VERSION "HNNBNNNYNNNNNNNNNNNNNNNNNNNNNNNNNNNNNNNNNN/4/%%%/4/'%**4NNN///"

NS_ :

BS_:

BU_: BAP_Tester conBox Gateway Gateway_PAG OTA_FC

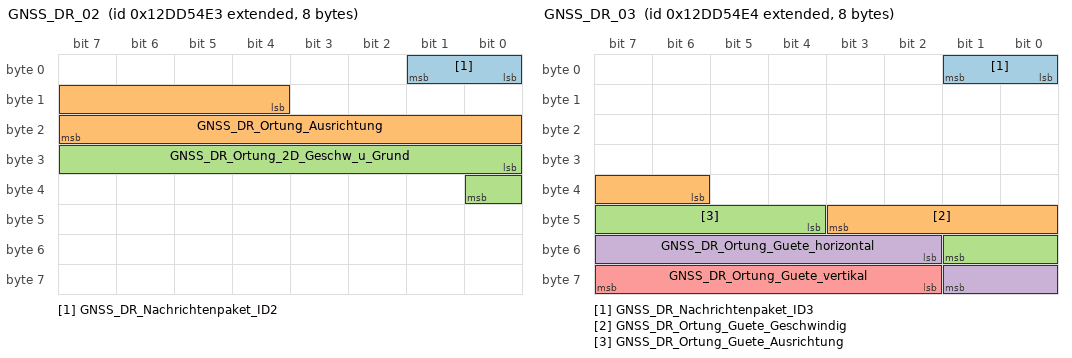
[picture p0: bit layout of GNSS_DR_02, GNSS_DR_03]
BO_ 2463978723 GNSS_DR_02: 8 conBox
 SG_ GNSS_DR_Nachrichtenpaket_ID2 : 0|2@1+ (1,0) [0|3] "Unit_Bit"  Gateway,Gateway_PAG
 SG_ GNSS_DR_Ortung_Ausrichtung : 12|12@1+ (0.1,0) [0.0|359.9] "Unit_DegreOfArc"  Gateway,Gateway_PAG
 SG_ GNSS_DR_Ortung_2D_Geschw_u_Grund : 24|9@1+ (0.25,0) [0.00|125.00] "Unit_MeterPerSecon"  Gateway,Gateway_PAG

BO_ 2463978724 GNSS_DR_03: 8 conBox
 SG_ GNSS_DR_Nachrichtenpaket_ID3 : 0|2@1+ (1,0) [0|3] "Unit_Bit"  Gateway,Gateway_PAG
 SG_ GNSS_DR_Ortung_Guete_Geschwindig : 38|6@1+ (0.05,0) [0.00|3.05] "Unit_MeterPerSecon"  Gateway,Gateway_PAG
 SG_ GNSS_DR_Ortung_Guete_Ausrichtung : 44|6@1+ (0.15,0) [0.00|9.15] "Unit_DegreOfArc"  Gateway,Gateway_PAG
 SG_ GNSS_DR_Ortung_Guete_horizontal : 50|8@1+ (1,0) [0|250] "Unit_Meter"  Gateway,Gateway_PAG
 SG_ GNSS_DR_Ortung_Guete_vertikal : 58|6@1+ (2,0) [0|122] "Unit_Meter"  Gateway,Gateway_PAG

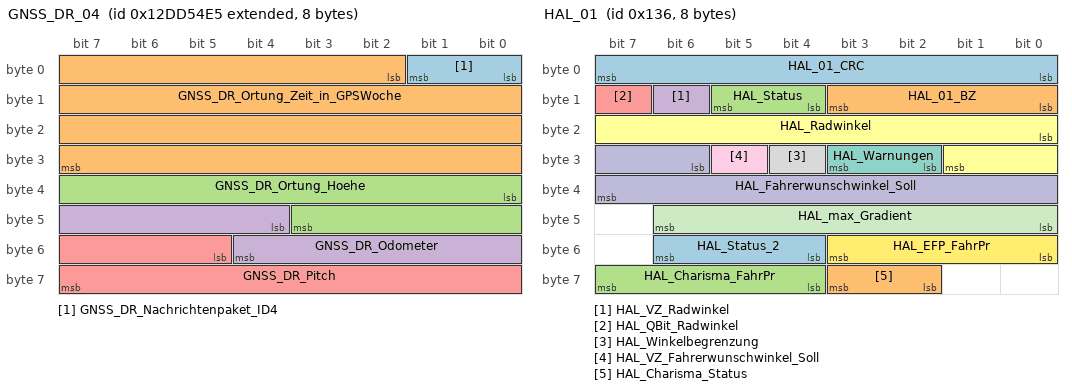
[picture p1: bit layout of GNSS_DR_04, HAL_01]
BO_ 2463978725 GNSS_DR_04: 8 conBox
 SG_ GNSS_DR_Nachrichtenpaket_ID4 : 0|2@1+ (1,0) [0|3] "Unit_Bit"  Gateway,Gateway_PAG
 SG_ GNSS_DR_Ortung_Zeit_in_GPSWoche : 2|30@1+ (1,0) [0|604800001] "Unit_MilliSecon"  Gateway,Gateway_PAG
 SG_ GNSS_DR_Ortung_Hoehe : 32|12@1+ (2,-500) [-500|7686] "Unit_Meter"  Gateway,Gateway_PAG
 SG_ GNSS_DR_Odometer : 44|9@1+ (2,0) [0|1018] "Unit_MilliMeter"  Gateway,Gateway_PAG
 SG_ GNSS_DR_Pitch : 53|11@1+ (0.05,-51.2) [-51.20|51.05] "Unit_DegreOfArc"  Gateway,Gateway_PAG

BO_ 2463978726 GNSS_DR_05: 8 conBox
 SG_ GNSS_DR_UTC_Zeit : 0|32@1+ (1,0) [1|4294967295] "Unit_Secon"  Gateway,Gateway_PAG
 SG_ GNSS_DR_Nachrichtenpaket_ID5 : 32|2@1+ (1,0) [0|3] "Unit_Bit"  Gateway,Gateway_PAG

BO_ 310 HAL_01: 8 Gateway
 SG_ HAL_01_CRC : 0|8@1+ (1,0) [0|255] ""  Vector__XXX
 SG_ HAL_01_BZ : 8|4@1+ (1,0) [0|15] ""  Vector__XXX
 SG_ HAL_Status : 12|2@1+ (1.0,0.0) [0.0|3] ""  Vector__XXX
 SG_ HAL_VZ_Radwinkel : 14|1@1+ (1.0,0.0) [0.0|1] ""  conBox
 SG_ HAL_QBit_Radwinkel : 15|1@1+ (1.0,0.0) [0.0|1] ""  Vector__XXX
 SG_ HAL_Radwinkel : 16|10@1+ (0.01,0) [0.00|10.19] "Unit_DegreOfArc"  conBox
 SG_ HAL_Warnungen : 26|2@1+ (1.0,0.0) [0.0|3] ""  Vector__XXX
 SG_ HAL_Winkelbegrenzung : 28|1@1+ (1.0,0.0) [0.0|1] ""  Vector__XXX
 SG_ HAL_VZ_Fahrerwunschwinkel_Soll : 29|1@1+ (1.0,0.0) [0.0|1] ""  Vector__XXX
 SG_ HAL_Fahrerwunschwinkel_Soll : 30|10@1+ (0.01,0) [0.00|10.21] "Unit_DegreOfArc"  Vector__XXX
 SG_ HAL_max_Gradient : 40|7@1+ (0.1,0) [0.0|12.5] "Unit_DegreOfArcPerSecon"  Vector__XXX
 SG_ HAL_EFP_FahrPr : 48|4@1+ (1.0,0.0) [0.0|15] ""  Vector__XXX
 SG_ HAL_Status_2 : 52|3@1+ (1.0,0.0) [0.0|7] ""  Vector__XXX
 SG_ HAL_Charisma_Status : 58|2@1+ (1.0,0.0) [0.0|3] ""  Vector__XXX
 SG_ HAL_Charisma_FahrPr : 60|4@1+ (1.0,0.0) [0.0|15] ""  Vector__XXX

BO_ 29 IMMO_Auth_Master_Slave07: 8 Gateway
 SG_ IMMO_Auth_Master_Slave07_Sig1 : 0|64@1+ (1.0,0.0) [0.0|18446744073709551615] ""  conBox

BO_ 28 IMMO_Auth_Slave07_Master: 8 conBox
 SG_ IMMO_Auth_Slave07_Master_Sig1 : 0|64@1+ (1.0,0.0) [0.0|18446744073709551615] ""  Gateway,Gateway_PAG

BO_ 960 Klemmen_Status_01: 4 Gateway
 SG_ Klemmen_Status_01_CRC : 0|8@1+ (1,0) [0|255] ""  Vector__XXX
 SG_ Klemmen_Status_01_BZ : 8|4@1+ (1,0) [0|15] ""  Vector__XXX
 SG_ RSt_Fahrerhinweise : 12|4@1+ (1.0,0.0) [0.0|15] ""  Vector__XXX
 SG_ ZAS_Kl_S : 16|1@1+ (1.0,0.0) [0.0|1] ""  conBox
 SG_ ZAS_Kl_15 : 17|1@1+ (1.0,0.0) [0.0|1] ""  conBox
 SG_ ZAS_Kl_X : 18|1@1+ (1.0,0.0) [0.0|1] ""  Vector__XXX
 SG_ ZAS_Kl_50_Startanforderung : 19|1@1+ (1.0,0.0) [0.0|1] ""  Vector__XXX
 SG_ BCM_Remotestart_Betrieb : 20|1@1+ (1.0,0.0) [0.0|1] ""  Vector__XXX
 SG_ ZAS_Kl_Infotainment : 21|1@1+ (1.0,0.0) [0.0|1] ""  Vector__XXX
 SG_ BCM_Remotestart_KL15_Anf : 22|1@1+ (1.0,0.0) [0.0|1] ""  Vector__XXX
 SG_ BCM_Remotestart_MO_Start : 23|1@1+ (1.0,0.0) [0.0|1] ""  Vector__XXX
 SG_ KST_Warn_P1_ZST_def : 24|1@1+ (1.0,0.0) [0.0|1] ""  Vector__XXX
 SG_ KST_Warn_P2_ZST_def : 25|1@1+ (1.0,0.0) [0.0|1] ""  Vector__XXX
 SG_ KST_Fahrerhinweis_1 : 26|1@1+ (1.0,0.0) [0.0|1] ""  Vector__XXX
 SG_ KST_Fahrerhinweis_2 : 27|1@1+ (1.0,0.0) [0.0|1] ""  Vector__XXX
 SG_ BCM_Ausparken_Betrieb : 28|1@1+ (1.0,0.0) [0.0|1] ""  Vector__XXX
 SG_ KST_Fahrerhinweis_4 : 29|1@1+ (1.0,0.0) [0.0|1] ""  Vector__XXX
 SG_ KST_Fahrerhinweis_5 : 30|1@1+ (1.0,0.0) [0.0|1] ""  Vector__XXX
 SG_ KST_Fahrerhinweis_6 : 31|1@1+ (1.0,0.0) [0.0|1] ""  Vector__XXX

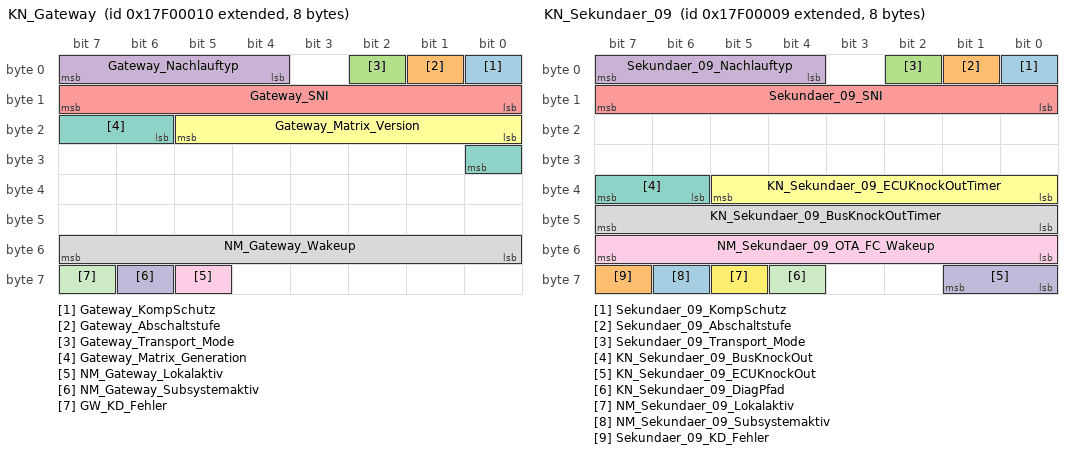
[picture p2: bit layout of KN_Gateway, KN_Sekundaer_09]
BO_ 2549088272 KN_Gateway: 8 Gateway
 SG_ Gateway_KompSchutz : 0|1@1+ (1.0,0.0) [0.0|1] ""  Vector__XXX
 SG_ Gateway_Abschaltstufe : 1|1@1+ (1.0,0.0) [0.0|1] ""  Vector__XXX
 SG_ Gateway_Transport_Mode : 2|1@1+ (1.0,0.0) [0.0|1] ""  Vector__XXX
 SG_ Gateway_Nachlauftyp : 4|4@1+ (1.0,0.0) [0.0|15] ""  Vector__XXX
 SG_ Gateway_SNI : 8|8@1+ (1.0,0.0) [0.0|255] ""  Vector__XXX
 SG_ Gateway_Matrix_Version : 16|6@1+ (1,0) [0|63] "Unit_None"  Vector__XXX
 SG_ Gateway_Matrix_Generation : 22|3@1+ (1,0) [0|7] "Unit_None"  Vector__XXX
 SG_ NM_Gateway_Wakeup : 48|8@1+ (1.0,0.0) [0.0|255] ""  Vector__XXX
 SG_ NM_Gateway_Lokalaktiv : 61|1@1+ (1.0,0.0) [0.0|1] ""  Vector__XXX
 SG_ NM_Gateway_Subsystemaktiv : 62|1@1+ (1.0,0.0) [0.0|1] ""  Vector__XXX
 SG_ GW_KD_Fehler : 63|1@1+ (1.0,0.0) [0.0|1] ""  Vector__XXX

BO_ 2549088265 KN_Sekundaer_09: 8 OTA_FC
 SG_ Sekundaer_09_KompSchutz : 0|1@1+ (1.0,0.0) [0.0|1] ""  Vector__XXX
 SG_ Sekundaer_09_Abschaltstufe : 1|1@1+ (1.0,0.0) [0.0|1] ""  Vector__XXX
 SG_ Sekundaer_09_Transport_Mode : 2|1@1+ (1.0,0.0) [0.0|1] ""  Vector__XXX
 SG_ Sekundaer_09_Nachlauftyp : 4|4@1+ (1.0,0.0) [0.0|15] ""  Gateway_PAG
 SG_ Sekundaer_09_SNI : 8|8@1+ (1.0,0.0) [0.0|255] ""  Gateway_PAG
 SG_ KN_Sekundaer_09_ECUKnockOutTimer : 32|6@1+ (1,0) [0|62] "Unit_Minut"  Gateway_PAG
 SG_ KN_Sekundaer_09_BusKnockOut : 38|2@1+ (1.0,0.0) [0.0|3] ""  Gateway_PAG
 SG_ KN_Sekundaer_09_BusKnockOutTimer : 40|8@1+ (1,0) [0|254] ""  Gateway_PAG
 SG_ NM_Sekundaer_09_OTA_FC_Wakeup : 48|8@1+ (1.0,0.0) [0.0|255] ""  Vector__XXX
 SG_ KN_Sekundaer_09_ECUKnockOut : 56|2@1+ (1.0,0.0) [0.0|3] ""  Gateway_PAG
 SG_ KN_Sekundaer_09_DiagPfad : 60|1@1+ (1.0,0.0) [0.0|1] ""  Vector__XXX
 SG_ NM_Sekundaer_09_Lokalaktiv : 61|1@1+ (1.0,0.0) [0.0|1] ""  Gateway_PAG
 SG_ NM_Sekundaer_09_Subsystemaktiv : 62|1@1+ (1.0,0.0) [0.0|1] ""  Gateway_PAG
 SG_ Sekundaer_09_KD_Fehler : 63|1@1+ (1.0,0.0) [0.0|1] ""  Gateway_PAG

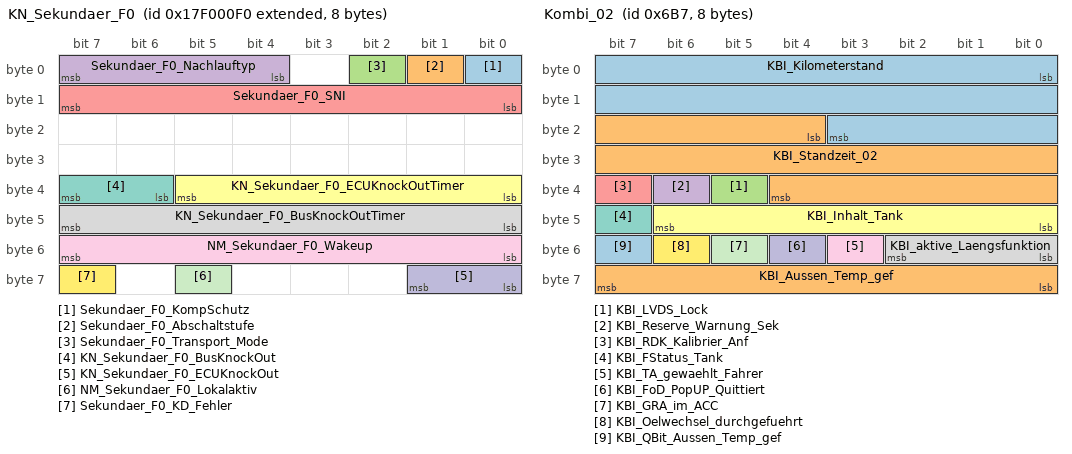
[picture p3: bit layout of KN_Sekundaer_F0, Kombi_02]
BO_ 2549088496 KN_Sekundaer_F0: 8 conBox
 SG_ Sekundaer_F0_KompSchutz : 0|1@1+ (1.0,0.0) [0.0|1] ""  Vector__XXX
 SG_ Sekundaer_F0_Abschaltstufe : 1|1@1+ (1.0,0.0) [0.0|1] ""  Vector__XXX
 SG_ Sekundaer_F0_Transport_Mode : 2|1@1+ (1.0,0.0) [0.0|1] ""  Vector__XXX
 SG_ Sekundaer_F0_Nachlauftyp : 4|4@1+ (1.0,0.0) [0.0|15] ""  Gateway,Gateway_PAG
 SG_ Sekundaer_F0_SNI : 8|8@1+ (1.0,0.0) [0.0|255] ""  Gateway,Gateway_PAG
 SG_ KN_Sekundaer_F0_ECUKnockOutTimer : 32|6@1+ (1,0) [0|62] "Unit_Minut"  Gateway,Gateway_PAG
 SG_ KN_Sekundaer_F0_BusKnockOut : 38|2@1+ (1.0,0.0) [0.0|3] ""  Gateway,Gateway_PAG
 SG_ KN_Sekundaer_F0_BusKnockOutTimer : 40|8@1+ (1,0) [0|254] ""  Gateway,Gateway_PAG
 SG_ NM_Sekundaer_F0_Wakeup : 48|8@1+ (1.0,0.0) [0.0|255] ""  Gateway
 SG_ KN_Sekundaer_F0_ECUKnockOut : 56|2@1+ (1.0,0.0) [0.0|3] ""  Gateway,Gateway_PAG
 SG_ NM_Sekundaer_F0_Lokalaktiv : 61|1@1+ (1.0,0.0) [0.0|1] ""  Gateway,Gateway_PAG
 SG_ Sekundaer_F0_KD_Fehler : 63|1@1+ (1.0,0.0) [0.0|1] ""  Gateway,Gateway_PAG

BO_ 779 Kombi_01: 8 Gateway
 SG_ KBI_ABS_Lampe : 0|1@1+ (1.0,0.0) [0.0|1] ""  Vector__XXX
 SG_ KBI_ESP_Lampe : 1|1@1+ (1.0,0.0) [0.0|1] ""  Vector__XXX
 SG_ KBI_BKL_Lampe : 2|1@1+ (1.0,0.0) [0.0|1] ""  Vector__XXX
 SG_ KBI_Airbag_Lampe : 3|1@1+ (1.0,0.0) [0.0|1] ""  Vector__XXX
 SG_ KBI_SILA_gueltig : 4|1@1+ (1.0,0.0) [0.0|1] ""  Vector__XXX
 SG_ KBI_Lenkung_Lampe : 5|1@1+ (1,0) [0|1] ""  Vector__XXX
 SG_ KBI_Vorglueh_System_Lampe : 6|1@1+ (1.0,0.0) [0.0|1] ""  Vector__XXX
 SG_ KBI_NV_in_Anzeige : 7|1@1+ (1.0,0.0) [0.0|1] ""  Vector__XXX
 SG_ Kombi_01_BZ : 8|4@1+ (1,0) [0|15] ""  Vector__XXX
 SG_ KBI_Anzeigestatus_ACC : 12|1@1+ (1.0,0.0) [0.0|1] ""  Vector__XXX
 SG_ KBI_Anzeigestatus_GRA : 13|2@1+ (1.0,0.0) [0.0|3] ""  Vector__XXX
 SG_ KBI_Tankwarnung : 16|1@1+ (1.0,0.0) [0.0|1] ""  Vector__XXX
 SG_ KBI_MFA_v_Einheit_01 : 17|1@1+ (1.0,0.0) [0.0|1] ""  Vector__XXX
 SG_ KBI_im_Stellgliedtest : 18|1@1+ (1.0,0.0) [0.0|1] ""  Vector__XXX
 SG_ KBI_Anzeigefehler_LDW : 19|2@1+ (1.0,0.0) [0.0|3] ""  Vector__XXX
 SG_ KBI_Tankwarnung_ungueltig : 21|1@1+ (1.0,0.0) [0.0|1] ""  Vector__XXX
 SG_ KBI_Handbremse : 23|1@1+ (1.0,0.0) [0.0|1] ""  Vector__XXX
 SG_ KBI_V_Digital : 24|9@1+ (1,0) [0|511] ""  Vector__XXX
 SG_ KBI_PLA_in_Anzeige : 33|1@1+ (1.0,0.0) [0.0|1] ""  Vector__XXX
 SG_ KBI_Anzeigefehler_NV : 34|1@1+ (1.0,0.0) [0.0|1] ""  Vector__XXX
 SG_ KBI_Anzeigestatus_LIM : 35|2@1+ (1.0,0.0) [0.0|3] ""  Vector__XXX
 SG_ KBI_ARA_in_Anzeige : 37|1@1+ (1.0,0.0) [0.0|1] ""  Vector__XXX
 SG_ KBI_Taster_Lift : 38|1@1+ (1.0,0.0) [0.0|1] ""  Vector__XXX
 SG_ KBI_Taster_Fahrwerk : 39|1@1+ (1.0,0.0) [0.0|1] ""  Vector__XXX
 SG_ KBI_GRA_Hauptschalter : 40|2@1+ (1.0,0.0) [0.0|3] ""  Vector__XXX
 SG_ KBI_Bestaetigung_ESP_Off : 42|2@1+ (1.0,0.0) [0.0|3] ""  Vector__XXX
 SG_ KBI_angez_Geschw : 48|10@1+ (0.32,0) [0.00|325.12] "Unit_KiloMeterPerHour"  conBox
 SG_ KBI_Einheit_Tacho : 58|1@1+ (1.0,0.0) [0.0|1] ""  conBox
 SG_ KBI_Konsistenz_ACC : 59|1@1+ (1.0,0.0) [0.0|1] ""  Vector__XXX
 SG_ KBI_Fehler_Anzeige_ACC : 60|1@1+ (1.0,0.0) [0.0|1] ""  Vector__XXX
 SG_ KBI_Anzeigefehler_SWA : 61|2@1+ (1.0,0.0) [0.0|3] ""  Vector__XXX
 SG_ KBI_Systemstatus : 63|1@1+ (1.0,0.0) [0.0|1] ""  Vector__XXX

BO_ 1719 Kombi_02: 8 Gateway
 SG_ KBI_Kilometerstand : 0|20@1+ (1,0) [0|1048573] "Unit_KiloMeter"  Vector__XXX
 SG_ KBI_Standzeit_02 : 20|17@1+ (1,0) [0|131068] "Unit_Secon"  Vector__XXX
 SG_ KBI_LVDS_Lock : 37|1@1+ (1.0,0.0) [0.0|1] ""  Vector__XXX
 SG_ KBI_Reserve_Warnung_Sek : 38|1@1+ (1.0,0.0) [0.0|1] ""  Vector__XXX
 SG_ KBI_RDK_Kalibrier_Anf : 39|1@1+ (1.0,0.0) [0.0|1] ""  Vector__XXX
 SG_ KBI_Inhalt_Tank : 40|7@1+ (1,0) [0|125] "Unit_Liter"  conBox
 SG_ KBI_FStatus_Tank : 47|1@1+ (1.0,0.0) [0.0|1] ""  conBox
 SG_ KBI_aktive_Laengsfunktion : 48|3@1+ (1.0,0.0) [0.0|7] ""  Vector__XXX
 SG_ KBI_TA_gewaehlt_Fahrer : 51|1@1+ (1.0,0.0) [0.0|1] ""  Vector__XXX
 SG_ KBI_FoD_PopUP_Quittiert : 52|1@1+ (1.0,0.0) [0.0|1] ""  Vector__XXX
 SG_ KBI_GRA_im_ACC : 53|1@1+ (1.0,0.0) [0.0|1] ""  Vector__XXX
 SG_ KBI_Oelwechsel_durchgefuehrt : 54|1@1+ (1.0,0.0) [0.0|1] ""  Vector__XXX
 SG_ KBI_QBit_Aussen_Temp_gef : 55|1@1+ (1.0,0.0) [0.0|1] ""  Vector__XXX
 SG_ KBI_Aussen_Temp_gef : 56|8@1+ (0.5,-50) [-50.0|75.0] "Unit_DegreCelsi"  Vector__XXX

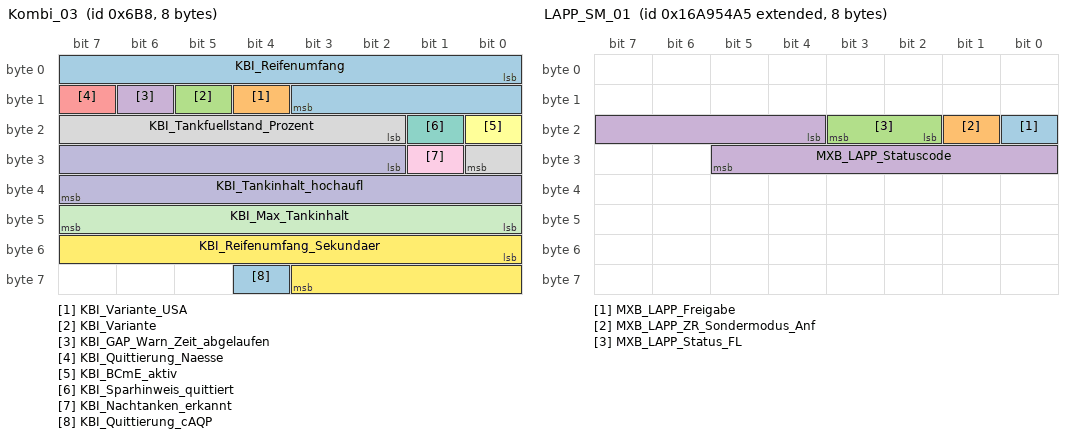
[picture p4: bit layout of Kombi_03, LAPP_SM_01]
BO_ 1720 Kombi_03: 8 Gateway
 SG_ KBI_Reifenumfang : 0|12@1+ (1,0) [0|4095] "Unit_MilliMeter"  Vector__XXX
 SG_ KBI_Variante_USA : 12|1@1+ (1.0,0.0) [0.0|1] ""  Vector__XXX
 SG_ KBI_Variante : 13|1@1+ (1.0,0.0) [0.0|1] ""  Vector__XXX
 SG_ KBI_GAP_Warn_Zeit_abgelaufen : 14|1@1+ (1.0,0.0) [0.0|1] ""  Vector__XXX
 SG_ KBI_Quittierung_Naesse : 15|1@1+ (1.0,0.0) [0.0|1] ""  Vector__XXX
 SG_ KBI_BCmE_aktiv : 16|1@1+ (1.0,0.0) [0.0|1] ""  Vector__XXX
 SG_ KBI_Sparhinweis_quittiert : 17|1@1+ (1.0,0.0) [0.0|1] ""  Vector__XXX
 SG_ KBI_Tankfuellstand_Prozent : 18|7@1+ (1,0) [0|100] "Unit_PerCent"  conBox
 SG_ KBI_Nachtanken_erkannt : 25|1@1+ (1.0,0.0) [0.0|1] ""  Vector__XXX
 SG_ KBI_Tankinhalt_hochaufl : 26|14@1+ (0.01,0) [0.00|163.81] "Unit_Liter"  Vector__XXX
 SG_ KBI_Max_Tankinhalt : 40|8@1+ (0.5,0) [0.0|126.5] ""  Vector__XXX
 SG_ KBI_Reifenumfang_Sekundaer : 48|12@1+ (1,0) [0|4095] "Unit_MilliMeter"  Vector__XXX
 SG_ KBI_Quittierung_cAQP : 60|1@1+ (1.0,0.0) [0.0|1] ""  Vector__XXX

BO_ 2549875047 KS_eCall_Req: 8 Gateway
 SG_ KS_eCall_Req_Data : 0|64@1+ (1.0,0.0) [0.0|18446744073709551615] ""  conBox

BO_ 2550006119 KS_eCall_Resp: 8 conBox
 SG_ KS_eCall_Resp_Data : 0|64@1+ (1.0,0.0) [0.0|18446744073709551615] ""  Gateway,Gateway_PAG

BO_ 2549875078 KS_OTA_FC_Req: 8 Gateway_PAG
 SG_ KS_OTA_FC_Req_Data : 0|64@1+ (1.0,0.0) [0.0|18446744073709551615] ""  OTA_FC

BO_ 2550006150 KS_OTA_FC_Resp: 8 OTA_FC
 SG_ KS_OTA_FC_Resp_Data : 0|64@1+ (1.0,0.0) [0.0|18446744073709551615] ""  Gateway_PAG

BO_ 2527679653 LAPP_SM_01: 8 Gateway
 SG_ MXB_LAPP_Freigabe : 16|1@1+ (1.0,0.0) [0.0|1] ""  conBox
 SG_ MXB_LAPP_ZR_Sondermodus_Anf : 17|1@1+ (1.0,0.0) [0.0|1] ""  Vector__XXX
 SG_ MXB_LAPP_Status_FL : 18|2@1+ (1.0,0.0) [0.0|3] ""  conBox
 SG_ MXB_LAPP_Statuscode : 20|10@1+ (1,0) [0|1023] "Unit_None"  conBox

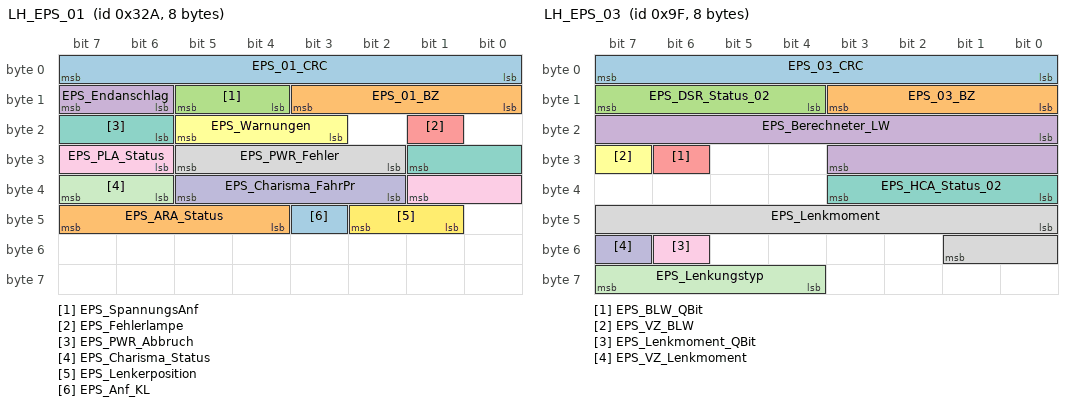
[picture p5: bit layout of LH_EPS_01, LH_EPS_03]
BO_ 810 LH_EPS_01: 8 Gateway
 SG_ EPS_01_CRC : 0|8@1+ (1,0) [0|255] ""  Vector__XXX
 SG_ EPS_01_BZ : 8|4@1+ (1,0) [0|15] ""  Vector__XXX
 SG_ EPS_SpannungsAnf : 12|2@1+ (1.0,0.0) [0.0|3] ""  Vector__XXX
 SG_ EPS_Endanschlag : 14|2@1+ (1.0,0.0) [0.0|3] ""  Vector__XXX
 SG_ EPS_Fehlerlampe : 17|1@1+ (1.0,0.0) [0.0|1] ""  Vector__XXX
 SG_ EPS_Warnungen : 19|3@1+ (1.0,0.0) [0.0|7] ""  Vector__XXX
 SG_ EPS_PWR_Abbruch : 22|4@1+ (1.0,0.0) [0.0|15] ""  Vector__XXX
 SG_ EPS_PWR_Fehler : 26|4@1+ (1.0,0.0) [0.0|15] ""  Vector__XXX
 SG_ EPS_PLA_Status : 30|4@1+ (1.0,0.0) [0.0|15] ""  Vector__XXX
 SG_ EPS_Charisma_FahrPr : 34|4@1+ (1.0,0.0) [0.0|15] ""  Vector__XXX
 SG_ EPS_Charisma_Status : 38|2@1+ (1.0,0.0) [0.0|3] ""  Vector__XXX
 SG_ EPS_Lenkerposition : 41|2@1+ (1.0,0.0) [0.0|3] ""  conBox
 SG_ EPS_Anf_KL : 43|1@1+ (1.0,0.0) [0.0|1] ""  Vector__XXX
 SG_ EPS_ARA_Status : 44|4@1+ (1.0,0.0) [0.0|15] ""  Vector__XXX

BO_ 159 LH_EPS_03: 8 Gateway
 SG_ EPS_03_CRC : 0|8@1+ (1,0) [0|255] ""  Vector__XXX
 SG_ EPS_03_BZ : 8|4@1+ (1,0) [0|15] ""  Vector__XXX
 SG_ EPS_DSR_Status_02 : 12|4@1+ (1.0,0.0) [0.0|15] ""  Vector__XXX
 SG_ EPS_Berechneter_LW : 16|12@1+ (0.15,0) [0.00|613.95] "Unit_DegreOfArc"  conBox
 SG_ EPS_BLW_QBit : 30|1@1+ (1.0,0.0) [0.0|1] ""  Vector__XXX
 SG_ EPS_VZ_BLW : 31|1@1+ (1.0,0.0) [0.0|1] ""  conBox
 SG_ EPS_HCA_Status_02 : 32|4@1+ (1.0,0.0) [0.0|15] ""  Vector__XXX
 SG_ EPS_Lenkmoment : 40|10@1+ (0.01,0) [0.00|8.00] "Unit_NewtoMeter"  Vector__XXX
 SG_ EPS_Lenkmoment_QBit : 54|1@1+ (1.0,0.0) [0.0|1] ""  Vector__XXX
 SG_ EPS_VZ_Lenkmoment : 55|1@1+ (1.0,0.0) [0.0|1] ""  Vector__XXX
 SG_ EPS_Lenkungstyp : 60|4@1+ (1.0,0.0) [0.0|15] ""  Vector__XXX

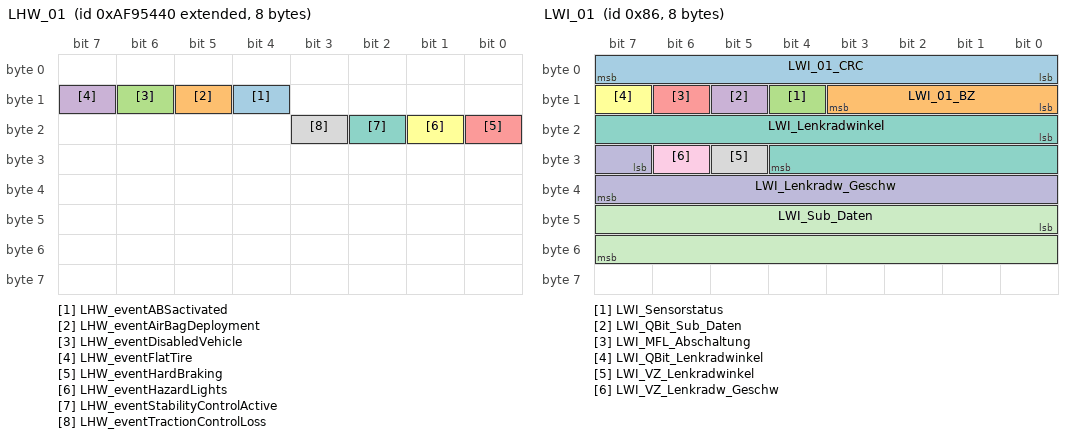
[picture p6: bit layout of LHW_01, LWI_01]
BO_ 2331595840 LHW_01: 8 Gateway
 SG_ LHW_eventABSactivated : 12|1@1+ (1.0,0.0) [0.0|1] ""  conBox
 SG_ LHW_eventAirBagDeployment : 13|1@1+ (1.0,0.0) [0.0|1] ""  conBox
 SG_ LHW_eventDisabledVehicle : 14|1@1+ (1.0,0.0) [0.0|1] ""  conBox
 SG_ LHW_eventFlatTire : 15|1@1+ (1.0,0.0) [0.0|1] ""  conBox
 SG_ LHW_eventHardBraking : 16|1@1+ (1.0,0.0) [0.0|1] ""  conBox
 SG_ LHW_eventHazardLights : 17|1@1+ (1.0,0.0) [0.0|1] ""  conBox
 SG_ LHW_eventStabilityControlActive : 18|1@1+ (1.0,0.0) [0.0|1] ""  conBox
 SG_ LHW_eventTractionControlLoss : 19|1@1+ (1.0,0.0) [0.0|1] ""  conBox

BO_ 981 Licht_Anf_01: 8 Gateway
 SG_ Licht_Anf_01_CRC : 0|8@1+ (1,0) [0|255] ""  Vector__XXX
 SG_ Licht_Anf_01_BZ : 8|4@1+ (1,0) [0|15] ""  Vector__XXX
 SG_ BCM1_Kurvenlicht_links_Anf : 12|1@1+ (1.0,0.0) [0.0|1] ""  Vector__XXX
 SG_ BCM1_Kurvenlicht_rechts_Anf : 13|1@1+ (1.0,0.0) [0.0|1] ""  Vector__XXX
 SG_ BCM1_Standlicht_Anf : 14|1@1+ (1.0,0.0) [0.0|1] ""  conBox
 SG_ BCM1_Abblendlicht_Anf : 15|1@1+ (1.0,0.0) [0.0|1] ""  conBox
 SG_ BCM1_Fernlicht_Anf : 16|1@1+ (1.0,0.0) [0.0|1] ""  Vector__XXX
 SG_ BCM1_Nebellicht_Anf : 17|1@1+ (1.0,0.0) [0.0|1] ""  conBox
 SG_ BCM1_Parklicht_li_Anf : 18|1@1+ (1.0,0.0) [0.0|1] ""  conBox
 SG_ BCM1_Parklicht_re_Anf : 19|1@1+ (1.0,0.0) [0.0|1] ""  conBox
 SG_ BCM1_Nebelschluss_Ahg_Anf : 20|1@1+ (1.0,0.0) [0.0|1] ""  conBox
 SG_ BCM1_Nebelschluss_Fzg_Anf : 21|1@1+ (1.0,0.0) [0.0|1] ""  Vector__XXX
 SG_ BCM1_Schlusslicht_Anf : 22|1@1+ (1.0,0.0) [0.0|1] ""  Vector__XXX
 SG_ BCM_Rueckfahrlicht_Anf : 23|1@1+ (1.0,0.0) [0.0|1] ""  conBox
 SG_ BCM1_Signaturlicht_Anf : 24|1@1+ (1.0,0.0) [0.0|1] ""  Vector__XXX
 SG_ BCM1_Umfeldleuchten_Anf : 25|1@1+ (1.0,0.0) [0.0|1] ""  Vector__XXX
 SG_ BCM1_Tagfahrlicht_Anf : 26|1@1+ (1.0,0.0) [0.0|1] ""  conBox
 SG_ BCM1_Regenlicht_Anf : 27|1@1+ (1.0,0.0) [0.0|1] ""  Vector__XXX
 SG_ BCM1_Autobahnlicht_Anf : 28|1@1+ (1.0,0.0) [0.0|1] ""  Vector__XXX
 SG_ BCM1_Touristen_Licht_Anf : 29|1@1+ (1.0,0.0) [0.0|1] ""  Vector__XXX
 SG_ BCM1_CH_aktiv : 30|1@1+ (1.0,0.0) [0.0|1] ""  Vector__XXX
 SG_ BCM1_LH_aktiv : 31|1@1+ (1.0,0.0) [0.0|1] ""  Vector__XXX
 SG_ BCM1_Gleitende_Leuchtw_Anf : 32|1@1+ (1.0,0.0) [0.0|1] ""  Vector__XXX
 SG_ BCM1_GLW_Fernlicht_Anf : 33|1@1+ (1.0,0.0) [0.0|1] ""  Vector__XXX
 SG_ BCM1_Adaptive_Lichtvert_Anf : 34|1@1+ (1.0,0.0) [0.0|1] ""  Vector__XXX
 SG_ BCM1_FoD_Sperrung_WiBli : 35|2@1+ (1.0,0.0) [0.0|3] ""  Vector__XXX
 SG_ BCM1_FOD_Sperrung_Animationen_HL : 37|2@1+ (1.0,0.0) [0.0|3] ""  Vector__XXX
 SG_ BCM1_Animationssperrung : 39|1@1+ (1.0,0.0) [0.0|1] ""  Vector__XXX
 SG_ BCM1_CH_LH_aktiv : 40|1@1+ (1.0,0.0) [0.0|1] ""  Vector__XXX
 SG_ BCM1_Allwetterlicht_Anf : 41|1@1+ (1.0,0.0) [0.0|1] ""  Vector__XXX
 SG_ BCM1_Schlusslicht_Signatur : 60|4@1+ (1.0,0.0) [0.0|15] ""  Vector__XXX

BO_ 1624 Licht_vorne_01: 8 Gateway
 SG_ Licht_Vorne_01_CRC : 0|8@1+ (1,0) [0|255] ""  Vector__XXX
 SG_ Licht_Vorne_01_BZ : 8|4@1+ (1,0) [0|15] ""  Vector__XXX
 SG_ LV_Standlicht_Anzeige : 12|1@1+ (1.0,0.0) [0.0|1] ""  Vector__XXX
 SG_ LV_Abblendlicht_Anzeige : 13|1@1+ (1.0,0.0) [0.0|1] ""  Vector__XXX
 SG_ LV_Fernlicht_Anzeige : 14|1@1+ (1.0,0.0) [0.0|1] ""  conBox
 SG_ LV_Nebellicht_Anzeige : 15|1@1+ (1.0,0.0) [0.0|1] ""  Vector__XXX
 SG_ LV_Nebelschlusslicht_Anzeige : 16|1@1+ (1.0,0.0) [0.0|1] ""  Vector__XXX
 SG_ LV_Tagfahrlicht_Anzeige : 17|1@1+ (1.0,0.0) [0.0|1] ""  Vector__XXX
 SG_ LV_AFL_aktiv_Anzeige : 18|1@1+ (1.0,0.0) [0.0|1] ""  conBox
 SG_ LV_AFL_defekt : 19|1@1+ (1.0,0.0) [0.0|1] ""  Vector__XXX
 SG_ LV_Blinker_li_def : 20|1@1+ (1.0,0.0) [0.0|1] ""  Vector__XXX
 SG_ LV_Standlicht_li_def : 21|1@1+ (1.0,0.0) [0.0|1] ""  Vector__XXX
 SG_ LV_Abblendlicht_li_def : 22|1@1+ (1.0,0.0) [0.0|1] ""  Vector__XXX
 SG_ LV_Fernlicht_li_def : 23|1@1+ (1.0,0.0) [0.0|1] ""  Vector__XXX
 SG_ LV_Nebellicht_li_def : 24|1@1+ (1.0,0.0) [0.0|1] ""  Vector__XXX
 SG_ LV_Blk_li_Seite_def : 25|1@1+ (1.0,0.0) [0.0|1] ""  Vector__XXX
 SG_ LV_Tagfahrlicht_li_def : 26|1@1+ (1.0,0.0) [0.0|1] ""  Vector__XXX
 SG_ LV_FLA_aktiv_Anzeige : 27|1@1+ (1.0,0.0) [0.0|1] ""  Vector__XXX
 SG_ LV_FLA_defekt : 28|1@1+ (1.0,0.0) [0.0|1] ""  Vector__XXX
 SG_ LV_FLA_Sensor_blockiert : 29|1@1+ (1.0,0.0) [0.0|1] ""  Vector__XXX
 SG_ LV_Blinker_re_def : 30|1@1+ (1.0,0.0) [0.0|1] ""  Vector__XXX
 SG_ LV_Standlicht_re_def : 31|1@1+ (1.0,0.0) [0.0|1] ""  Vector__XXX
 SG_ LV_Abblendlicht_re_def : 32|1@1+ (1.0,0.0) [0.0|1] ""  Vector__XXX
 SG_ LV_Fernlicht_re_def : 33|1@1+ (1.0,0.0) [0.0|1] ""  Vector__XXX
 SG_ LV_Nebellicht_re_def : 34|1@1+ (1.0,0.0) [0.0|1] ""  Vector__XXX
 SG_ LV_Blk_re_Seite_def : 35|1@1+ (1.0,0.0) [0.0|1] ""  Vector__XXX
 SG_ LV_Tagfahrlicht_re_def : 36|1@1+ (1.0,0.0) [0.0|1] ""  Vector__XXX
 SG_ LV_Aussenlicht_def : 37|1@1+ (1.0,0.0) [0.0|1] ""  Vector__XXX
 SG_ LV_Abblendlicht_TFL_li_def : 38|1@1+ (1.0,0.0) [0.0|1] ""  Vector__XXX
 SG_ LV_Nebellicht_TFL_li_def : 39|1@1+ (1.0,0.0) [0.0|1] ""  Vector__XXX
 SG_ LV_Standlicht_TFL_li_def : 40|1@1+ (1.0,0.0) [0.0|1] ""  Vector__XXX
 SG_ LV_Abblend_Fernlicht_li_def : 41|1@1+ (1.0,0.0) [0.0|1] ""  Vector__XXX
 SG_ LV_Abblendlicht_TFL_re_def : 42|1@1+ (1.0,0.0) [0.0|1] ""  Vector__XXX
 SG_ LV_Nebellicht_TFL_re_def : 43|1@1+ (1.0,0.0) [0.0|1] ""  Vector__XXX
 SG_ LV_Standlicht_TFL_re_def : 44|1@1+ (1.0,0.0) [0.0|1] ""  Vector__XXX
 SG_ LV_Abblend_Fernlicht_re_def : 45|1@1+ (1.0,0.0) [0.0|1] ""  Vector__XXX
 SG_ LV_Abbiegelicht_li_def : 46|1@1+ (1.0,0.0) [0.0|1] ""  Vector__XXX
 SG_ LV_Abbiegelicht_re_def : 47|1@1+ (1.0,0.0) [0.0|1] ""  Vector__XXX
 SG_ BCM1_Linksverkehr : 48|1@1+ (1.0,0.0) [0.0|1] ""  Vector__XXX
 SG_ BCM1_Licht_Dunkelheit_aktiv : 49|1@1+ (1.0,0.0) [0.0|1] ""  Vector__XXX
 SG_ LV_LED_Scheinwerfer_li_def : 50|1@1+ (1.0,0.0) [0.0|1] ""  Vector__XXX
 SG_ LV_LED_Scheinwerfer_re_def : 51|1@1+ (1.0,0.0) [0.0|1] ""  Vector__XXX
 SG_ LV_Blinker_VL_aktiv : 52|1@1+ (1.0,0.0) [0.0|1] ""  Vector__XXX
 SG_ LV_Blinker_VR_aktiv : 53|1@1+ (1.0,0.0) [0.0|1] ""  Vector__XXX
 SG_ LV_MXB_Status_Anzeige : 54|2@1+ (1.0,0.0) [0.0|3] ""  Vector__XXX

BO_ 134 LWI_01: 8 Gateway
 SG_ LWI_01_CRC : 0|8@1+ (1,0) [0|255] ""  Vector__XXX
 SG_ LWI_01_BZ : 8|4@1+ (1,0) [0|15] ""  Vector__XXX
 SG_ LWI_Sensorstatus : 12|1@1+ (1.0,0.0) [0.0|1] ""  Vector__XXX
 SG_ LWI_QBit_Sub_Daten : 13|1@1+ (1.0,0.0) [0.0|1] ""  Vector__XXX
 SG_ LWI_MFL_Abschaltung : 14|1@1+ (1.0,0.0) [0.0|1] ""  Vector__XXX
 SG_ LWI_QBit_Lenkradwinkel : 15|1@1+ (1.0,0.0) [0.0|1] ""  Vector__XXX
 SG_ LWI_Lenkradwinkel : 16|13@1+ (0.1,0) [0.0|800.0] "Unit_DegreOfArc"  conBox
 SG_ LWI_VZ_Lenkradwinkel : 29|1@1+ (1.0,0.0) [0.0|1] ""  conBox
 SG_ LWI_VZ_Lenkradw_Geschw : 30|1@1+ (1.0,0.0) [0.0|1] ""  Vector__XXX
 SG_ LWI_Lenkradw_Geschw : 31|9@1+ (5,0) [0|2500] "Unit_DegreOfArcPerSecon"  Vector__XXX
 SG_ LWI_Sub_Daten : 40|16@1+ (1,0) [0|65535] ""  Vector__XXX

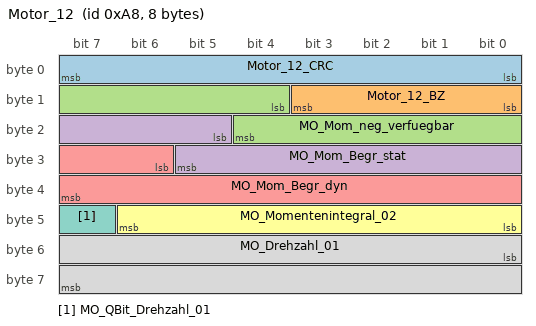
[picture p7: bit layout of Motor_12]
BO_ 168 Motor_12: 8 Gateway
 SG_ Motor_12_CRC : 0|8@1+ (1,0) [0|255] ""  Vector__XXX
 SG_ Motor_12_BZ : 8|4@1+ (1,0) [0|15] ""  Vector__XXX
 SG_ MO_Mom_neg_verfuegbar : 12|9@1+ (1,-509) [-509|0] ""  Vector__XXX
 SG_ MO_Mom_Begr_stat : 21|9@1+ (1,0) [0|509] ""  Vector__XXX
 SG_ MO_Mom_Begr_dyn : 30|10@1+ (1,-509) [-509|509] ""  Vector__XXX
 SG_ MO_Momentenintegral_02 : 40|7@1+ (1,0) [0|100] "Unit_PerCent"  Vector__XXX
 SG_ MO_QBit_Drehzahl_01 : 47|1@1+ (1.0,0.0) [0.0|1] ""  Vector__XXX
 SG_ MO_Drehzahl_01 : 48|16@1+ (0.25,0) [0.00|16383.00] "Unit_MinutInver"  conBox

BO_ 958 Motor_14: 8 Gateway
 SG_ Motor_14_CRC : 0|8@1+ (1,0) [0|255] ""  Vector__XXX
 SG_ Motor_14_BZ : 8|4@1+ (1,0) [0|15] ""  Vector__XXX
 SG_ MO_StartStopp_Status : 12|2@1+ (1.0,0.0) [0.0|3] ""  Vector__XXX
 SG_ MO_StartStopp_Wiederstart : 14|1@1+ (1.0,0.0) [0.0|1] ""  Vector__XXX
 SG_ MO_StartStopp_Motorstopp : 15|1@1+ (1.0,0.0) [0.0|1] ""  Vector__XXX
 SG_ MO_Freig_Reku : 16|2@1+ (1.0,0.0) [0.0|3] ""  Vector__XXX
 SG_ MO_Kl_75 : 18|1@1+ (1.0,0.0) [0.0|1] ""  conBox
 SG_ MO_Kl_50 : 19|1@1+ (1.0,0.0) [0.0|1] ""  conBox
 SG_ MO_Gangposition : 20|4@1+ (1.0,0.0) [0.0|15] ""  conBox
 SG_ MO_StartStopp_Fahrerwunsch : 24|2@1+ (1.0,0.0) [0.0|3] ""  Vector__XXX
 SG_ MO_HYB_Fahrbereitschaft : 26|1@1+ (1.0,0.0) [0.0|1] ""  Vector__XXX
 SG_ MO_Ext_E_Fahrt_aktiv : 27|1@1+ (1.0,0.0) [0.0|1] ""  Vector__XXX
 SG_ MO_Fahrer_bremst : 28|1@1+ (1.0,0.0) [0.0|1] ""  Vector__XXX
 SG_ MO_QBit_Fahrer_bremst : 29|1@1+ (1.0,0.0) [0.0|1] ""  Vector__XXX
 SG_ MO_BLS : 30|1@1+ (1.0,0.0) [0.0|1] ""  Vector__XXX
 SG_ MO_Konsistenz_Bremsped : 31|1@1+ (1.0,0.0) [0.0|1] ""  Vector__XXX
 SG_ MO_KomFehler_ESP : 32|1@1+ (1.0,0.0) [0.0|1] ""  Vector__XXX
 SG_ MO_Klima_Eingr : 33|2@1+ (1.0,0.0) [0.0|3] ""  Vector__XXX
 SG_ MO_Aussp_Anlass : 35|1@1+ (1.0,0.0) [0.0|1] ""  Vector__XXX
 SG_ MO_Freig_Anlass : 36|1@1+ (1.0,0.0) [0.0|1] ""  Vector__XXX
 SG_ MO_Kuppl_schalter : 37|1@1+ (1.0,0.0) [0.0|1] ""  Vector__XXX
 SG_ MO_Interlock : 38|1@1+ (1.0,0.0) [0.0|1] ""  Vector__XXX
 SG_ MO_Motor_laeuft : 39|1@1+ (1.0,0.0) [0.0|1] ""  conBox
 SG_ MO_Kickdown : 40|1@1+ (1.0,0.0) [0.0|1] ""  Vector__XXX
 SG_ MO_QBit_KL_75 : 41|1@1+ (1.0,0.0) [0.0|1] ""  Vector__XXX
 SG_ MO_EKlKomLeiRed : 42|2@1+ (1.0,0.0) [0.0|3] ""  Vector__XXX
 SG_ MO_Handshake_STH : 44|1@1+ (1.0,0.0) [0.0|1] ""  Vector__XXX
 SG_ MO_BKV_Unterdruckwarnung : 45|1@1+ (1.0,0.0) [0.0|1] ""  Vector__XXX
 SG_ MO_Freigabe_Segeln : 46|1@1+ (1.0,0.0) [0.0|1] ""  Vector__XXX
 SG_ MO_PTC_Status : 47|3@1+ (1.0,0.0) [0.0|7] ""  Vector__XXX
 SG_ MO_QBit_Gangposition : 50|1@1+ (1.0,0.0) [0.0|1] ""  Vector__XXX
 SG_ MO_Signalquelle_Gangposition : 51|1@1+ (1.0,0.0) [0.0|1] ""  Vector__XXX
 SG_ MO_Remotestart_Betrieb : 52|1@1+ (1.0,0.0) [0.0|1] ""  Vector__XXX
 SG_ MO_Remotestart_moeglich : 53|1@1+ (1.0,0.0) [0.0|1] ""  Vector__XXX
 SG_ MO_Text_Geschw_red : 54|1@1+ (1.0,0.0) [0.0|1] ""  Vector__XXX
 SG_ MO_FMAus_aktiv : 55|1@1+ (1.0,0.0) [0.0|1] ""  Vector__XXX
 SG_ MO_FMAus_Startvariante : 56|2@1+ (1.0,0.0) [0.0|3] ""  Vector__XXX
 SG_ MO_BMS_NV_Anf_stuetzen : 58|1@1+ (1.0,0.0) [0.0|1] ""  Vector__XXX
 SG_ MO_Zylinderabschaltung : 59|2@1+ (1.0,0.0) [0.0|3] ""  Vector__XXX
 SG_ MO_HYB_VM_aktiv : 61|1@1+ (1.0,0.0) [0.0|1] ""  Vector__XXX
 SG_ MO_StartVorauss_erfuellt : 62|2@1+ (1.0,0.0) [0.0|3] ""  Vector__XXX

BO_ 1648 Motor_18: 8 Gateway
 SG_ MO_max_Ladedruck : 0|6@1+ (0.1,0) [0.0|6.3] "Unit_Bar"  Vector__XXX
 SG_ MO_ANC_Kennfeld_Anf : 6|2@1+ (1.0,0.0) [0.0|3] ""  Vector__XXX
 SG_ MO_Bremslicht_Reku : 8|1@1+ (1.0,0.0) [0.0|1] ""  Vector__XXX
 SG_ MO_StartStopp_PopUp : 9|2@1+ (1.0,0.0) [0.0|3] ""  Vector__XXX
 SG_ MO1_Sperr_Info_WFS : 11|1@1+ (1.0,0.0) [0.0|1] ""  Vector__XXX
 SG_ MO1_Freigabe_Info_WFS : 12|1@1+ (1.0,0.0) [0.0|1] ""  Vector__XXX
 SG_ MO_EPCL : 13|3@1+ (1.0,0.0) [0.0|7] ""  Vector__XXX
 SG_ MO_Zylabsch_Texte_02 : 16|4@1+ (1.0,0.0) [0.0|15] ""  Vector__XXX
 SG_ MO_Fahrzeugtyp : 20|3@1+ (1.0,0.0) [0.0|7] ""  conBox
 SG_ MO_NMAX_Schaltanzeige : 23|9@1+ (25,0) [0|12775] "Unit_MinutInver"  Vector__XXX
 SG_ MO_Abstellzeit : 32|8@1+ (8,0) [0|2024] "Unit_Minut"  Vector__XXX
 SG_ MO_Abstellzeit_Status : 40|2@1+ (1.0,0.0) [0.0|3] ""  Vector__XXX
 SG_ MO1_Freigabe_Verfallsinfo_WFS : 42|1@1+ (1.0,0.0) [0.0|1] ""  Vector__XXX
 SG_ MO_Hybrid_StartStopp_LED : 43|2@1+ (1.0,0.0) [0.0|3] ""  Vector__XXX
 SG_ MO_Fehler_Zylabsch : 45|2@1+ (1.0,0.0) [0.0|3] ""  Vector__XXX
 SG_ MO_Anzahl_Abgesch_Zyl : 47|3@1+ (1.0,0.0) [0.0|7] ""  Vector__XXX
 SG_ MO_Zylabsch_Texte : 50|2@1+ (1.0,0.0) [0.0|3] ""  Vector__XXX
 SG_ MO_Ethanol_BS_Texte : 52|3@1+ (1.0,0.0) [0.0|7] ""  Vector__XXX
 SG_ MO_Drehzahl_Warnung : 55|1@1+ (1.0,0.0) [0.0|1] ""  Vector__XXX
 SG_ MO_obere_Drehzahlgrenze : 56|8@1+ (50,0) [50|12750] "Unit_MinutInver"  Vector__XXX

BO_TX_BU_ 310 :Gateway,Gateway_PAG;
BO_TX_BU_ 29 :Gateway,Gateway_PAG;
BO_TX_BU_ 960 :Gateway,Gateway_PAG;
BO_TX_BU_ 2549088272 :Gateway,Gateway_PAG;
BO_TX_BU_ 779 :Gateway,Gateway_PAG;
BO_TX_BU_ 1719 :Gateway,Gateway_PAG;
BO_TX_BU_ 1720 :Gateway,Gateway_PAG;
BO_TX_BU_ 2549875047 :Gateway,Gateway_PAG;
BO_TX_BU_ 2527679653 :Gateway,Gateway_PAG;
BO_TX_BU_ 810 :Gateway,Gateway_PAG;
BO_TX_BU_ 159 :Gateway,Gateway_PAG;
BO_TX_BU_ 2331595840 :Gateway,Gateway_PAG;
BO_TX_BU_ 981 :Gateway,Gateway_PAG;
BO_TX_BU_ 1624 :Gateway,Gateway_PAG;
BO_TX_BU_ 134 :Gateway,Gateway_PAG;
BO_TX_BU_ 168 :Gateway,Gateway_PAG;
BO_TX_BU_ 958 :Gateway,Gateway_PAG;
BO_TX_BU_ 1648 :Gateway,Gateway_PAG;
CM_ BO_ 960 "MQB";
CM_ BO_ 779 "MQB";
CM_ BO_ 810 "MQB: 50ms (für CAN-SG), geändertes Charisma, Entfall KD-Fehler";
CM_ BO_ 159 "C7 und B8

Zykluszeit 10ms zyklisch";
CM_ BO_ 134 "ab MQB mit CRC in Byte 1";
CM_ BO_ 168 "Teil 2 neue Momentenschnittstelle MLB";
CM_ BO_ 1648 "Kombischnittstelle";

CM_ SG_ 2463978723 GNSS_DR_Nachrichtenpaket_ID2 "+1 für jedes neue Paket. Zyklische ID-Vergabe (Zähler). Zur Identifizierung zusammenhängender Nachrichten, die die Daten derselben GNSS-Ortung enthalten und somit zum selben Zyklus gehören. D.h. Daten in den Nachrichten wurden zur selben Zeit erzeugt. Der";
CM_ SG_ 2463978723 GNSS_DR_Ortung_2D_Geschw_u_Grund "Dead Reckoning Geschwindigkeit in m pro Sekunde";
CM_ SG_ 2463978723 GNSS_DR_Ortung_Ausrichtung "Dead Reckoning Ausrichtung (Kurswinkel) der GNSS-Messung";

CM_ SG_ 2463978724 GNSS_DR_Nachrichtenpaket_ID3 "+1 für jedes neue Paket. Zyklische ID-Vergabe (Zähler). Zur Identifizierung zusammenhängender Nachrichten, die die Daten derselben GNSS-Ortung enthalten und somit zum selben Zyklus gehören. D.h. Daten in den Nachrichten wurden zur selben Zeit erzeugt. Der";
CM_ SG_ 2463978724 GNSS_DR_Ortung_Guete_Ausrichtung "Dead Reckoning Gesamtgenauigkeit bezüglich der Ausrichtung (Kurswinkel)";
CM_ SG_ 2463978724 GNSS_DR_Ortung_Guete_Geschwindig "Dead Reckoning Gesamtgenauigkeit bezüglich Geschwindigkeit am Erdboden";
CM_ SG_ 2463978724 GNSS_DR_Ortung_Guete_horizontal "Dead Reckoning Gesamtgenauigkeit bezüglich der 2D-Position (horzontal)";
CM_ SG_ 2463978724 GNSS_DR_Ortung_Guete_vertikal "Dead Reckoning Gesamtgenauigkeit bezüglich der 1D-Position (vertikal)";

CM_ SG_ 2463978725 GNSS_DR_Nachrichtenpaket_ID4 "+1 für jedes neue Paket. Zyklische ID-Vergabe (Zähler). Zur Identifizierung zusammenhängender Nachrichten, die die Daten derselben GNSS-Ortung enthalten und somit zum selben Zyklus gehören. D.h. Daten in den Nachrichten wurden zur selben Zeit erzeugt. Der";
CM_ SG_ 2463978725 GNSS_DR_Odometer "Odometer (aus DR, mit kalibriertem Radumfang berechnet) wird  für den Datensammler benötigt. Wird im Datensammler in Millimeter eingesammelt.
Odometer mit Überlauf bei 1000m";
CM_ SG_ 2463978725 GNSS_DR_Ortung_Hoehe "Dead Reckoning Höhe über dem Meeresspiegel";
CM_ SG_ 2463978725 GNSS_DR_Ortung_Zeit_in_GPSWoche "Zeitstempel für die Dead Reckoning Jitter-Prüfung.";
CM_ SG_ 2463978725 GNSS_DR_Pitch "Pitch (Nickwickel des Fahrzeugs)
Pitch (aus DR, berechnet aus Beschleunigung und Odometer) wird für den Datensammler benötigt. Wird im Datensammler in Centi-Grad eingesammelt. (aktuelle Nutzung +-45Grad)";

CM_ SG_ 2463978726 GNSS_DR_Nachrichtenpaket_ID5 "+1 für jedes neue Paket. Zyklische ID-Vergabe (Zähler). Zur Identifizierung zusammenhängender Nachrichten, die die Daten derselben GNSS-Ortung enthalten und somit zum selben Zyklus gehören. D.h. Daten in den Nachrichten wurden zur selben Zeit erzeugt. Der";
CM_ SG_ 2463978726 GNSS_DR_UTC_Zeit "Dead Reckoning UTC-Zeit, Sekunden seit dem 01.01.1970 00:00";

CM_ SG_ 310 HAL_01_BZ "Botschaft asynchron geroutet. Zählerwert kann springen.";
CM_ SG_ 310 HAL_01_CRC "Für MLB:
'Berechnung siehe Lastenheft 'Kommunikationsabsicherung für FlexRay und CAN''

Ab MQB und MLBevo:
'Berechnung siehe Lastenheft 'End-to-End Kommunikationsabsicherung''

Endwerte siehe Begleitdokument 'S-PDU Kennungsfolgen'
";
CM_ SG_ 310 HAL_Charisma_FahrPr "MLBevo: Aktuelles Fahrprogramm des Charisma-Teilnehmers (siehe Systemlastenheft Drive Select)
MQB: Istwert der Kennlinie (siehe Systemlastenheft MQB FPA)";
CM_ SG_ 310 HAL_Charisma_Status "Rückmeldung an den Charisma-Master";
CM_ SG_ 310 HAL_EFP_FahrPr "Aktueller Ist-Zustand der HAL";
CM_ SG_ 310 HAL_Fahrerwunschwinkel_Soll "Zielwinkel (=Fahrerwunschwinkel) am Rad Hinterachslenkung in Grad";
CM_ SG_ 310 HAL_max_Gradient "maximaler Zustellgradient für die Stabilisierungsfunktion mit HAL durch ESP";
CM_ SG_ 310 HAL_QBit_Radwinkel "Wenn Bit gesetzt, dann entspreicht das Signal nicht mehr ASIL-D. (z.B. Ausfall der redundanten Sensorik)";
CM_ SG_ 310 HAL_Radwinkel "Zusätzlich durch die HAL gestellter Radwinkeloffset an der Hinterachse in Grad";
CM_ SG_ 310 HAL_Status "Status der Hinterachslenkung
0: normaler Betrieb 
1: HAL verriegelt (z.B. harter Fehler, nicht kalibriert)
2: Rücknahme der Leistung, Funktion eingeschränkt/Derating aktiv 
3: HAL deaktiviert";
CM_ SG_ 310 HAL_Status_2 "Zustand der Hinterachlenkung in der Smart application";
CM_ SG_ 310 HAL_VZ_Fahrerwunschwinkel_Soll "Soll-Lenkrichtung der HAL";
CM_ SG_ 310 HAL_VZ_Radwinkel "Lenkrichtung der HAL";
CM_ SG_ 310 HAL_Warnungen "Warnmeldungsanforderung von der Hinterachslenkung an das Kombiinstrumnent";
CM_ SG_ 310 HAL_Winkelbegrenzung "Signal liefert die Info über eine aktive Winkelbegrenzung in der HAL aufgrund Bauteilschutz";

CM_ SG_ 29 IMMO_Auth_Master_Slave07_Sig1 "Signal zur WFS Auth. vom Master ans cGW/OCU";

CM_ SG_ 28 IMMO_Auth_Slave07_Master_Sig1 "Authentifikationssignal  Slave 6 - Master, WFS5";

CM_ SG_ 960 BCM_Ausparken_Betrieb "Anforderung zur erneuten Lampenaufprüfung und Anzeige von Warnhinweisen nach einem pilotierten Ausparkvorgang (Trigger: fallende Flanke)";
CM_ SG_ 960 BCM_Remotestart_Betrieb "Zeigt den Status des RemoteStarts an, d.h. KL15_RSt ist aktiviert und der Motorlauf ist im RSt-Betrieb aktiv.";
CM_ SG_ 960 BCM_Remotestart_KL15_Anf "Zeigt den Status der Aktivierung der KL15_RST durch das BCM an.";
CM_ SG_ 960 BCM_Remotestart_MO_Start "Nachdem das BCM die Remotestart MSG Freigabe sicher erkannt hat, fordert das BCM wiederum über dieses Signal vom MSG einen Motorstart durchzuführen.";
CM_ SG_ 960 Klemmen_Status_01_BZ "4bit Botschaftszaehler; wird in jeder Sendebotschaft inkrementiert";
CM_ SG_ 960 Klemmen_Status_01_CRC "Für MLB:
'Berechnung siehe Lastenheft 'Kommunikationsabsicherung für FlexRay und CAN''

Ab MQB und MLBevo:
'Berechnung siehe Lastenheft 'End-to-End Kommunikationsabsicherung''

Endwerte siehe Begleitdokument 'S-PDU Kennungsfolgen'";
CM_ SG_ 960 KST_Fahrerhinweis_1 "Signalisierung Fahrerhinweis 1 der Klemmensteuerung an das Kombi";
CM_ SG_ 960 KST_Fahrerhinweis_2 "Signalisierung Fahrerhinweis 2 der Klemmensteuerung an das Kombi";
CM_ SG_ 960 KST_Fahrerhinweis_4 "Signalisierung Fahrerhinweis 4 der Klemmensteuerung an das Kombi";
CM_ SG_ 960 KST_Fahrerhinweis_5 "Anzeigesignal für RemoteStart";
CM_ SG_ 960 KST_Fahrerhinweis_6 "Signal aktiviert die Kombi-Anzeigeinstrumente (Drehzahl, Tankinhalt, Kühlmitteltemperatur) während aktiviertem RemoteStart-Betrieb";
CM_ SG_ 960 KST_Warn_P1_ZST_def "Kombi Prio Warnung Klemmensteuerung 
Zündschloß defekt, Service aufsuchen!";
CM_ SG_ 960 KST_Warn_P2_ZST_def "Kombi Prio Warnung Klemmensteuerung
Zündschloß defekt!
";
CM_ SG_ 960 RSt_Fahrerhinweise "Über das Signal fordert das BCM Fahrerhinweise im Kombi für die Funktion RemoteStart an.";
CM_ SG_ 960 ZAS_Kl_15 "Klemme 15: Zuendung (SW-Kl.15)
";
CM_ SG_ 960 ZAS_Kl_50_Startanforderung "Klemme 50: Startwunsch Fahrer
";
CM_ SG_ 960 ZAS_Kl_Infotainment "Separate Klemmeninformation für das Infotainment. Signal entspricht im wesentlichen einer Klemme S Information, kann aber über einen Vor - bzw. Nachlauf zu Klemme S verfügen. 
Ein konkreter Anwendungsfall für einen Nachlauf ist die Abschaltung der Klemme";
CM_ SG_ 960 ZAS_Kl_S "Klemme S: S-Kontakt (Schluessel steckt)
";
CM_ SG_ 960 ZAS_Kl_X "Klemme 75
";

CM_ SG_ 2549088272 Gateway_Abschaltstufe "Funktionseinschränkung aufgrund aktiver Abschaltstufe";
CM_ SG_ 2549088272 Gateway_KompSchutz "Funktionseinschränkung aufgrund Komponentenschutz aktiv";
CM_ SG_ 2549088272 Gateway_Matrix_Generation "Signal gibt an welche Matrix-Generation umgesetzt ist";
CM_ SG_ 2549088272 Gateway_Matrix_Version "Signal gibt an welche Matrix-Version des Baukasten umgesetzt ist.
z.B. V.08.xx, das Signal gibt den Wert für xx an";
CM_ SG_ 2549088272 Gateway_Nachlauftyp "Abgebildet wird die von der Hardware vorgegebene Möglichkeit, die Kommunikation nach Klemme 15 = AUS aufrecht zu erhalten. Es wird ein Init-Wert gesendet.";
CM_ SG_ 2549088272 Gateway_SNI "Das Signal beinhaltet den Source Node Identifier (Knotenadresse, die auch in der Abbildungsvorschrift zur CAN-ID für die NM-High Botschaft verwendet wird).";
CM_ SG_ 2549088272 Gateway_Transport_Mode "Funktionseinschränkung aufgrund aktivem Transport Mode und/oder Transport Schutz";
CM_ SG_ 2549088272 GW_KD_Fehler "Kundendienstfehlerbit Gateway zur Anzeige eines im Gateway abgelegten Fehlerspeichereintrages.";
CM_ SG_ 2549088272 NM_Gateway_Lokalaktiv "Zeigt an ob das SG nach Klemme15 AUS und nach entsprechender MAX Aktivzeit noch aktiv war.";
CM_ SG_ 2549088272 NM_Gateway_Subsystemaktiv "Zeigt an ob ein Subsystem des SGs nach Klemme15 AUS und nach entsprechender MAX Aktivzeit noch aktiv war";
CM_ SG_ 2549088272 NM_Gateway_Wakeup "enthält die Weckursache; stehen mehrere Weckursachen parallel an, dann muss der kleinste Wert übertragen werden";

CM_ SG_ 2549088265 KN_Sekundaer_09_BusKnockOut "Ausgabe des BusKnockout-Status in der Knotenbotschaft";
CM_ SG_ 2549088265 KN_Sekundaer_09_BusKnockOutTimer "Ausgabe des BusKnockOut-Timer in der Knotenbotschaft";
CM_ SG_ 2549088265 KN_Sekundaer_09_DiagPfad "Kennzeichnung der Diagnosefähigkeit des BusInterfaces eines Steuergerätes (Knoten)
Umfang LAH 80127

Bei Nutzung des Signal explizit pro angebundenem BusInterface zu setzen:

immer = 1 (nicht aktiv)";
CM_ SG_ 2549088265 KN_Sekundaer_09_ECUKnockOut "Ausgabe des ECUKnockout-Status in der Knotenbotschaft";
CM_ SG_ 2549088265 KN_Sekundaer_09_ECUKnockOutTimer "Ausgabe des ECUKnockOut-Timer in der Knotenbotschaft";
CM_ SG_ 2549088265 NM_Sekundaer_09_Lokalaktiv "Zeigt an ob das SG nach Klemme15 AUS und nach entsprechender MAX Aktivzeit noch aktiv war";
CM_ SG_ 2549088265 NM_Sekundaer_09_OTA_FC_Wakeup "enthält die Weckursache; stehen mehrere Weckursachen parallel an, dann muss der kleinste Wert übertragen werden";
CM_ SG_ 2549088265 NM_Sekundaer_09_Subsystemaktiv "Zeigt an ob ein Subsystem des SGs nach Klemme15 AUS und nach entsprechender MAX Aktivzeit noch aktiv war";
CM_ SG_ 2549088265 Sekundaer_09_Abschaltstufe "Funktionseinschränkung aufgrund aktiver Abschaltstufe";
CM_ SG_ 2549088265 Sekundaer_09_KD_Fehler "Status Kundendienst-Fehlerspeicher";
CM_ SG_ 2549088265 Sekundaer_09_KompSchutz "Funktionseinschränkung aufgrund Komponentenschutz aktiv";
CM_ SG_ 2549088265 Sekundaer_09_Nachlauftyp "Abgebildet wird die von der Hardware vorgegebene Möglichkeit, die Kommunikation nach Klemme 15 = AUS aufrecht zu erhalten. Es wird ein Init-Wert gesendet.
0 = Kommunikation nur bei KL15=EIN (kein Nachlauf, nicht weckfähig)
1 = Kommunikation nach KL15=AU";
CM_ SG_ 2549088265 Sekundaer_09_SNI "Das Signal beinhaltet den Source Node Identifier (Knotenadresse, die auch in der Abbildungsvorschrift zur CAN-ID für die NM-High Botschaft verwendet wird).";
CM_ SG_ 2549088265 Sekundaer_09_Transport_Mode "Funktionseinschränkung aufgrund aktivem Transport Mode und/oder Transport Schutz";

CM_ SG_ 2549088496 KN_Sekundaer_F0_BusKnockOut "Ausgabe des BusKnockout-Status in der Knotenbotschaft";
CM_ SG_ 2549088496 KN_Sekundaer_F0_BusKnockOutTimer "Ausgabe des BusKnockOut-Timer in der Knotenbotschaft";
CM_ SG_ 2549088496 KN_Sekundaer_F0_ECUKnockOut "Ausgabe des ECUKnockout-Status in der Knotenbotschaft";
CM_ SG_ 2549088496 KN_Sekundaer_F0_ECUKnockOutTimer "Ausgabe des ECUKnockOut-Timer in der Knotenbotschaft";
CM_ SG_ 2549088496 NM_Sekundaer_F0_Lokalaktiv "Zeigt an ob das SG nach Klemme15 AUS und nach entsprechender MAX Aktivzeit noch aktiv war";
CM_ SG_ 2549088496 NM_Sekundaer_F0_Wakeup "enthält die Weckursache; stehen mehrere Weckursachen parallel an, dann muss der kleinste Wert übertragen werden";
CM_ SG_ 2549088496 Sekundaer_F0_Abschaltstufe "Funktionseinschränkung aufgrund aktiver Abschaltstufe";
CM_ SG_ 2549088496 Sekundaer_F0_KD_Fehler "Status Kundendienst-Fehlerspeicher";
CM_ SG_ 2549088496 Sekundaer_F0_KompSchutz "Funktionseinschränkung aufgrund Komponentenschutz aktiv";
CM_ SG_ 2549088496 Sekundaer_F0_Nachlauftyp "Abgebildet wird die von der Hardware vorgegebene Möglichkeit, die Kommunikation nach Klemme 15 = AUS aufrecht zu erhalten. Es wird ein Init-Wert gesendet.
0 = Kommunikation nur bei KL15=EIN (kein Nachlauf, nicht weckfähig)
1 = Kommunikation nach KL15=AU";
CM_ SG_ 2549088496 Sekundaer_F0_SNI "Das Signal beinhaltet den Source Node Identifier (Knotenadresse, die auch in der Abbildungsvorschrift zur CAN-ID für die NM-High Botschaft verwendet wird).";
CM_ SG_ 2549088496 Sekundaer_F0_Transport_Mode "Funktionseinschränkung aufgrund aktivem Transport Mode und/oder Transport Schutz";

CM_ SG_ 779 KBI_ABS_Lampe "ABS-Sicherheits-Lampe wurde eingeschaltet.";
CM_ SG_ 779 KBI_Airbag_Lampe "Airbag Sicherheits-Lampe wurde eingeschaltet ";
CM_ SG_ 779 KBI_angez_Geschw "Im Tacho angezeigte Geschwindigkeit inklusive der Voreilung

";
CM_ SG_ 779 KBI_Anzeigefehler_NV "Über dieses Signal teilt das Kombiinstrument dem Nightvision-Steuergerät mit, dass ein Fehler vom Kombiinstrument diagnostiziert wurde, der zur Abschaltung der Nightvision-Funktion führen muss.";
CM_ SG_ 779 KBI_Anzeigefehler_SWA "Signal bezieht sich nur auf die SWA-Lampe, Vorhalt für Kombis mit SWA-Lampe. ";
CM_ SG_ 779 KBI_Anzeigestatus_ACC "Status der ACC-Anzeige im nicht permanenten Displaybereich";
CM_ SG_ 779 KBI_Anzeigestatus_GRA "Anzeigestatus der GRA High Wunschgeschwindigkeitsanzeige im Kombiinstrument.
Bei VW bedeutet 'nicht vorhanden' GRA-low fähig (LED immer verbaut).
0 = nicht vorhanden
1 = Wunschgeschwindigkeits-Anzeigemöglichkeit vorhanden
2 = reserviert
3 = Fehler (B";
CM_ SG_ 779 KBI_Anzeigestatus_LIM "Anzeigestatus der Speedlimiter Wunschgeschwindigkeitsanzeige im Kombiinstrument (permanenter Anzeigebereich)
0 = nicht vorhanden
1 = Wunschgeschwindigkeits-Anzeigemöglichkeit vorhanden
2 = reserviert
3 = Fehler (Botschaftsüberwachung, Timeout, Akustik";
CM_ SG_ 779 KBI_ARA_in_Anzeige "Anzeige von ARA im Kombi aktiv";
CM_ SG_ 779 KBI_Bestaetigung_ESP_Off "ESP Off Bestätigung vom Kombi ans ESC";
CM_ SG_ 779 KBI_BKL_Lampe "Sicherheits-Lampe Bremskontrolle wurde eingeschaltet;
";
CM_ SG_ 779 KBI_Einheit_Tacho "Information, ob es sich um Meilen- oder Kmh-Kombi handelt, Einheit des Tachos entspricht dem Zifferblatt, Grösse ist nicht veränderlich";
CM_ SG_ 779 KBI_ESP_Lampe "ESP-Sicherheits-Lampe wurde eingeschaltet ";
CM_ SG_ 779 KBI_Fehler_Anzeige_ACC "Rückmeldung an ACC, dass mindestens eine der ACC-relevanten Anzeigen -rote Fahrerübernahme, Mitteldisplay, Gong - fehlerhaft sind.";
CM_ SG_ 779 KBI_GRA_Hauptschalter "Hauptschalter der Fahrerassistenzsysteme basierend auf dem FAS-Menu im Kombi.";
CM_ SG_ 779 KBI_Handbremse "Handbremsen-Information vom Kombi.
Das Signal bezieht sich ausschließlich auf den Zustand der konventionellen Handbremse.";
CM_ SG_ 779 KBI_im_Stellgliedtest "Kombi im Stellgliedtest, Signal muss eingelesen werden, um Fehlfunktion aufgrund der Bewegung der Stellglieder (Drehzahlmesser, Tacho) des Kombis zu verhindern";
CM_ SG_ 779 KBI_Konsistenz_ACC "Rückmeldung an ACC, dass die Botschaften zur Ansteuerung von Anzeigen nicht bzw. nicht konsistent empfangen wurden (Timeout-, BZ-, CHK- und DLC-Fehler)                                                                                                        ";
CM_ SG_ 779 KBI_Lenkung_Lampe "Sicherheits-Lampe der Lenkung (Lenkhilfe EPS, Audi-Dynamic-Steering ...) wurde eingeschaltet.

0x0 = Lenkungs-Lampe aus
0x1 = Lenkungs-Lampe ein";
CM_ SG_ 779 KBI_MFA_v_Einheit_01 "Einheit der Geschwindigkeit, die vom Fahrer im Car-Menü gewählt wurde. Veränderliche Grösse, im Gegensatz zur Einheit des Tachokranzes.";
CM_ SG_ 779 KBI_NV_in_Anzeige "Das Bit gibt dem NV die Information, ob NV-Bild im Kombi in der Anzeige ist. (Information ist notwendig um Kontrasverstellungen nur dann zuzulassen, wenn der Fahrer das Feedback über das  Kombidisplay bekommt.)";
CM_ SG_ 779 KBI_PLA_in_Anzeige "Das Signal wird als aktive Rückmeldung genutzt, ob die Info des PLA im Kombi angezeigt wird. Wenn nach Anforderung des Displays das Signal zweimal auf 0 ist, wird der Parkvorgang abgebrochen.
Ein Kombi, dass PLA Anzeige nicht unterstützt, schickt dauerha";
CM_ SG_ 779 KBI_SILA_gueltig "Rückmeldeinformation (Bit 1-6) ist gültig";
CM_ SG_ 779 KBI_Systemstatus "Signalisiert erkannte FuSi-relevante Fehler im Kombi
(keinen Ausfall der Akustik oder des Displays)";
CM_ SG_ 779 KBI_Tankwarnung "Fahrer wird gewarnt, dass er den Reservebereich erreicht hat. Fzg.spezifische Warnschwelle";
CM_ SG_ 779 KBI_Tankwarnung_ungueltig "Validiert den Inhalt des Signales KBI_Tankwarnung";
CM_ SG_ 779 KBI_Taster_Fahrwerk "Betätigung Taster 'Fahrwerk' im Kombi";
CM_ SG_ 779 KBI_Taster_Lift "Betätigung Taster 'Lift' im Kombi J1 zur Verarbeitung im Porsche EFP Steuergerät";
CM_ SG_ 779 KBI_V_Digital "Ausgabe der im Kombi angezeigten digitalen Geschwindigkeit.

Einheit ist im KBI_MFA_v_Einheit_01 definiert";
CM_ SG_ 779 KBI_Vorglueh_System_Lampe "Rückmeldung der Vorglühlampe bzw. Motor Systemlampe (MO_Systemlampe) an den Motor (bei Diesel und Otto!). Hardwaremässig gleiche LED im Kombi (EPC- oder Glühwendel), Unterscheidung nur über Ziffernblatt.";
CM_ SG_ 779 Kombi_01_BZ "Botschaft asynchron geroutet. Zählerwert kann springen.";

CM_ SG_ 1719 KBI_aktive_Laengsfunktion "Auswahl, der vom Fahrer gewünschten Laengsregelfunktion";
CM_ SG_ 1719 KBI_FoD_PopUP_Quittiert "Angezeigte FoD-Warnung im Kombi wurde vom Fahrer quittiert; 
Signal wird für die Dauer von 2 Sekunden gesendet";
CM_ SG_ 1719 KBI_FStatus_Tank "Signal wird gesetzt:

a) Während der Fehlerentprellzeit (20 s Entprellung)

b) Bei erkanntem Fehler wird der Tankinhalt während der laufenden KL15-Phase über den 
    Verbrauch zurückgerechnet. In dieser Zeit ist das Bit ebenfalls gesetzt. Nach einem";
CM_ SG_ 1719 KBI_GRA_im_ACC "Gibt den vom Fahrer ausgewählten Modus (ACC oder GRA_im_ACC) an.";
CM_ SG_ 1719 KBI_Inhalt_Tank "Restmenge 2 bzw. 2,5l nicht auflösbar

";
CM_ SG_ 1719 KBI_Kilometerstand "Fehler wird ausgegeben, falls Kilometerstand nicht restaurierbar
";
CM_ SG_ 1719 KBI_LVDS_Lock "Dient zur Synchronisation der Anzeige zwischen Kombi und ZR";
CM_ SG_ 1719 KBI_Oelwechsel_durchgefuehrt "Nach einen Ölwechsel (Service) ist die Ethanol Warmfahrwarnung zu unterdrücken.";
CM_ SG_ 1719 KBI_QBit_Aussen_Temp_gef "0x0 = gültiger Wert
0x1 = Ersatz-, Init- oder Fehlerwert";
CM_ SG_ 1719 KBI_RDK_Kalibrier_Anf "Bei gesetztem Bit soll die RDK die aktuellen Istdrücke zu Solldrücken übernehmen (nur bei Nichtverbau einer Headunit erforderlich).";
CM_ SG_ 1719 KBI_Reserve_Warnung_Sek "Signalisiert die Reservewarnung für die Energiespeicher CNG, LPG, HV-Batterie.
Fahrer wird gewarnt, dass er den Reservebereich erreicht hat. Fzg.spezifische Warnschwelle.";
CM_ SG_ 1719 KBI_Standzeit_02 "Zähler welcher die Standzeit des Motors wiedergibt.
Das Signal beschreibt den Anteil der Motor-Standzeit zwischen Zündung aus und nächstem Motorstart.";
CM_ SG_ 1719 KBI_TA_gewaehlt_Fahrer "Rueckmeldung, dass der TA vom Fahrer gewaehlt wurde";

CM_ SG_ 1720 KBI_BCmE_aktiv "Anzeige BCmE aktiv (BCmE-Screen oder Einsparhinweis in der Anzeige)";
CM_ SG_ 1720 KBI_GAP_Warn_Zeit_abgelaufen "Die Zeit, z.B. 1460 Tage, bis zur finalen Warnstufe der Gasanlagenprüfung wurde berechnet. Berechnung erfolgt auf Basis der aktuellen Uhrzeit mit einem Tageszähler. Keine Berechnung des Zählers bei Kl.30 AUS.";
CM_ SG_ 1720 KBI_Max_Tankinhalt "Mitteilung des maximalen Tankinhalts an das Reichweitenmodul";
CM_ SG_ 1720 KBI_Nachtanken_erkannt "Statusinformation Nachtankmodus";
CM_ SG_ 1720 KBI_Quittierung_cAQP "Quittierungsbestätigung vom Fahrer für Funktion cAQP";
CM_ SG_ 1720 KBI_Quittierung_Naesse "Quittierungsbestätigung vom Fahrer";
CM_ SG_ 1720 KBI_Reifenumfang "Mittlerer Radumfang aus der K-Zahl gerechnet in Millimeter.  Byte 2 Bit 5,4 reserviert, Byte 2 Bit 3..0 und Byte 1 Bit 7..0; Wertebereich 0..4096 mm
";
CM_ SG_ 1720 KBI_Reifenumfang_Sekundaer "Fahrzeuge mit unterschiedlichen Reifenumfängen Vorderachse / Hinterachse:

Primärachse: KBI_Reifenumfang
Sekundärachse: KBI_Reifenumfang_Sekundaer
";
CM_ SG_ 1720 KBI_Sparhinweis_quittiert "angezeigter Sparhinweis ist quittiert. Signal wird nach zwei Sendebotschaften wieder auf '0' gesetzt.";
CM_ SG_ 1720 KBI_Tankfuellstand_Prozent "Tankfüllstand in %";
CM_ SG_ 1720 KBI_Tankinhalt_hochaufl "angezeigter Tankinhalt hochauflösend zur Restreichweitenberechnung";
CM_ SG_ 1720 KBI_Variante "Zeigt an ob es sich um ein konventionelles Zeiger-Kombiinstrument handelt oder um eine Volldisplay-Kombiinstrument";
CM_ SG_ 1720 KBI_Variante_USA "In diesem Signal wird die HW-Variante des Kombis ausgegeben, ACC plausibilisiert auf dieses Signal hin seine US-Codierung";

CM_ SG_ 2549875047 KS_eCall_Req_Data "ISO-TP Datenkanal - FID2NA
Request Funktion 0x01 Komponentenschutz an Knoten 0x67";

CM_ SG_ 2550006119 KS_eCall_Resp_Data "ISO-TP Datenkanal - FID2NA
Response Knoten 0x67 an Funktion 0x01 Komponentenschutz";

CM_ SG_ 2549875078 KS_OTA_FC_Req_Data "ISO-TP Datenkanal -
Request Funktion  Komponentenschutz an Knoten 0x86";

CM_ SG_ 2550006150 KS_OTA_FC_Resp_Data "ISO-TP Datenkanal 
Response Knoten 0x86 an Funktion 0x01 Komponentenschutz";

CM_ SG_ 2527679653 MXB_LAPP_Freigabe "Freigabe des Advertising durch die DDA";
CM_ SG_ 2527679653 MXB_LAPP_Status_FL "Gibt den Aktivierungsstatus des Fernlichts (FL) durch die Licht-App an.";
CM_ SG_ 2527679653 MXB_LAPP_Statuscode "Gibt den Bereitschaftsstatus der Licht-App an.

Der Wert des Signals ergibt sich aus den Stati der fahrzeugspezifischen Vorbedingungen und dient der Licht-App als Grundlage für Anweisungen an den Kunden.";
CM_ SG_ 2527679653 MXB_LAPP_ZR_Sondermodus_Anf "Anforderung des ZR Sondermodus (BT-Abschaltung)";

CM_ SG_ 810 EPS_01_BZ "Botschaft asynchron geroutet. Zählerwert kann springen.";
CM_ SG_ 810 EPS_01_CRC "Für MLB:
'Berechnung siehe Lastenheft 'Kommunikationsabsicherung für FlexRay und CAN''

Ab MQB und MLBevo:
'Berechnung siehe Lastenheft 'End-to-End Kommunikationsabsicherung''

Endwerte siehe Begleitdokument 'S-PDU Kennungsfolgen'
";
CM_ SG_ 810 EPS_Anf_KL "Nach Überschreiten einer oberen Grenztemperatur innerhalb des Steuergerätes der Lenkhilfe fordert die EPS die Zuschaltung einer externen Kühlung durch den Kühlerlüfter an.
Es besteht kein technischer Zusammenhang mit einer Batterie_ab - Erkennung in der ";
CM_ SG_ 810 EPS_ARA_Status "Anforderung vom Anhängerrangierassistent. 
16 Statuswerte";
CM_ SG_ 810 EPS_Charisma_FahrPr "MLBevo: Aktuelles Fahrprogramm des Charisma-Teilnehmers (siehe Systemlastenheft Drive Select)
MQB: Istwert der Kennlinie (siehe Systemlastenheft MQB FPA)";
CM_ SG_ 810 EPS_Charisma_Status "Rückmeldung an den Charisma-Master

Wert 0x3 ist nur für Fahrzeuge ab MQB relevant";
CM_ SG_ 810 EPS_Endanschlag "Die EPS muss applikativ ein Lenkhubmapping umsetzen. Das Lenkhubmapping muss für jeden NR-Reglerstatus den Defaultendanschlag oder die Lenkhubaufweitung zuordnen.";
CM_ SG_ 810 EPS_Fehlerlampe "Steuert direkt die Fehlerlampe Lenkhilfe (gelb); kein Aufprüfen bei Neustart, keine Rückleseinformation in Kombi-Botschaft (nur für VW526 Hybrid)";
CM_ SG_ 810 EPS_Lenkerposition "Position des Lenkers im Fahrzeug";
CM_ SG_ 810 EPS_PLA_Status "Zustand der Statusmaschine der EPS für die korrespondierenden Statusmaschine im PLA.";
CM_ SG_ 810 EPS_PWR_Abbruch "Dieses Signal gibt das Abbruchkriterium für PLA und ARA an.";
CM_ SG_ 810 EPS_PWR_Fehler "Gibt den Fehler aus wenn eine Lenkwinkelanforderung nicht ausgeführt werden konnte.";
CM_ SG_ 810 EPS_SpannungsAnf "Forderung des EPS-SG's zur Spannungsanhebung.";
CM_ SG_ 810 EPS_Warnungen "Diese Bits werden verwendet, um im Kombi Texte, Lampen oder Bilder für die Lenkhilfe darzustellen
Audi MLB/RSe:
Text_1: Lenkung defekt (Prio 1)
Text_2: Lenkung Systemstörung (Prio 2)
VW526:
Text_1 (ID_TXT_1026.1): Ausfall Lenkunterstützung
Text_2 (I";

CM_ SG_ 159 EPS_03_BZ "Botschaft asynchron geroutet. Zählerwert kann springen.";
CM_ SG_ 159 EPS_03_CRC "Für MLB:
'Berechnung siehe Lastenheft 'Kommunikationsabsicherung für FlexRay und CAN''

Ab MQB und MLBevo:
'Berechnung siehe Lastenheft 'End-to-End Kommunikationsabsicherung''

Endwerte siehe Begleitdokument 'S-PDU Kennungsfolgen'";
CM_ SG_ 159 EPS_Berechneter_LW "Berechneter Lenkradwinkel (BLW)
MLB: Ausgabe des berechneten Lenkwinkels mit Geradeauslaufkorrektur aus der Position des Lenkmotors (Absolutwert)
MQB: Ausgabe des berechneten Lenkwinkels aus der Position des Lenkmotors (Absolutwert) und ggf. unter Berüc";
CM_ SG_ 159 EPS_BLW_QBit "beschreibt die Qualität/Vertrauenswürdigkeit des berechneten LW";
CM_ SG_ 159 EPS_DSR_Status_02 "0 DSR deaktiviert;
1 DSR Anforderung nicht ausführbar (ESP Fehlerstatus);
2 Kommunikation zum ESP-SG gestört;
3 EPS bzgl. DSR funktionsbereit;
4 DSR Anforderung abgewiesen;
5 externer Momenteneingriff aktiv;
6 externer Lenkwinkeleingriff aktiv;
7 e";
CM_ SG_ 159 EPS_HCA_Status_02 "beschreibt den Status der HCA-Funktion im EPS-Steuergerät.

Bedeutung der Status-Indices:
0: HCA in der EPS deaktiviert;
1: HCA Anforderung nicht ausführbar (HCA Fehlerstatus, Initialisierung, Ausschaltphase);
2: Kommunikation zum HCA-SG gestört;
3:";
CM_ SG_ 159 EPS_Lenkmoment "Gibt das durch den Momentensensor detektiertes Lenkhandmoment (Absolutmoment) aus

Wertebereich von 0x321 - 0x3FD reserviert (z.Zt. nicht bedient)";
CM_ SG_ 159 EPS_Lenkungstyp "Signal beschreibt den eingebauten Lenkungstyp. Enthält z. B. implizit auch die Information, welche Ritzelübersetzung verbaut ist. Wichtig für die Regelsysteme HCA und DSR.
Im MQB gilt das 'EPS LH CAN-Schnittstelle'.";
CM_ SG_ 159 EPS_VZ_BLW "Vorzeichen Berechneter Lenkwinkel

(für EPS_Berechneter_LW)";
CM_ SG_ 159 EPS_VZ_Lenkmoment "Vorzeichen Lenkhandmoment";

CM_ SG_ 2331595840 LHW_eventABSactivated "Vehicle Event Flag ABS activiated";
CM_ SG_ 2331595840 LHW_eventAirBagDeployment "Local Hazard Warning Event Flag AirBagDeployment";
CM_ SG_ 2331595840 LHW_eventDisabledVehicle "Local Hazard Warning Event Flag DisabledVehicle";
CM_ SG_ 2331595840 LHW_eventFlatTire "Local Hazard Warning Event Flag FlatTire";
CM_ SG_ 2331595840 LHW_eventHardBraking "Local Hazard Warning Event Flag Hard Braking";
CM_ SG_ 2331595840 LHW_eventHazardLights "Local Hazard Warning Event Flag Hazard Lights";
CM_ SG_ 2331595840 LHW_eventStabilityControlActive "Local Hazard Warning Event Flag Stability Control activated";
CM_ SG_ 2331595840 LHW_eventTractionControlLoss "Local Hazard Warning Event Flag Traction Control Loss";

CM_ SG_ 981 BCM1_Abblendlicht_Anf "Anforderung Abblendlicht
";
CM_ SG_ 981 BCM1_Adaptive_Lichtvert_Anf "Funktion 'Adaptive Lichtverteilung' im AFS-SG  Ein- und Ausschalten";
CM_ SG_ 981 BCM1_Allwetterlicht_Anf "Anforderung eines Allwetterlichts (über AFS-SG realisiert): Licht für schlechte Sichtverhältnisse";
CM_ SG_ 981 BCM1_Animationssperrung "Sperrung der Scheinwerfer- und Heckleuchten-Animationen. Grund für Sperrung sind allgemeine Rahmenbedingungen, wie beispielseweise eine LDS-Stellung ungleich 'Auto'";
CM_ SG_ 981 BCM1_Autobahnlicht_Anf "Anforderung Autobahnlicht
";
CM_ SG_ 981 BCM1_CH_aktiv "Coming Home (zusätzlich zum Signal 'BCM1_CH_LH_aktiv' in der Botschaft BCM1_01)";
CM_ SG_ 981 BCM1_CH_LH_aktiv "Status Comming / Leaving Home
";
CM_ SG_ 981 BCM1_Fernlicht_Anf "Anforderung Fernlicht
";
CM_ SG_ 981 BCM1_FOD_Sperrung_Animationen_HL "Sperrung Heckleuchten-Animationen durch FoD.";
CM_ SG_ 981 BCM1_FoD_Sperrung_WiBli "Sperrung Wischeffekt des dynamischen Blinkers (Front & Heck) durch FoD";
CM_ SG_ 981 BCM1_Gleitende_Leuchtw_Anf "Funktion 'Gleitende Leuchtweite' im AFS-SG  freischalten";
CM_ SG_ 981 BCM1_GLW_Fernlicht_Anf "Harte Fernlichtanforderung von BCM1 an die Funktion 'gleitende Leuchtweite' im AFS-SG";
CM_ SG_ 981 BCM1_Kurvenlicht_links_Anf "Ansteuerung linkes Kurvenlicht/Abbiegelicht duch BCM1";
CM_ SG_ 981 BCM1_Kurvenlicht_rechts_Anf "Ansteuerung rechtes Kurvenlicht/Abbiegelicht duch BCM1";
CM_ SG_ 981 BCM1_LH_aktiv "Leaving Home (zusätzlich zum Signal 'BCM1_CH_LH_aktiv' in der Botschaft BCM1_01)";
CM_ SG_ 981 BCM1_Nebellicht_Anf "Anforderung Nebellicht
";
CM_ SG_ 981 BCM1_Nebelschluss_Ahg_Anf "Anforderung: Nebelschlusslicht Anhänger (Sollzustand)
";
CM_ SG_ 981 BCM1_Nebelschluss_Fzg_Anf "Anforderung: Nebelschlusslicht Fahrzeug (Sollzustand)";
CM_ SG_ 981 BCM1_Parklicht_li_Anf "Anforderung: Parklicht links (Sollzustand)
";
CM_ SG_ 981 BCM1_Parklicht_re_Anf "Anforderung: Parklicht rechts (Sollzustand)
";
CM_ SG_ 981 BCM1_Regenlicht_Anf "Anforderung: Regenlicht (Sollzustand)
";
CM_ SG_ 981 BCM1_Schlusslicht_Anf "Anforderung: Schlusslicht Fahrzeug (Sollzustand)
";
CM_ SG_ 981 BCM1_Schlusslicht_Signatur "Anforderung der Umschaltung der Schlusslicht-Signatur";
CM_ SG_ 981 BCM1_Signaturlicht_Anf "Signal zur Anforderung des Signaturlichts";
CM_ SG_ 981 BCM1_Standlicht_Anf "Anforderung: Schlusslicht (Sollzustand)";
CM_ SG_ 981 BCM1_Tagfahrlicht_Anf "Anforderung: Tagfahrlicht (Sollzustand)";
CM_ SG_ 981 BCM1_Touristen_Licht_Anf "Anforderung: Touristenlicht (Sollzustand)";
CM_ SG_ 981 BCM1_Umfeldleuchten_Anf "Anforderung für Umfeldleuchten";
CM_ SG_ 981 BCM_Rueckfahrlicht_Anf "Anforderung Rückfahrlicht (Sollzustand). 
Das Signal wird entprellt (typisch 400ms) und bei KL15EIN gesendet. Das Signal ist unabhängig von der Position des Heckdeckels (kein Überhitzungsschutz).";
CM_ SG_ 981 Licht_Anf_01_BZ "4bit Botschaftszaehler, wird mit jeder Sendebotschaft inkrementiert";
CM_ SG_ 981 Licht_Anf_01_CRC "Für MLB:
'Berechnung siehe Lastenheft 'Kommunikationsabsicherung für FlexRay und CAN''

Ab MQB und MLBevo:
'Berechnung siehe Lastenheft 'End-to-End Kommunikationsabsicherung''

Endwerte siehe Begleitdokument 'S-PDU Kennungsfolgen'";

CM_ SG_ 1624 BCM1_Licht_Dunkelheit_aktiv "Licht aktiv aufgrund von Dunkelheit (nicht bei Autobahn-, Tagfahr- oder Regenlicht)";
CM_ SG_ 1624 BCM1_Linksverkehr "Information über Aufbauzustand des Fzg:
0 = Scheinwerfer für Rechtsverkehr
1 = Scheinwerfer für Linksverkehr";
CM_ SG_ 1624 Licht_Vorne_01_CRC "Für MLB:
'Berechnung siehe Lastenheft 'Kommunikationsabsicherung für FlexRay und CAN''

Ab MQB und MLBevo:
'Berechnung siehe Lastenheft 'End-to-End Kommunikationsabsicherung''

Endwerte siehe Begleitdokument 'S-PDU Kennungsfolgen'";
CM_ SG_ 1624 LV_Abbiegelicht_li_def "Fehlerstatus Abbiegelicht vorne links
";
CM_ SG_ 1624 LV_Abbiegelicht_re_def "Fehlerstatus Abbiegelicht vorne rechts
";
CM_ SG_ 1624 LV_Abblend_Fernlicht_li_def "Fehlerstatus Abblendlicht und Fernlicht links ";
CM_ SG_ 1624 LV_Abblend_Fernlicht_re_def "Fehlerstatus Abblendlicht und Fernlicht rechts";
CM_ SG_ 1624 LV_Abblendlicht_Anzeige "Abblendlicht aktiv";
CM_ SG_ 1624 LV_Abblendlicht_li_def "Fehlerstatus Abblendlicht vorne links 
";
CM_ SG_ 1624 LV_Abblendlicht_re_def "Fehlerstatus Abblendlicht vorne rechts
";
CM_ SG_ 1624 LV_Abblendlicht_TFL_li_def "Fehlerstatus Abblendlicht und Tagfahrlicht links
";
CM_ SG_ 1624 LV_Abblendlicht_TFL_re_def "Fehlerstatus Abblendlicht und Tagfahrlicht rechts ";
CM_ SG_ 1624 LV_AFL_aktiv_Anzeige "Anzeige AFL-Funktion";
CM_ SG_ 1624 LV_AFL_defekt "Fehlerstatus AFL
";
CM_ SG_ 1624 LV_Aussenlicht_def "Aussenlicht kann nicht mehr korrekt angesteuert werden (EEPROM Codierung kann nicht mehr ausgelesen werden)
";
CM_ SG_ 1624 LV_Blinker_li_def "Fehlerstatus Blinker vorne links
";
CM_ SG_ 1624 LV_Blinker_re_def "Fehlerstatus Blinker vorne rechts
";
CM_ SG_ 1624 LV_Blinker_VL_aktiv "Blinker vorne links
";
CM_ SG_ 1624 LV_Blinker_VR_aktiv "Blinker vorne links
";
CM_ SG_ 1624 LV_Blk_li_Seite_def "Fehlerstatus Seitenblinker links
";
CM_ SG_ 1624 LV_Blk_re_Seite_def "Fehlerstatus Blinker Seite rechts
";
CM_ SG_ 1624 LV_Fernlicht_Anzeige "Fernlicht_aktiv";
CM_ SG_ 1624 LV_Fernlicht_li_def "Fehlerstatus Fernlicht vorne links
";
CM_ SG_ 1624 LV_Fernlicht_re_def "Fehlerstatus Fernlicht vorne rechts
";
CM_ SG_ 1624 LV_FLA_aktiv_Anzeige "Ansteuerung FLA-Lampe im Kombi (BCM1 Bedienmaster)";
CM_ SG_ 1624 LV_FLA_defekt "Fehlerstatus FLA (Anzeige des entsprechenden Fehlertext im Kombi)";
CM_ SG_ 1624 LV_FLA_Sensor_blockiert "Status FLA-Sensor (Anzeige des entsprechenden Fehlertext im Kombi)";
CM_ SG_ 1624 LV_LED_Scheinwerfer_li_def "Fehlerstatus LED-Scheinwerfer links
";
CM_ SG_ 1624 LV_LED_Scheinwerfer_re_def "Fehlerstatus LED-Scheinwerfer rechts";
CM_ SG_ 1624 LV_MXB_Status_Anzeige "Aktueller Status des Fernlichts / MxB zur Signalisierung im Kombi.";
CM_ SG_ 1624 LV_Nebellicht_Anzeige "Nebellicht_aktiv
";
CM_ SG_ 1624 LV_Nebellicht_li_def "Fehlerstatus Nebelscheinwerfer vorne links
";
CM_ SG_ 1624 LV_Nebellicht_re_def "Fehlerstatus Nebelscheinwerfer vorne rechts
";
CM_ SG_ 1624 LV_Nebellicht_TFL_li_def "Fehlerstatus Nebellicht und Tagfahrlicht links ";
CM_ SG_ 1624 LV_Nebellicht_TFL_re_def "Fehlerstatus Nebellicht und Tagfahrlicht rechts";
CM_ SG_ 1624 LV_Nebelschlusslicht_Anzeige "Nebelschlusslicht_aktiv
";
CM_ SG_ 1624 LV_Standlicht_Anzeige "Anzeige Standlicht
";
CM_ SG_ 1624 LV_Standlicht_li_def "Fehlerstatus Standlicht vorne links
";
CM_ SG_ 1624 LV_Standlicht_re_def "Fehlerstatus Standlicht vorne rechts
";
CM_ SG_ 1624 LV_Standlicht_TFL_li_def "Fehlerstatus Standlicht und Tagfahrlicht links ";
CM_ SG_ 1624 LV_Standlicht_TFL_re_def "Fehlerstatus Standlicht und Tagfahrlicht rechts ";
CM_ SG_ 1624 LV_Tagfahrlicht_Anzeige "Anzeige Tagfahrlicht
";
CM_ SG_ 1624 LV_Tagfahrlicht_li_def "Fehlerstatus Tagfahrlicht links
";
CM_ SG_ 1624 LV_Tagfahrlicht_re_def "Fehlerstatus Tagfahrlicht rechts";

CM_ SG_ 134 LWI_01_CRC "Für MLB:
'Berechnung siehe Lastenheft 'Kommunikationsabsicherung für FlexRay und CAN''

Ab MQB und MLBevo:
'Berechnung siehe Lastenheft 'End-to-End Kommunikationsabsicherung'

Endwerte siehe Begleitdokument 'S-PDU Kennungsfolgen'";
CM_ SG_ 134 LWI_Lenkradw_Geschw "Wertebereich = +/- 2500 Grad/s
Auflösung = 5 Grad/s

Hinweis: Zusätzlich gestellte Winkel bei Dynamiklenkung beachten !";
CM_ SG_ 134 LWI_Lenkradwinkel "Wertebereich = +/- 800 Grad
Auflösung = 0,1 Grad
ACHTUNG: spezifizierte Interne Auflösung des Sensors beträgt aber nur Schrittweite 0,5 Grad!

Hinweis:
MLB: Zusätzlich gestellte Winkel bei Dynamiklenkung beachten !
MQB: Nicht konstante Lenkübersetzu";
CM_ SG_ 134 LWI_MFL_Abschaltung "Signal zur Anforderung der MFL Abschaltung bei Erkennung einer dynamischen Lenkbewegung.";
CM_ SG_ 134 LWI_QBit_Lenkradwinkel "Das QBit wird auch bei nicht abgeglichenem Lenkradwinkelsensor gesetzt";
CM_ SG_ 134 LWI_QBit_Sub_Daten "Es gilt die Signalspezifikation laut LAH";
CM_ SG_ 134 LWI_Sub_Daten "Verschlüsseltes Datenpaket vom Sub-Rechner des LWS, Verwendung nur durch SCU und ESP_ADS
Verwendung gemäß 'Sicherheitsanforderungen an Empfängersteuergeräte'

Im MLB gilt die Signalspezifikation: LAH 8K0953B
Im MLBevo gilt die Signalspezifikation LAH.";
CM_ SG_ 134 LWI_VZ_Lenkradw_Geschw "Vorzeichen Lenkradwinkelgeschwindigkeit gemäss DIN70000; 
Nullstellung = +0";
CM_ SG_ 134 LWI_VZ_Lenkradwinkel "Vorzeichen Lenkradwinkel gemäss DIN70000; 
Nullstellung = +0";

CM_ SG_ 168 MO_Drehzahl_01 "Im Fehlerfall wird die Motordrehzahl über die Nockenwellendrehzahl als Ersatzgrösse ausgegeben

Bei Parallelhybrid: Getriebeeingangsdrehzahl (=E-Maschinen Drehzahl)

Hinweis: 
Ehemaliger Fehlerwert 0xFFFF wird senderseitig nicht unterstützt. 
Diesen";
CM_ SG_ 168 MO_Mom_Begr_dyn "Einheitenloser Wert! Faktor in MO_Faktor_Momente (CAN V6.x) bzw. MO_Faktor_Momente_02 (CAN V7.x/V8.x) in Motor_Code_01 beachten!

Bei aktueller Drehzahl kurzfristig (ca. 100..200 ms) max. mögliches Moment (Summe aus Verbrennungsmotor und E-Motor), wird ";
CM_ SG_ 168 MO_Mom_Begr_stat "Einheitenloser Wert! Faktor in MO_Faktor_Momente (CAN V6.x) bzw. MO_Faktor_Momente_02 (CAN V7.x) in Motor_Code_01 beachten!

Bei aktueller Drehzahl quasistationär (nach ca. 3..5 s) max. mögliches Moment (Summe aus max. Moment des Verbrennungsmotors aus ";
CM_ SG_ 168 MO_Mom_neg_verfuegbar "Einheitenloser Wert! Faktor in MO_Faktor_Momente (CAN V6.x) bzw. MO_Faktor_Momente_02 (CAN V7.x) in Motor_Code_01 beachten!

Bei aktueller Drehzahl im nächsten Task (bei CAN-Übertragung z.B. 10ms) tatsächlich verfügbares negatives Moment (Summe aus Verl";
CM_ SG_ 168 MO_Momentenintegral_02 "100  %  entspricht volle Verfügbarkeit aktuell vorhanden. 0 % entspricht Integral bis Limit gefüllt, erhöhender Eingriff kann aktuell nicht berücksichtigt werden oder aufgrund eines Fehlers nicht verfügbar
";
CM_ SG_ 168 MO_QBit_Drehzahl_01 "AUDI D4: Zykluszeit: 10ms (siehe Zykluszeit schnell/Cycletime Fast)

Achtung:
Reduktion der Zykluszeit Motor_03 auf 10ms geplant.
Projektabhängig soll künftig mit 10ms gesendet werden.
Empfänger die in weiteren Konzern-Projekten eingesetzt werden müs";
CM_ SG_ 168 Motor_12_BZ "Botschaft asynchron geroutet. Zählerwert kann springen.";
CM_ SG_ 168 Motor_12_CRC "Für MLB:
'Berechnung siehe Lastenheft 'Kommunikationsabsicherung für FlexRay und CAN''

Ab MQB und MLBevo:
'Berechnung siehe Lastenheft 'End-to-End Kommunikationsabsicherung'

Endwerte siehe Begleitdokument 'S-PDU Kennungsfolgen'";

CM_ SG_ 958 MO_Aussp_Anlass "Das Signal zeigt an, ob die Wiederholstartsperre aktiv ist. D. h. eine Ansteuerung des Anlassers wird auch bei erfüllten Startvoraussetzungen (HS: Interlock betätigt bzw. AT: P/N eingelegt und Bremse betätigt) nicht erfolgen.";
CM_ SG_ 958 MO_BKV_Unterdruckwarnung "Über die Unterdruckwarnung signalisiert das MSG dem ESP, dass kein ausreichender Unterdruck für den BKV zur Verfügung gestellt werden kann.";
CM_ SG_ 958 MO_BLS "Ungefiltertes Rohsignal des Bremslichtschalters, nur wenn HW-Eingang bestückt und ausgewertet wird. Bei Motoren ohne genutzten HW-Eingang wird kein Ersatzwert (bspw. SW-Signal über CAN) ausgegeben!
Bei AUDI muss das Signal wg. Bremslichtfunktion immer be";
CM_ SG_ 958 MO_BMS_NV_Anf_stuetzen "Garantierte Unterstützung des Zusatzspeichers ist erforderlich. Zusatzspeicher muss an das Versorgungsnezt angebunden werden. ";
CM_ SG_ 958 MO_EKlKomLeiRed "Anforderung an die Klimasteuerung, die Leistungsaufnahme des E-Kompressors bei schlechtem SOC und in bestimmten Fahrsituationen zu begrenzen. (Das bereits bestehende Signal 'Klimakompressor aus' als stets umzusetzende Anforderung bleibt unverändert besteh";
CM_ SG_ 958 MO_Ext_E_Fahrt_aktiv "Funktionsrückmeldung zum erw. E-Fahr-Betrieb über Lampe/LED im E-Mode-Taster";
CM_ SG_ 958 MO_Fahrer_bremst "Redundante Bremsinformation vom Motor.

MLB:
AUDI D4: Zykluszeit: 10ms (siehe Zykluszeit schnell/Cycletime Fast)
Im AUDI B8 wird in diesem Bit der Wert der ESP-CAN-Information 'ESP_Fahrer_bremst' ausgegeben.

Achtung:
Reduktion der Zykluszeit Motor";
CM_ SG_ 958 MO_FMAus_aktiv "Das Signal gibt Rückmeldung ob Freilauf Motor aus aktiv ist. Beleibt auch 0km/h (unterhalb der StartStopp Schwelle) weiterhin aktiv.";
CM_ SG_ 958 MO_FMAus_Startvariante "Startvariante beim Motorstart aus der Freilauf-Motor-AUS Phase";
CM_ SG_ 958 MO_Freig_Anlass "Bit wird gesetzt, wenn der Motor beim Automatikstart gestartet werden darf (Motorstillstand, Emissionsmaßnahmen sind erfüllt).";
CM_ SG_ 958 MO_Freig_Reku "Empfehlung des Motor-SG's zur Spannungsabsenkung/-anhebung für den Rekuperationsbetrieb";
CM_ SG_ 958 MO_Freigabe_Segeln "Freigabebit des Segelbetriebs im Getriebe. Bedingt durch bestimmte Diagnosen und Adaptionen des MSGs, die nur im Schub möglich sind, darf nicht jede Schubphase für einen Segelbetrieb genutzt werden. Eine Freigabe bleibt auch außerhalb einer Schubphase bes";
CM_ SG_ 958 MO_Gangposition "MLB:
Stellung des Wählhebels in der Schaltgasse des Handschaltgetriebes.
MLBevo: 
Ausweitung der Bedienung auch auf Automatikgetriebe;
Routing des Signals GE_Fahrstufe: 
1. Position_R (dez. 6) auf MO_Gangposition: Gang_R (dez. 13) wegen Entfall Signa";
CM_ SG_ 958 MO_Handshake_STH "Es gilt: Signalspec MO_Handshake v1.0

Handshake zwischen MSG und STH. Wenn das MSG die EKP aufgrund einer STH-Anforderung ansteuert und kein Fehlereintrag bzgl. EKP/KPE/NDR vorliegt, wird das Bit gesetzt.";
CM_ SG_ 958 MO_HYB_Fahrbereitschaft "Signal steuert u.a. in der Lenkhilfe zusammen mit weiteren Informationen den Modewechsel in den 'Drivemode'
Grüne Anzeige im Kombiinstrument zur Signalisierung der Bereitschaft des Hybridsystems.";
CM_ SG_ 958 MO_HYB_VM_aktiv "0 = VMotor wird nicht aktiv gehalten (nVM < n_min und keine LL-Regelung aktiv)
1 = VMotor aktiv (ab der ersten Einspritzung; gilt auch für Schubbetrieb, wenn VMotor spätestens durch LLRegelung befeuert würde)
Verwendet zur Bestimmung des Ist-Zustandes";
CM_ SG_ 958 MO_Interlock "Das Motorsteuergerät gibt die Information aus, ab wann der Kupplungsschalter durch das Motorsteuergerät als getreten gesehen wird.
Bei Systemen für Start Stopp muss das Interlocksignal für einen Start durch das MSG generiert werden, sobald der Schalthebe";
CM_ SG_ 958 MO_Kickdown "Es gilt: Signalspec MO_Kickdown v1.0";
CM_ SG_ 958 MO_Kl_50 "Klemme 50: Startausführung durch Ritzelstarter

MLB: nicht von allen Motoren gesendet
MQB/MLBevo: gesendet von allen Motoren";
CM_ SG_ 958 MO_Kl_75 "Klemme X
";
CM_ SG_ 958 MO_Klima_Eingr "Eingriffe des Motor bei der Klima";
CM_ SG_ 958 MO_KomFehler_ESP "Anzeige Kommunikationsfehler bei Empfang vom ESP";
CM_ SG_ 958 MO_Konsistenz_Bremsped "MLB:

AUDI D4: Zykluszeit: 10ms (siehe Zykluszeit schnell/Cycletime Fast)
Siehe 'Funktionsspezifikation Bremslichtinfo B8'

Achtung:
Reduktion der Zykluszeit Motor_03 auf 10ms geplant.
Projektabhängig soll künftig mit 10ms gesendet werden.
Empfäng";
CM_ SG_ 958 MO_Kuppl_schalter "MLB:
Das Motorsteuergerät gibt die Information aus, ab wann der Kupplungsschalter durch das Motorsteuergerät als getreten gesehen wird
0x0: Schalter sagt betätigt (Ausgekuppelt)
0x1: Schalter sagt nicht betätigt (Eingekuppelt)

MQB:
Nur Handschalter";
CM_ SG_ 958 MO_Motor_laeuft "Das Motorsteuergerät gibt die Information aus, ab wann der Motor verbrennungsbedingt autark läuft und durch zuschaltbare Nebenaggregate mechanisch belastbar ist (z.B. durch Generator, Klimakompressor, etc.).

Die 'Motor läuft' Information wird ausgegebe";
CM_ SG_ 958 MO_PTC_Status "Status-Rückmeldung vom MSG zum aktuellen PTC-Status (stufiges PTC, Relais am MSG). Bei Ansteuerung eines stufigen PTC durch ein anderes SG beschreibt das Signal die vom MSG freigegebene PTC-Stufe.";
CM_ SG_ 958 MO_QBit_Fahrer_bremst "MLB:
AUDI D4: Zykluszeit: 10ms (siehe Zykluszeit schnell/Cycletime Fast)

Achtung:
Reduktion der Zykluszeit Motor_03 auf 10ms geplant.
Projektabhängig soll künftig mit 10ms gesendet werden.
Empfänger die in weiteren Konzern-Projekten eingesetzt werd";
CM_ SG_ 958 MO_QBit_Gangposition "Qualitätsbit zum Signal MO_Gangposition";
CM_ SG_ 958 MO_QBit_KL_75 "Q - Bit für das KL 75 Signal zur Vermeidung der fehlerhaften Erkennung von Motorstarts. 
Wird auf 1 gesetzt, solange das Motorsteuergerät KL15 = AUS erkannt hat.";
CM_ SG_ 958 MO_Remotestart_Betrieb "Das MSG ist für den Remotestart-Betrieb bereit. Nach Empfang der Motorstartanforderung für RSt-Betrieb durch BCM wird der Fahrzeugmotor gestartet und solange der Motor läuft, bleibt dieses Bit aktiv. Dieses Signal ist nur zur Verwendung durch das BCM zur ";
CM_ SG_ 958 MO_Remotestart_moeglich "Wenn Bit gesetzt, würde das MSG bei entsprechender Anforderung durch das BCM den Remotestartbetrieb einleiten, d.h. das MSG ist remotestartfähig und es liegen aktuell keine relevanten Fehler oder andere Abbruchgründe vor.";
CM_ SG_ 958 MO_Signalquelle_Gangposition "Signalquelle des Signals MO_Gangposition
0: Signalquelle Gangpositionssensor
1: Signalquelle Modellwert (v/n)";
CM_ SG_ 958 MO_StartStopp_Fahrerwunsch "Fahreraktivität Start/Stop";
CM_ SG_ 958 MO_StartStopp_Motorstopp "Motor-Stopp durch Start/Stopp-Koordinator
HYBRID:
Wenn MO_Hybridfahrzeug = 1 gilt:
Verbrennungsmotor durch Hybrid-Koordinator im MSG ausgeschaltet. 
Die definierten Start/Stopp-Signale beziehen sich nur auf den Verbrennungsmotor!";
CM_ SG_ 958 MO_StartStopp_Status "Aktivitätsstatus Start/Stopp-Koordinator
HYBRID:
Wenn MO_Hybridfahrzeug = 1 gilt:
Signal bezieht sich nur auf den Verbrennungsmotor, nicht auf den Hybridantrieb
";
CM_ SG_ 958 MO_StartStopp_Wiederstart "Motorwiederstart durch Start/Stopp-Koordinator
HYBRID:
Wenn MO_Hybridfahrzeug =1 gilt:
Warnung vor Spannungseinbruch beim Zustart des Verbrennungsmotors. 
-nicht relevant, da derzeit kein Start über 12V-Starter geplant-
Dieses Signal wird nur vom Hyb";
CM_ SG_ 958 MO_StartVorauss_erfuellt "Dient der Fallunterscheidung bei ZAT-Betätigung im Zustand 'KL15 ein' (bei nicht gesetztem Signal folgt KL15 aus, bei gesetztem Signal folgt setzen KL50-Anf.)

0: Signal nicht bedient 
1: Voraussetzungen zur Antriebsstrangaktivierung / Startvoraussetzu";
CM_ SG_ 958 MO_Text_Geschw_red "Anforderung an das Kombi die Textmeldung 'Geschwindigkeitsreduzierung' anzuzeigen";
CM_ SG_ 958 MO_Zylinderabschaltung "Status Zylinderabschaltung Motor";
CM_ SG_ 958 Motor_14_CRC "Ab MQB und MLBevo:
'Berechnung siehe Lastenheft 'End-to-End Kommunikationsabsicherung'

Endwerte siehe Begleitdokument 'S-PDU Kennungsfolgen'";

CM_ SG_ 1648 MO1_Freigabe_Info_WFS "WFS-Freigabeinformation";
CM_ SG_ 1648 MO1_Freigabe_Verfallsinfo_WFS "WFS-Freigabeverfallsinformation";
CM_ SG_ 1648 MO1_Sperr_Info_WFS "WFS-Sperrinformation";
CM_ SG_ 1648 MO_Abstellzeit "Abstelldauer nach letztem KL15 aus

Hinweis: 
Ehemaliger Fehlerwert 0xFF wird senderseitig nicht unterstützt. 
Diesen Wert aus Kompatibilitätsgründen nicht neu belegen!";
CM_ SG_ 1648 MO_Abstellzeit_Status "Statusinformation zur Abstellzeit
0: Die dem Status zugeordnete Variable konnte noch nicht berechnet werden. 
1: Die dem Status zugehörige Variable wurde korrekt berechnet. 
2: Der Wert der zugehörigen Variablen ist nur ein Minimalwert. 
3: Der Wert d";
CM_ SG_ 1648 MO_ANC_Kennfeld_Anf "Anforderung ANC Kennfeldumschaltung";
CM_ SG_ 1648 MO_Anzahl_Abgesch_Zyl "Gibt die Anzahl der abgeschalteten Zylinder an. In Übergangszuständen wird der Zielbetriebszustand angezeigt.";
CM_ SG_ 1648 MO_Bremslicht_Reku "Bremslicht (ggf. bei Rekuperation durch E-Motor) wird angesteuert";
CM_ SG_ 1648 MO_Drehzahl_Warnung "Warnhinweis zum Kombi im Fall einer fehlerbehafteten Drehzahlbegrenzung";
CM_ SG_ 1648 MO_EPCL "Die Anforderung der EPC-Lampe vom MSG ans Kombi soll durch das Bus-Signal MO_EPCL gemäß folgender Logik erfolgen:
MO_EPCL = 0 dez -> EPC Lampe aus, kein Text
MO_EPCL = 1 dez -> gelbe EPC-Symbolik, Text „Antrieb: Störung! Bitte Service aufsuchen“
MO_EPC";
CM_ SG_ 1648 MO_Ethanol_BS_Texte "Ethanol Brennstoff-Texte im Kombi

0 = kein Text
1 = E85 Warm_Up
2 = FlexFuel Warnung 3.Stufe (Too cold for ethanol)
3 = Warmfahrempfehlung MQB / FlexFuel Warnung 1.Stufe (Refuel with gasoline)
4 = FlexFuel Warnung 2. Stufe (Refuel with gasoline)
5";
CM_ SG_ 1648 MO_Fahrzeugtyp "Unterscheidet die Fahrzeugtypen bzgl. der Antriebsart";
CM_ SG_ 1648 MO_Fehler_Zylabsch "Fehlerstatus der Funktion Zylinderabschaltung ";
CM_ SG_ 1648 MO_Hybrid_StartStopp_LED "Ansteuerung der Funktions-LED der Hybrid Taste bzw. Start/Stop Deaktivierungstaste.
Der Start/Stopp-Master (derzeit im MSG) (oder ein künftiger Hybrid-Master) soll die Ansteuerung senden.";
CM_ SG_ 1648 MO_max_Ladedruck "maximal möglicher Ladedruck (zur Anpassung des Anzeigebereichs bei absoluter Ladedruckanzeige)";
CM_ SG_ 1648 MO_NMAX_Schaltanzeige "Maximaldrehzahl für Schaltanzeige";
CM_ SG_ 1648 MO_obere_Drehzahlgrenze "obere Drehzahlgrenze des Motors";
CM_ SG_ 1648 MO_StartStopp_PopUp "Das Signal zeigt an, ob der StSt-Status mittels Deaktivierungstaster geändert wurde. Ein Wechsel auf die Werte 01 oder 10 löst im Kombi ein entsprechendes PopUp aus. Bei einem Statuswechsel durch andere Signalquellen (z.B. Charisma, fehlerbedingte Abschal";
CM_ SG_ 1648 MO_Zylabsch_Texte "Zylinderabschaltung mode in Kombi, fuer Zylinderabschaltung";
CM_ SG_ 1648 MO_Zylabsch_Texte_02 "ZAS-Anzeige für den Fahrer im Kombi
0: kein ZAS (generell keinerlei ZAS-Anzeigen)  (Init für nicht ZAS-Motor)
1: ZAS im Vollmotorbetrieb  (Init für ZAS-Motor)
2: ZAS im Abschaltbetrieb: 1 Zyl aktiv
3: ZAS im Abschaltbetrieb: 2 Zyl aktiv
4: ZAS im Abs";
BA_DEF_REL_ BU_SG_REL_  "GenSigTimeoutTime" INT 0 65535;
BA_DEF_ BO_  "DiagRequest" ENUM "No", "Yes";
BA_DEF_ BO_  "DiagResponse" ENUM "No", "Yes";
BA_DEF_ BO_  "DiagState" ENUM "No", "Yes";
BA_DEF_ BO_  "GenMsgChkConstant" HEX 0 4095;
BA_DEF_ BO_  "GenMsgCycleTime" INT 0 65535;
BA_DEF_ BO_  "GenMsgCycleTimeFast" INT 0 65535;
BA_DEF_ BO_  "GenMsgDelayTime" INT 0 100000;
BA_DEF_ BO_  "GenMsgILSupport" ENUM "No", "Yes";
BA_DEF_ BO_  "GenMsgNrOfRepetition" INT 0 100;
BA_DEF_ BO_  "GenMsgPDUConstants" STRING;
BA_DEF_ BO_  "GenMsgSendType" ENUM "Cyclic", "not_used", "not_used", "not_used", "not_used", "not_used", "not_used", "IfActive", "NoMsgSendType";
BA_DEF_ BO_  "GenMsgStartDelayTime" INT 0 100000;
BA_DEF_ BO_  "NmMessage" ENUM "No", "Yes";
BA_DEF_ BO_  "NmhMessage" ENUM "No", "Yes";
BA_DEF_ BO_  "MsgType" ENUM "Application", "NM ", "NMH", "TP2.0", "ISO-TP ", "BAP", "EID", "KS", "XCP_PRE_CONFIGURED", "XCP_RUNTIME_CONFIGURED";
BA_DEF_ BO_  "VAGTP20_API" HEX 0 255;
BA_DEF_ BO_  "VAGTP20_DynConnection" ENUM "No", "Yes";
BA_DEF_ BO_  "VAGTP20_DynSetup" ENUM "No", "Yes";
BA_DEF_ BO_  "VAGTP20_StatConnection" ENUM "No", "Yes";
BA_DEF_ SG_  "GenSigActiveRepetitions" INT -2147483648 2147483647;
BA_DEF_ SG_  "GenSigSendType" ENUM "Cyclic", "OnWrite", "OnWriteWithRepetition", "OnChange", "OnChangeWithRepetition", "IfActive", "IfActiveWithRepetition", "NoSigSendType", "OnChangeAndIfActive", "OnChangeAndIfActiveWithRepetition";
BA_DEF_ SG_  "GenSigStartValue" INT -2147483648 2147483647;
BA_DEF_ SG_  "NWM-WakeupAllowed" ENUM "No", "Yes";
BA_DEF_ SG_  "GenSigFuncType" ENUM "NoFunction", "MsgCounter", "CRC-8", "XOR", "XOR-2", "DatedBit", "SW-Kl15", "CHK", "Constant", "Protocol", "CRC-8-SAE_J1850", "CRC-32", "DataLength", "DataID", "MsgCounter16", "SOK-Signatur", "Cluster";
BA_DEF_ SG_  "GenSigSwitchedByIgnition" ENUM "No", "Yes";
BA_DEF_ SG_  "Fehlerwert" HEX 0 2147483647;
BA_DEF_ SG_  "GenSigMissingSourceValue" HEX 0 2147483647;
BA_DEF_DEF_REL_  "GenSigTimeoutTime" 0;
BA_DEF_DEF_  "DiagRequest" "No";
BA_DEF_DEF_  "DiagResponse" "No";
BA_DEF_DEF_  "DiagState" "No";
BA_DEF_DEF_  "GenMsgChkConstant" 0;
BA_DEF_DEF_  "GenMsgCycleTime" 0;
BA_DEF_DEF_  "GenMsgCycleTimeFast" 0;
BA_DEF_DEF_  "GenMsgDelayTime" 0;
BA_DEF_DEF_  "GenMsgILSupport" "No";
BA_DEF_DEF_  "GenMsgNrOfRepetition" 0;
BA_DEF_DEF_  "GenMsgPDUConstants" "";
BA_DEF_DEF_  "GenMsgSendType" "NoMsgSendType";
BA_DEF_DEF_  "GenMsgStartDelayTime" 0;
BA_DEF_DEF_  "NmMessage" "No";
BA_DEF_DEF_  "NmhMessage" "No";
BA_DEF_DEF_  "MsgType" "Application";
BA_DEF_DEF_  "VAGTP20_API" 0;
BA_DEF_DEF_  "VAGTP20_DynConnection" "No";
BA_DEF_DEF_  "VAGTP20_DynSetup" "No";
BA_DEF_DEF_  "VAGTP20_StatConnection" "No";
BA_DEF_DEF_  "GenSigActiveRepetitions" 0;
BA_DEF_DEF_  "GenSigSendType" "NoSigSendType";
BA_DEF_DEF_  "GenSigStartValue" 0;
BA_DEF_DEF_  "NWM-WakeupAllowed" "No";
BA_DEF_DEF_  "GenSigFuncType" "NoFunction";
BA_DEF_DEF_  "GenSigSwitchedByIgnition" "Yes";
BA_DEF_DEF_  "Fehlerwert" 0;
BA_DEF_DEF_  "GenSigMissingSourceValue" 0;
BA_ "GenMsgCycleTime" BO_ 2463978723 100;
BA_ "GenMsgILSupport" BO_ 2463978723 1;
BA_ "GenMsgSendType" BO_ 2463978723 0;
BA_ "GenMsgCycleTime" BO_ 2463978724 100;
BA_ "GenMsgILSupport" BO_ 2463978724 1;
BA_ "GenMsgSendType" BO_ 2463978724 0;
BA_ "GenMsgCycleTime" BO_ 2463978725 100;
BA_ "GenMsgILSupport" BO_ 2463978725 1;
BA_ "GenMsgSendType" BO_ 2463978725 0;
BA_ "GenMsgCycleTime" BO_ 2463978726 100;
BA_ "GenMsgILSupport" BO_ 2463978726 1;
BA_ "GenMsgSendType" BO_ 2463978726 0;
BA_ "GenMsgChkConstant" BO_ 310 55;
BA_ "GenMsgCycleTime" BO_ 310 20;
BA_ "GenMsgILSupport" BO_ 310 1;
BA_ "GenMsgPDUConstants" BO_ 310 "0x37,0x37,0x37,0x37,0x37,0x37,0x37,0x37,0x37,0x37,0x37,0x37,0x37,0x37,0x37,0x37";
BA_ "GenMsgSendType" BO_ 310 0;
BA_ "GenMsgChkConstant" BO_ 960 195;
BA_ "GenMsgCycleTime" BO_ 960 100;
BA_ "GenMsgDelayTime" BO_ 960 10;
BA_ "GenMsgILSupport" BO_ 960 1;
BA_ "GenMsgPDUConstants" BO_ 960 "0xc3,0xc3,0xc3,0xc3,0xc3,0xc3,0xc3,0xc3,0xc3,0xc3,0xc3,0xc3,0xc3,0xc3,0xc3,0xc3";
BA_ "GenMsgSendType" BO_ 960 0;
BA_ "GenMsgCycleTime" BO_ 2549088272 500;
BA_ "GenMsgILSupport" BO_ 2549088272 1;
BA_ "GenMsgSendType" BO_ 2549088272 0;
BA_ "GenMsgStartDelayTime" BO_ 2549088272 75;
BA_ "GenMsgCycleTime" BO_ 2549088265 500;
BA_ "GenMsgILSupport" BO_ 2549088265 1;
BA_ "GenMsgSendType" BO_ 2549088265 0;
BA_ "GenMsgCycleTime" BO_ 2549088496 500;
BA_ "GenMsgILSupport" BO_ 2549088496 1;
BA_ "GenMsgSendType" BO_ 2549088496 0;
BA_ "GenMsgCycleTime" BO_ 779 200;
BA_ "GenMsgDelayTime" BO_ 779 50;
BA_ "GenMsgILSupport" BO_ 779 1;
BA_ "GenMsgSendType" BO_ 779 0;
BA_ "GenMsgCycleTime" BO_ 1719 1000;
BA_ "GenMsgDelayTime" BO_ 1719 100;
BA_ "GenMsgILSupport" BO_ 1719 1;
BA_ "GenMsgSendType" BO_ 1719 0;
BA_ "GenMsgCycleTime" BO_ 1720 500;
BA_ "GenMsgILSupport" BO_ 1720 1;
BA_ "GenMsgSendType" BO_ 1720 0;
BA_ "MsgType" BO_ 2549875047 4;
BA_ "MsgType" BO_ 2550006119 4;
BA_ "MsgType" BO_ 2549875078 4;
BA_ "MsgType" BO_ 2550006150 4;
BA_ "GenMsgCycleTime" BO_ 2527679653 960;
BA_ "GenMsgDelayTime" BO_ 2527679653 80;
BA_ "GenMsgILSupport" BO_ 2527679653 1;
BA_ "GenMsgSendType" BO_ 2527679653 0;
BA_ "GenMsgChkConstant" BO_ 810 41;
BA_ "GenMsgCycleTime" BO_ 810 500;
BA_ "GenMsgILSupport" BO_ 810 1;
BA_ "GenMsgPDUConstants" BO_ 810 "0x29,0x29,0x29,0x29,0x29,0x29,0x29,0x29,0x29,0x29,0x29,0x29,0x29,0x29,0x29,0x29";
BA_ "GenMsgSendType" BO_ 810 0;
BA_ "GenMsgChkConstant" BO_ 159 245;
BA_ "GenMsgCycleTime" BO_ 159 20;
BA_ "GenMsgILSupport" BO_ 159 1;
BA_ "GenMsgPDUConstants" BO_ 159 "0xf5,0xf5,0xf5,0xf5,0xf5,0xf5,0xf5,0xf5,0xf5,0xf5,0xf5,0xf5,0xf5,0xf5,0xf5,0xf5";
BA_ "GenMsgSendType" BO_ 159 0;
BA_ "GenMsgCycleTime" BO_ 2331595840 100;
BA_ "GenMsgDelayTime" BO_ 2331595840 10;
BA_ "GenMsgILSupport" BO_ 2331595840 1;
BA_ "GenMsgSendType" BO_ 2331595840 0;
BA_ "GenMsgCycleTime" BO_ 981 100;
BA_ "GenMsgDelayTime" BO_ 981 50;
BA_ "GenMsgILSupport" BO_ 981 1;
BA_ "GenMsgPDUConstants" BO_ 981 "0xc5,0x39,0xc7,0xf9,0x92,0xd8,0x24,0xce,0xf1,0xb5,0x7a,0xc4,0xbc,0x60,0xe3,0xd1";
BA_ "GenMsgSendType" BO_ 981 0;
BA_ "GenMsgCycleTime" BO_ 1624 1000;
BA_ "GenMsgDelayTime" BO_ 1624 50;
BA_ "GenMsgILSupport" BO_ 1624 1;
BA_ "GenMsgPDUConstants" BO_ 1624 "0x46,0x0f,0xe0,0xcc,0xbe,0xb1,0xd7,0xf1,0x1f,0x31,0xc1,0x25,0xb4,0x3e,0xc8,0xa3";
BA_ "GenMsgSendType" BO_ 1624 0;
BA_ "GenMsgChkConstant" BO_ 134 134;
BA_ "GenMsgCycleTime" BO_ 134 10;
BA_ "GenMsgILSupport" BO_ 134 1;
BA_ "GenMsgPDUConstants" BO_ 134 "0x86,0x86,0x86,0x86,0x86,0x86,0x86,0x86,0x86,0x86,0x86,0x86,0x86,0x86,0x86,0x86";
BA_ "GenMsgSendType" BO_ 134 0;
BA_ "GenMsgCycleTime" BO_ 168 20;
BA_ "GenMsgILSupport" BO_ 168 1;
BA_ "GenMsgPDUConstants" BO_ 168 "0x52,0x8c,0x50,0xee,0x4f,0xa6,0xcc,0xcf,0x7d,0x2f,0x98,0x6b,0x27,0x41,0x9f,0x93";
BA_ "GenMsgSendType" BO_ 168 0;
BA_ "GenMsgCycleTime" BO_ 958 100;
BA_ "GenMsgDelayTime" BO_ 958 10;
BA_ "GenMsgILSupport" BO_ 958 1;
BA_ "GenMsgPDUConstants" BO_ 958 "0x1f,0x28,0xc6,0x85,0xe6,0xf8,0xb0,0x19,0x5b,0x64,0x35,0x21,0xe4,0xf7,0x9c,0x24";
BA_ "GenMsgSendType" BO_ 958 0;
BA_ "GenMsgCycleTime" BO_ 1648 500;
BA_ "GenMsgDelayTime" BO_ 1648 20;
BA_ "GenMsgILSupport" BO_ 1648 1;
BA_ "GenMsgSendType" BO_ 1648 0;
BA_ "GenSigSendType" SG_ 2463978723 GNSS_DR_Nachrichtenpaket_ID2 0;
BA_ "GenSigSwitchedByIgnition" SG_ 2463978723 GNSS_DR_Nachrichtenpaket_ID2 0;
BA_ "GenSigSendType" SG_ 2463978723 GNSS_DR_Ortung_2D_Geschw_u_Grund 0;
BA_ "GenSigStartValue" SG_ 2463978723 GNSS_DR_Ortung_2D_Geschw_u_Grund 510;
BA_ "GenSigSwitchedByIgnition" SG_ 2463978723 GNSS_DR_Ortung_2D_Geschw_u_Grund 0;
BA_ "Fehlerwert" SG_ 2463978723 GNSS_DR_Ortung_2D_Geschw_u_Grund 511;
BA_ "GenSigSendType" SG_ 2463978723 GNSS_DR_Ortung_Ausrichtung 0;
BA_ "GenSigStartValue" SG_ 2463978723 GNSS_DR_Ortung_Ausrichtung 4094;
BA_ "GenSigSwitchedByIgnition" SG_ 2463978723 GNSS_DR_Ortung_Ausrichtung 0;
BA_ "Fehlerwert" SG_ 2463978723 GNSS_DR_Ortung_Ausrichtung 4095;
BA_ "GenSigSendType" SG_ 2463978724 GNSS_DR_Nachrichtenpaket_ID3 0;
BA_ "GenSigSwitchedByIgnition" SG_ 2463978724 GNSS_DR_Nachrichtenpaket_ID3 0;
BA_ "GenSigSendType" SG_ 2463978724 GNSS_DR_Ortung_Guete_Ausrichtung 0;
BA_ "GenSigStartValue" SG_ 2463978724 GNSS_DR_Ortung_Guete_Ausrichtung 62;
BA_ "GenSigSwitchedByIgnition" SG_ 2463978724 GNSS_DR_Ortung_Guete_Ausrichtung 0;
BA_ "Fehlerwert" SG_ 2463978724 GNSS_DR_Ortung_Guete_Ausrichtung 63;
BA_ "GenSigSendType" SG_ 2463978724 GNSS_DR_Ortung_Guete_Geschwindig 0;
BA_ "GenSigStartValue" SG_ 2463978724 GNSS_DR_Ortung_Guete_Geschwindig 62;
BA_ "GenSigSwitchedByIgnition" SG_ 2463978724 GNSS_DR_Ortung_Guete_Geschwindig 0;
BA_ "Fehlerwert" SG_ 2463978724 GNSS_DR_Ortung_Guete_Geschwindig 63;
BA_ "GenSigSendType" SG_ 2463978724 GNSS_DR_Ortung_Guete_horizontal 0;
BA_ "GenSigStartValue" SG_ 2463978724 GNSS_DR_Ortung_Guete_horizontal 254;
BA_ "GenSigSwitchedByIgnition" SG_ 2463978724 GNSS_DR_Ortung_Guete_horizontal 0;
BA_ "Fehlerwert" SG_ 2463978724 GNSS_DR_Ortung_Guete_horizontal 255;
BA_ "GenSigSendType" SG_ 2463978724 GNSS_DR_Ortung_Guete_vertikal 0;
BA_ "GenSigStartValue" SG_ 2463978724 GNSS_DR_Ortung_Guete_vertikal 62;
BA_ "GenSigSwitchedByIgnition" SG_ 2463978724 GNSS_DR_Ortung_Guete_vertikal 0;
BA_ "Fehlerwert" SG_ 2463978724 GNSS_DR_Ortung_Guete_vertikal 63;
BA_ "GenSigSendType" SG_ 2463978725 GNSS_DR_Nachrichtenpaket_ID4 0;
BA_ "GenSigSwitchedByIgnition" SG_ 2463978725 GNSS_DR_Nachrichtenpaket_ID4 0;
BA_ "GenSigSendType" SG_ 2463978725 GNSS_DR_Odometer 0;
BA_ "GenSigStartValue" SG_ 2463978725 GNSS_DR_Odometer 510;
BA_ "GenSigSwitchedByIgnition" SG_ 2463978725 GNSS_DR_Odometer 0;
BA_ "Fehlerwert" SG_ 2463978725 GNSS_DR_Odometer 511;
BA_ "GenSigSendType" SG_ 2463978725 GNSS_DR_Ortung_Hoehe 0;
BA_ "GenSigStartValue" SG_ 2463978725 GNSS_DR_Ortung_Hoehe 4094;
BA_ "GenSigSwitchedByIgnition" SG_ 2463978725 GNSS_DR_Ortung_Hoehe 0;
BA_ "Fehlerwert" SG_ 2463978725 GNSS_DR_Ortung_Hoehe 4095;
BA_ "GenSigSendType" SG_ 2463978725 GNSS_DR_Ortung_Zeit_in_GPSWoche 0;
BA_ "GenSigStartValue" SG_ 2463978725 GNSS_DR_Ortung_Zeit_in_GPSWoche 1073741822;
BA_ "GenSigSwitchedByIgnition" SG_ 2463978725 GNSS_DR_Ortung_Zeit_in_GPSWoche 0;
BA_ "Fehlerwert" SG_ 2463978725 GNSS_DR_Ortung_Zeit_in_GPSWoche 1073741823;
BA_ "GenSigSendType" SG_ 2463978725 GNSS_DR_Pitch 0;
BA_ "GenSigStartValue" SG_ 2463978725 GNSS_DR_Pitch 2046;
BA_ "GenSigSwitchedByIgnition" SG_ 2463978725 GNSS_DR_Pitch 0;
BA_ "Fehlerwert" SG_ 2463978725 GNSS_DR_Pitch 2047;
BA_ "GenSigSendType" SG_ 2463978726 GNSS_DR_Nachrichtenpaket_ID5 0;
BA_ "GenSigSwitchedByIgnition" SG_ 2463978726 GNSS_DR_Nachrichtenpaket_ID5 0;
BA_ "GenSigSendType" SG_ 2463978726 GNSS_DR_UTC_Zeit 0;
BA_ "GenSigSwitchedByIgnition" SG_ 2463978726 GNSS_DR_UTC_Zeit 0;
BA_ "GenSigSendType" SG_ 310 HAL_01_BZ 0;
BA_ "GenSigFuncType" SG_ 310 HAL_01_BZ 1;
BA_ "GenSigSwitchedByIgnition" SG_ 310 HAL_01_BZ 0;
BA_ "GenSigSendType" SG_ 310 HAL_01_CRC 0;
BA_ "GenSigFuncType" SG_ 310 HAL_01_CRC 2;
BA_ "GenSigSwitchedByIgnition" SG_ 310 HAL_01_CRC 0;
BA_ "GenSigSendType" SG_ 310 HAL_Charisma_FahrPr 0;
BA_ "GenSigSwitchedByIgnition" SG_ 310 HAL_Charisma_FahrPr 0;
BA_ "GenSigSendType" SG_ 310 HAL_Charisma_Status 0;
BA_ "GenSigSwitchedByIgnition" SG_ 310 HAL_Charisma_Status 0;
BA_ "GenSigSendType" SG_ 310 HAL_EFP_FahrPr 0;
BA_ "GenSigSwitchedByIgnition" SG_ 310 HAL_EFP_FahrPr 0;
BA_ "GenSigSendType" SG_ 310 HAL_Fahrerwunschwinkel_Soll 0;
BA_ "GenSigStartValue" SG_ 310 HAL_Fahrerwunschwinkel_Soll 1022;
BA_ "GenSigSwitchedByIgnition" SG_ 310 HAL_Fahrerwunschwinkel_Soll 0;
BA_ "Fehlerwert" SG_ 310 HAL_Fahrerwunschwinkel_Soll 1023;
BA_ "GenSigSendType" SG_ 310 HAL_max_Gradient 0;
BA_ "GenSigStartValue" SG_ 310 HAL_max_Gradient 126;
BA_ "GenSigSwitchedByIgnition" SG_ 310 HAL_max_Gradient 0;
BA_ "Fehlerwert" SG_ 310 HAL_max_Gradient 127;
BA_ "GenSigSendType" SG_ 310 HAL_QBit_Radwinkel 0;
BA_ "GenSigSwitchedByIgnition" SG_ 310 HAL_QBit_Radwinkel 0;
BA_ "GenSigSendType" SG_ 310 HAL_Radwinkel 0;
BA_ "GenSigStartValue" SG_ 310 HAL_Radwinkel 1022;
BA_ "GenSigSwitchedByIgnition" SG_ 310 HAL_Radwinkel 0;
BA_ "Fehlerwert" SG_ 310 HAL_Radwinkel 1023;
BA_ "GenSigSendType" SG_ 310 HAL_Status 0;
BA_ "GenSigSwitchedByIgnition" SG_ 310 HAL_Status 0;
BA_ "GenSigSendType" SG_ 310 HAL_Status_2 0;
BA_ "GenSigSwitchedByIgnition" SG_ 310 HAL_Status_2 0;
BA_ "GenSigSendType" SG_ 310 HAL_VZ_Fahrerwunschwinkel_Soll 0;
BA_ "GenSigSwitchedByIgnition" SG_ 310 HAL_VZ_Fahrerwunschwinkel_Soll 0;
BA_ "GenSigSendType" SG_ 310 HAL_VZ_Radwinkel 0;
BA_ "GenSigSwitchedByIgnition" SG_ 310 HAL_VZ_Radwinkel 0;
BA_ "GenSigSendType" SG_ 310 HAL_Warnungen 0;
BA_ "GenSigSwitchedByIgnition" SG_ 310 HAL_Warnungen 0;
BA_ "GenSigSendType" SG_ 310 HAL_Winkelbegrenzung 0;
BA_ "GenSigSwitchedByIgnition" SG_ 310 HAL_Winkelbegrenzung 0;
BA_ "GenSigSendType" SG_ 29 IMMO_Auth_Master_Slave07_Sig1 1;
BA_ "GenSigSwitchedByIgnition" SG_ 29 IMMO_Auth_Master_Slave07_Sig1 0;
BA_ "GenSigSendType" SG_ 28 IMMO_Auth_Slave07_Master_Sig1 1;
BA_ "GenSigSwitchedByIgnition" SG_ 28 IMMO_Auth_Slave07_Master_Sig1 0;
BA_ "GenSigSendType" SG_ 960 BCM_Ausparken_Betrieb 3;
BA_ "GenSigSwitchedByIgnition" SG_ 960 BCM_Ausparken_Betrieb 0;
BA_ "GenSigSendType" SG_ 960 BCM_Remotestart_Betrieb 3;
BA_ "GenSigSwitchedByIgnition" SG_ 960 BCM_Remotestart_Betrieb 0;
BA_ "GenSigSendType" SG_ 960 BCM_Remotestart_KL15_Anf 3;
BA_ "GenSigSwitchedByIgnition" SG_ 960 BCM_Remotestart_KL15_Anf 0;
BA_ "GenSigSendType" SG_ 960 BCM_Remotestart_MO_Start 3;
BA_ "GenSigSwitchedByIgnition" SG_ 960 BCM_Remotestart_MO_Start 0;
BA_ "GenSigSendType" SG_ 960 Klemmen_Status_01_BZ 0;
BA_ "GenSigFuncType" SG_ 960 Klemmen_Status_01_BZ 1;
BA_ "GenSigSwitchedByIgnition" SG_ 960 Klemmen_Status_01_BZ 0;
BA_ "GenSigSendType" SG_ 960 Klemmen_Status_01_CRC 0;
BA_ "GenSigFuncType" SG_ 960 Klemmen_Status_01_CRC 2;
BA_ "GenSigSwitchedByIgnition" SG_ 960 Klemmen_Status_01_CRC 0;
BA_ "GenSigSendType" SG_ 960 KST_Fahrerhinweis_1 3;
BA_ "GenSigSwitchedByIgnition" SG_ 960 KST_Fahrerhinweis_1 0;
BA_ "GenSigSendType" SG_ 960 KST_Fahrerhinweis_2 3;
BA_ "GenSigSwitchedByIgnition" SG_ 960 KST_Fahrerhinweis_2 0;
BA_ "GenSigSendType" SG_ 960 KST_Fahrerhinweis_4 3;
BA_ "GenSigSwitchedByIgnition" SG_ 960 KST_Fahrerhinweis_4 0;
BA_ "GenSigSendType" SG_ 960 KST_Fahrerhinweis_5 3;
BA_ "GenSigSwitchedByIgnition" SG_ 960 KST_Fahrerhinweis_5 0;
BA_ "GenSigSendType" SG_ 960 KST_Fahrerhinweis_6 3;
BA_ "GenSigSwitchedByIgnition" SG_ 960 KST_Fahrerhinweis_6 0;
BA_ "GenSigSendType" SG_ 960 KST_Warn_P1_ZST_def 3;
BA_ "GenSigSwitchedByIgnition" SG_ 960 KST_Warn_P1_ZST_def 0;
BA_ "GenSigSendType" SG_ 960 KST_Warn_P2_ZST_def 3;
BA_ "GenSigSwitchedByIgnition" SG_ 960 KST_Warn_P2_ZST_def 0;
BA_ "GenSigSendType" SG_ 960 RSt_Fahrerhinweise 3;
BA_ "GenSigSwitchedByIgnition" SG_ 960 RSt_Fahrerhinweise 0;
BA_ "GenSigSendType" SG_ 960 ZAS_Kl_15 3;
BA_ "NWM-WakeupAllowed" SG_ 960 ZAS_Kl_15 1;
BA_ "GenSigFuncType" SG_ 960 ZAS_Kl_15 6;
BA_ "GenSigSwitchedByIgnition" SG_ 960 ZAS_Kl_15 0;
BA_ "GenSigSendType" SG_ 960 ZAS_Kl_50_Startanforderung 3;
BA_ "GenSigSwitchedByIgnition" SG_ 960 ZAS_Kl_50_Startanforderung 0;
BA_ "GenSigSendType" SG_ 960 ZAS_Kl_Infotainment 3;
BA_ "GenSigSwitchedByIgnition" SG_ 960 ZAS_Kl_Infotainment 0;
BA_ "GenSigSendType" SG_ 960 ZAS_Kl_S 3;
BA_ "GenSigSwitchedByIgnition" SG_ 960 ZAS_Kl_S 0;
BA_ "GenSigSendType" SG_ 960 ZAS_Kl_X 3;
BA_ "GenSigSwitchedByIgnition" SG_ 960 ZAS_Kl_X 0;
BA_ "GenSigSendType" SG_ 2549088272 Gateway_Abschaltstufe 0;
BA_ "GenSigSwitchedByIgnition" SG_ 2549088272 Gateway_Abschaltstufe 0;
BA_ "GenSigSendType" SG_ 2549088272 Gateway_KompSchutz 0;
BA_ "GenSigSwitchedByIgnition" SG_ 2549088272 Gateway_KompSchutz 0;
BA_ "GenSigSendType" SG_ 2549088272 Gateway_Matrix_Generation 0;
BA_ "GenSigSwitchedByIgnition" SG_ 2549088272 Gateway_Matrix_Generation 0;
BA_ "GenSigSendType" SG_ 2549088272 Gateway_Matrix_Version 0;
BA_ "GenSigSwitchedByIgnition" SG_ 2549088272 Gateway_Matrix_Version 0;
BA_ "GenSigSendType" SG_ 2549088272 Gateway_Nachlauftyp 0;
BA_ "GenSigStartValue" SG_ 2549088272 Gateway_Nachlauftyp 2;
BA_ "GenSigSwitchedByIgnition" SG_ 2549088272 Gateway_Nachlauftyp 0;
BA_ "GenSigSendType" SG_ 2549088272 Gateway_SNI 0;
BA_ "GenSigStartValue" SG_ 2549088272 Gateway_SNI 16;
BA_ "GenSigSwitchedByIgnition" SG_ 2549088272 Gateway_SNI 0;
BA_ "GenSigSendType" SG_ 2549088272 Gateway_Transport_Mode 0;
BA_ "GenSigSwitchedByIgnition" SG_ 2549088272 Gateway_Transport_Mode 0;
BA_ "GenSigSendType" SG_ 2549088272 GW_KD_Fehler 0;
BA_ "GenSigSendType" SG_ 2549088272 NM_Gateway_Lokalaktiv 0;
BA_ "GenSigSwitchedByIgnition" SG_ 2549088272 NM_Gateway_Lokalaktiv 0;
BA_ "GenSigSendType" SG_ 2549088272 NM_Gateway_Subsystemaktiv 0;
BA_ "GenSigSendType" SG_ 2549088272 NM_Gateway_Wakeup 0;
BA_ "NWM-WakeupAllowed" SG_ 2549088272 NM_Gateway_Wakeup 1;
BA_ "GenSigSwitchedByIgnition" SG_ 2549088272 NM_Gateway_Wakeup 0;
BA_ "GenSigSendType" SG_ 2549088265 KN_Sekundaer_09_BusKnockOut 0;
BA_ "GenSigSwitchedByIgnition" SG_ 2549088265 KN_Sekundaer_09_BusKnockOut 0;
BA_ "GenSigSendType" SG_ 2549088265 KN_Sekundaer_09_BusKnockOutTimer 0;
BA_ "GenSigSwitchedByIgnition" SG_ 2549088265 KN_Sekundaer_09_BusKnockOutTimer 0;
BA_ "GenSigSendType" SG_ 2549088265 KN_Sekundaer_09_DiagPfad 0;
BA_ "GenSigSwitchedByIgnition" SG_ 2549088265 KN_Sekundaer_09_DiagPfad 0;
BA_ "GenSigSendType" SG_ 2549088265 KN_Sekundaer_09_ECUKnockOut 0;
BA_ "GenSigSwitchedByIgnition" SG_ 2549088265 KN_Sekundaer_09_ECUKnockOut 0;
BA_ "GenSigSendType" SG_ 2549088265 KN_Sekundaer_09_ECUKnockOutTimer 0;
BA_ "GenSigSwitchedByIgnition" SG_ 2549088265 KN_Sekundaer_09_ECUKnockOutTimer 0;
BA_ "GenSigSendType" SG_ 2549088265 NM_Sekundaer_09_Lokalaktiv 0;
BA_ "GenSigSwitchedByIgnition" SG_ 2549088265 NM_Sekundaer_09_Lokalaktiv 0;
BA_ "GenSigSendType" SG_ 2549088265 NM_Sekundaer_09_OTA_FC_Wakeup 0;
BA_ "GenSigSwitchedByIgnition" SG_ 2549088265 NM_Sekundaer_09_OTA_FC_Wakeup 0;
BA_ "GenSigSendType" SG_ 2549088265 NM_Sekundaer_09_Subsystemaktiv 0;
BA_ "GenSigSwitchedByIgnition" SG_ 2549088265 NM_Sekundaer_09_Subsystemaktiv 0;
BA_ "GenSigSendType" SG_ 2549088265 Sekundaer_09_Abschaltstufe 0;
BA_ "GenSigSwitchedByIgnition" SG_ 2549088265 Sekundaer_09_Abschaltstufe 0;
BA_ "GenSigSendType" SG_ 2549088265 Sekundaer_09_KD_Fehler 0;
BA_ "GenSigSwitchedByIgnition" SG_ 2549088265 Sekundaer_09_KD_Fehler 0;
BA_ "GenSigSendType" SG_ 2549088265 Sekundaer_09_KompSchutz 0;
BA_ "GenSigSwitchedByIgnition" SG_ 2549088265 Sekundaer_09_KompSchutz 0;
BA_ "GenSigSendType" SG_ 2549088265 Sekundaer_09_Nachlauftyp 0;
BA_ "GenSigStartValue" SG_ 2549088265 Sekundaer_09_Nachlauftyp 2;
BA_ "GenSigSwitchedByIgnition" SG_ 2549088265 Sekundaer_09_Nachlauftyp 0;
BA_ "GenSigSendType" SG_ 2549088265 Sekundaer_09_SNI 0;
BA_ "GenSigStartValue" SG_ 2549088265 Sekundaer_09_SNI 9;
BA_ "GenSigSwitchedByIgnition" SG_ 2549088265 Sekundaer_09_SNI 0;
BA_ "GenSigSendType" SG_ 2549088265 Sekundaer_09_Transport_Mode 0;
BA_ "GenSigSwitchedByIgnition" SG_ 2549088265 Sekundaer_09_Transport_Mode 0;
BA_ "GenSigSendType" SG_ 2549088496 KN_Sekundaer_F0_BusKnockOut 0;
BA_ "GenSigSwitchedByIgnition" SG_ 2549088496 KN_Sekundaer_F0_BusKnockOut 0;
BA_ "GenSigSendType" SG_ 2549088496 KN_Sekundaer_F0_BusKnockOutTimer 0;
BA_ "GenSigSwitchedByIgnition" SG_ 2549088496 KN_Sekundaer_F0_BusKnockOutTimer 0;
BA_ "GenSigSendType" SG_ 2549088496 KN_Sekundaer_F0_ECUKnockOut 0;
BA_ "GenSigSwitchedByIgnition" SG_ 2549088496 KN_Sekundaer_F0_ECUKnockOut 0;
BA_ "GenSigSendType" SG_ 2549088496 KN_Sekundaer_F0_ECUKnockOutTimer 0;
BA_ "GenSigSwitchedByIgnition" SG_ 2549088496 KN_Sekundaer_F0_ECUKnockOutTimer 0;
BA_ "GenSigSendType" SG_ 2549088496 NM_Sekundaer_F0_Lokalaktiv 0;
BA_ "GenSigSwitchedByIgnition" SG_ 2549088496 NM_Sekundaer_F0_Lokalaktiv 0;
BA_ "GenSigSendType" SG_ 2549088496 NM_Sekundaer_F0_Wakeup 0;
BA_ "GenSigSwitchedByIgnition" SG_ 2549088496 NM_Sekundaer_F0_Wakeup 0;
BA_ "GenSigSendType" SG_ 2549088496 Sekundaer_F0_Abschaltstufe 0;
BA_ "GenSigSwitchedByIgnition" SG_ 2549088496 Sekundaer_F0_Abschaltstufe 0;
BA_ "GenSigSendType" SG_ 2549088496 Sekundaer_F0_KD_Fehler 0;
BA_ "GenSigSwitchedByIgnition" SG_ 2549088496 Sekundaer_F0_KD_Fehler 0;
BA_ "GenSigSendType" SG_ 2549088496 Sekundaer_F0_KompSchutz 0;
BA_ "GenSigSwitchedByIgnition" SG_ 2549088496 Sekundaer_F0_KompSchutz 0;
BA_ "GenSigSendType" SG_ 2549088496 Sekundaer_F0_Nachlauftyp 0;
BA_ "GenSigStartValue" SG_ 2549088496 Sekundaer_F0_Nachlauftyp 2;
BA_ "GenSigSwitchedByIgnition" SG_ 2549088496 Sekundaer_F0_Nachlauftyp 0;
BA_ "GenSigSendType" SG_ 2549088496 Sekundaer_F0_SNI 0;
BA_ "GenSigStartValue" SG_ 2549088496 Sekundaer_F0_SNI 240;
BA_ "GenSigSwitchedByIgnition" SG_ 2549088496 Sekundaer_F0_SNI 0;
BA_ "GenSigSendType" SG_ 2549088496 Sekundaer_F0_Transport_Mode 0;
BA_ "GenSigSwitchedByIgnition" SG_ 2549088496 Sekundaer_F0_Transport_Mode 0;
BA_ "GenSigSendType" SG_ 779 KBI_ABS_Lampe 0;
BA_ "GenSigSwitchedByIgnition" SG_ 779 KBI_ABS_Lampe 0;
BA_ "GenSigSendType" SG_ 779 KBI_Airbag_Lampe 0;
BA_ "GenSigSwitchedByIgnition" SG_ 779 KBI_Airbag_Lampe 0;
BA_ "GenSigSendType" SG_ 779 KBI_angez_Geschw 0;
BA_ "GenSigSwitchedByIgnition" SG_ 779 KBI_angez_Geschw 0;
BA_ "GenSigSendType" SG_ 779 KBI_Anzeigefehler_LDW 0;
BA_ "GenSigSwitchedByIgnition" SG_ 779 KBI_Anzeigefehler_LDW 0;
BA_ "GenSigSendType" SG_ 779 KBI_Anzeigefehler_NV 0;
BA_ "GenSigSwitchedByIgnition" SG_ 779 KBI_Anzeigefehler_NV 0;
BA_ "GenSigSendType" SG_ 779 KBI_Anzeigefehler_SWA 0;
BA_ "GenSigSwitchedByIgnition" SG_ 779 KBI_Anzeigefehler_SWA 0;
BA_ "GenSigSendType" SG_ 779 KBI_Anzeigestatus_ACC 0;
BA_ "GenSigSwitchedByIgnition" SG_ 779 KBI_Anzeigestatus_ACC 0;
BA_ "GenSigSendType" SG_ 779 KBI_Anzeigestatus_GRA 0;
BA_ "GenSigSwitchedByIgnition" SG_ 779 KBI_Anzeigestatus_GRA 0;
BA_ "Fehlerwert" SG_ 779 KBI_Anzeigestatus_GRA 3;
BA_ "GenSigSendType" SG_ 779 KBI_Anzeigestatus_LIM 0;
BA_ "GenSigSwitchedByIgnition" SG_ 779 KBI_Anzeigestatus_LIM 0;
BA_ "Fehlerwert" SG_ 779 KBI_Anzeigestatus_LIM 3;
BA_ "GenSigSendType" SG_ 779 KBI_ARA_in_Anzeige 0;
BA_ "GenSigSwitchedByIgnition" SG_ 779 KBI_ARA_in_Anzeige 0;
BA_ "GenSigSendType" SG_ 779 KBI_Bestaetigung_ESP_Off 3;
BA_ "GenSigSendType" SG_ 779 KBI_BKL_Lampe 0;
BA_ "GenSigSwitchedByIgnition" SG_ 779 KBI_BKL_Lampe 0;
BA_ "GenSigSendType" SG_ 779 KBI_Einheit_Tacho 0;
BA_ "GenSigSwitchedByIgnition" SG_ 779 KBI_Einheit_Tacho 0;
BA_ "GenSigSendType" SG_ 779 KBI_ESP_Lampe 3;
BA_ "GenSigSwitchedByIgnition" SG_ 779 KBI_ESP_Lampe 0;
BA_ "GenSigSendType" SG_ 779 KBI_Fehler_Anzeige_ACC 0;
BA_ "GenSigSwitchedByIgnition" SG_ 779 KBI_Fehler_Anzeige_ACC 0;
BA_ "GenSigSendType" SG_ 779 KBI_GRA_Hauptschalter 0;
BA_ "GenSigSwitchedByIgnition" SG_ 779 KBI_GRA_Hauptschalter 0;
BA_ "Fehlerwert" SG_ 779 KBI_GRA_Hauptschalter 3;
BA_ "GenSigSendType" SG_ 779 KBI_Handbremse 0;
BA_ "GenSigSwitchedByIgnition" SG_ 779 KBI_Handbremse 0;
BA_ "GenSigSendType" SG_ 779 KBI_im_Stellgliedtest 0;
BA_ "GenSigSwitchedByIgnition" SG_ 779 KBI_im_Stellgliedtest 0;
BA_ "GenSigSendType" SG_ 779 KBI_Konsistenz_ACC 0;
BA_ "GenSigSwitchedByIgnition" SG_ 779 KBI_Konsistenz_ACC 0;
BA_ "GenSigSendType" SG_ 779 KBI_Lenkung_Lampe 3;
BA_ "GenSigSwitchedByIgnition" SG_ 779 KBI_Lenkung_Lampe 0;
BA_ "GenSigSendType" SG_ 779 KBI_MFA_v_Einheit_01 0;
BA_ "GenSigSwitchedByIgnition" SG_ 779 KBI_MFA_v_Einheit_01 0;
BA_ "GenSigSendType" SG_ 779 KBI_NV_in_Anzeige 0;
BA_ "GenSigSwitchedByIgnition" SG_ 779 KBI_NV_in_Anzeige 0;
BA_ "GenSigSendType" SG_ 779 KBI_PLA_in_Anzeige 3;
BA_ "GenSigSwitchedByIgnition" SG_ 779 KBI_PLA_in_Anzeige 0;
BA_ "GenSigSendType" SG_ 779 KBI_SILA_gueltig 0;
BA_ "GenSigSwitchedByIgnition" SG_ 779 KBI_SILA_gueltig 0;
BA_ "GenSigSendType" SG_ 779 KBI_Systemstatus 0;
BA_ "GenSigSwitchedByIgnition" SG_ 779 KBI_Systemstatus 0;
BA_ "GenSigSendType" SG_ 779 KBI_Tankwarnung 3;
BA_ "GenSigSwitchedByIgnition" SG_ 779 KBI_Tankwarnung 0;
BA_ "GenSigSendType" SG_ 779 KBI_Tankwarnung_ungueltig 0;
BA_ "GenSigStartValue" SG_ 779 KBI_Tankwarnung_ungueltig 1;
BA_ "GenSigSwitchedByIgnition" SG_ 779 KBI_Tankwarnung_ungueltig 0;
BA_ "GenSigSendType" SG_ 779 KBI_Taster_Fahrwerk 3;
BA_ "GenSigSwitchedByIgnition" SG_ 779 KBI_Taster_Fahrwerk 0;
BA_ "GenSigSendType" SG_ 779 KBI_Taster_Lift 3;
BA_ "GenSigSwitchedByIgnition" SG_ 779 KBI_Taster_Lift 0;
BA_ "GenSigSendType" SG_ 779 KBI_V_Digital 0;
BA_ "GenSigSwitchedByIgnition" SG_ 779 KBI_V_Digital 0;
BA_ "GenSigSendType" SG_ 779 KBI_Vorglueh_System_Lampe 0;
BA_ "GenSigSwitchedByIgnition" SG_ 779 KBI_Vorglueh_System_Lampe 0;
BA_ "GenSigSendType" SG_ 779 Kombi_01_BZ 0;
BA_ "GenSigFuncType" SG_ 779 Kombi_01_BZ 1;
BA_ "GenSigSwitchedByIgnition" SG_ 779 Kombi_01_BZ 0;
BA_ "GenSigSendType" SG_ 1719 KBI_aktive_Laengsfunktion 3;
BA_ "GenSigSendType" SG_ 1719 KBI_Aussen_Temp_gef 0;
BA_ "GenSigStartValue" SG_ 1719 KBI_Aussen_Temp_gef 254;
BA_ "GenSigSwitchedByIgnition" SG_ 1719 KBI_Aussen_Temp_gef 0;
BA_ "Fehlerwert" SG_ 1719 KBI_Aussen_Temp_gef 255;
BA_ "GenSigSendType" SG_ 1719 KBI_FoD_PopUP_Quittiert 3;
BA_ "GenSigSendType" SG_ 1719 KBI_FStatus_Tank 0;
BA_ "GenSigSwitchedByIgnition" SG_ 1719 KBI_FStatus_Tank 0;
BA_ "GenSigSendType" SG_ 1719 KBI_GRA_im_ACC 3;
BA_ "GenSigSwitchedByIgnition" SG_ 1719 KBI_GRA_im_ACC 0;
BA_ "GenSigSendType" SG_ 1719 KBI_Inhalt_Tank 0;
BA_ "GenSigStartValue" SG_ 1719 KBI_Inhalt_Tank 126;
BA_ "GenSigSwitchedByIgnition" SG_ 1719 KBI_Inhalt_Tank 0;
BA_ "Fehlerwert" SG_ 1719 KBI_Inhalt_Tank 127;
BA_ "GenSigSendType" SG_ 1719 KBI_Kilometerstand 0;
BA_ "GenSigStartValue" SG_ 1719 KBI_Kilometerstand 1048574;
BA_ "GenSigSwitchedByIgnition" SG_ 1719 KBI_Kilometerstand 0;
BA_ "Fehlerwert" SG_ 1719 KBI_Kilometerstand 1048575;
BA_ "GenSigSendType" SG_ 1719 KBI_LVDS_Lock 3;
BA_ "GenSigSwitchedByIgnition" SG_ 1719 KBI_LVDS_Lock 0;
BA_ "GenSigSendType" SG_ 1719 KBI_Oelwechsel_durchgefuehrt 0;
BA_ "GenSigSwitchedByIgnition" SG_ 1719 KBI_Oelwechsel_durchgefuehrt 0;
BA_ "GenSigSendType" SG_ 1719 KBI_QBit_Aussen_Temp_gef 0;
BA_ "GenSigStartValue" SG_ 1719 KBI_QBit_Aussen_Temp_gef 1;
BA_ "GenSigSwitchedByIgnition" SG_ 1719 KBI_QBit_Aussen_Temp_gef 0;
BA_ "GenSigSendType" SG_ 1719 KBI_RDK_Kalibrier_Anf 3;
BA_ "GenSigSwitchedByIgnition" SG_ 1719 KBI_RDK_Kalibrier_Anf 0;
BA_ "GenSigSendType" SG_ 1719 KBI_Reserve_Warnung_Sek 3;
BA_ "GenSigSwitchedByIgnition" SG_ 1719 KBI_Reserve_Warnung_Sek 0;
BA_ "GenSigSendType" SG_ 1719 KBI_Standzeit_02 0;
BA_ "GenSigStartValue" SG_ 1719 KBI_Standzeit_02 131070;
BA_ "GenSigSwitchedByIgnition" SG_ 1719 KBI_Standzeit_02 0;
BA_ "Fehlerwert" SG_ 1719 KBI_Standzeit_02 131071;
BA_ "GenSigSendType" SG_ 1719 KBI_TA_gewaehlt_Fahrer 0;
BA_ "GenSigSendType" SG_ 1720 KBI_BCmE_aktiv 0;
BA_ "GenSigSwitchedByIgnition" SG_ 1720 KBI_BCmE_aktiv 0;
BA_ "GenSigSendType" SG_ 1720 KBI_GAP_Warn_Zeit_abgelaufen 0;
BA_ "GenSigSwitchedByIgnition" SG_ 1720 KBI_GAP_Warn_Zeit_abgelaufen 0;
BA_ "GenSigSendType" SG_ 1720 KBI_Max_Tankinhalt 0;
BA_ "GenSigStartValue" SG_ 1720 KBI_Max_Tankinhalt 254;
BA_ "GenSigSwitchedByIgnition" SG_ 1720 KBI_Max_Tankinhalt 0;
BA_ "Fehlerwert" SG_ 1720 KBI_Max_Tankinhalt 255;
BA_ "GenSigSendType" SG_ 1720 KBI_Nachtanken_erkannt 0;
BA_ "GenSigSwitchedByIgnition" SG_ 1720 KBI_Nachtanken_erkannt 0;
BA_ "GenSigSendType" SG_ 1720 KBI_Quittierung_cAQP 0;
BA_ "GenSigSwitchedByIgnition" SG_ 1720 KBI_Quittierung_cAQP 0;
BA_ "GenSigSendType" SG_ 1720 KBI_Quittierung_Naesse 0;
BA_ "GenSigSwitchedByIgnition" SG_ 1720 KBI_Quittierung_Naesse 0;
BA_ "GenSigSendType" SG_ 1720 KBI_Reifenumfang 0;
BA_ "GenSigFuncType" SG_ 1720 KBI_Reifenumfang 8;
BA_ "GenSigSwitchedByIgnition" SG_ 1720 KBI_Reifenumfang 0;
BA_ "GenSigSendType" SG_ 1720 KBI_Reifenumfang_Sekundaer 0;
BA_ "GenSigSwitchedByIgnition" SG_ 1720 KBI_Reifenumfang_Sekundaer 0;
BA_ "GenSigSendType" SG_ 1720 KBI_Sparhinweis_quittiert 0;
BA_ "GenSigSwitchedByIgnition" SG_ 1720 KBI_Sparhinweis_quittiert 0;
BA_ "GenSigSendType" SG_ 1720 KBI_Tankfuellstand_Prozent 0;
BA_ "GenSigStartValue" SG_ 1720 KBI_Tankfuellstand_Prozent 126;
BA_ "GenSigSwitchedByIgnition" SG_ 1720 KBI_Tankfuellstand_Prozent 0;
BA_ "Fehlerwert" SG_ 1720 KBI_Tankfuellstand_Prozent 127;
BA_ "GenSigSendType" SG_ 1720 KBI_Tankinhalt_hochaufl 0;
BA_ "GenSigStartValue" SG_ 1720 KBI_Tankinhalt_hochaufl 16382;
BA_ "GenSigSwitchedByIgnition" SG_ 1720 KBI_Tankinhalt_hochaufl 0;
BA_ "Fehlerwert" SG_ 1720 KBI_Tankinhalt_hochaufl 16383;
BA_ "GenSigSendType" SG_ 1720 KBI_Variante 0;
BA_ "GenSigSwitchedByIgnition" SG_ 1720 KBI_Variante 0;
BA_ "GenSigSendType" SG_ 1720 KBI_Variante_USA 0;
BA_ "GenSigSwitchedByIgnition" SG_ 1720 KBI_Variante_USA 0;
BA_ "GenSigSendType" SG_ 2549875047 KS_eCall_Req_Data 3;
BA_ "GenSigFuncType" SG_ 2549875047 KS_eCall_Req_Data 9;
BA_ "GenSigSwitchedByIgnition" SG_ 2549875047 KS_eCall_Req_Data 0;
BA_ "GenSigSendType" SG_ 2550006119 KS_eCall_Resp_Data 3;
BA_ "GenSigFuncType" SG_ 2550006119 KS_eCall_Resp_Data 9;
BA_ "GenSigSwitchedByIgnition" SG_ 2550006119 KS_eCall_Resp_Data 0;
BA_ "GenSigSendType" SG_ 2549875078 KS_OTA_FC_Req_Data 3;
BA_ "GenSigFuncType" SG_ 2549875078 KS_OTA_FC_Req_Data 9;
BA_ "GenSigSwitchedByIgnition" SG_ 2549875078 KS_OTA_FC_Req_Data 0;
BA_ "GenSigSendType" SG_ 2550006150 KS_OTA_FC_Resp_Data 3;
BA_ "GenSigFuncType" SG_ 2550006150 KS_OTA_FC_Resp_Data 9;
BA_ "GenSigSwitchedByIgnition" SG_ 2550006150 KS_OTA_FC_Resp_Data 0;
BA_ "GenSigSendType" SG_ 2527679653 MXB_LAPP_Freigabe 3;
BA_ "GenSigSendType" SG_ 2527679653 MXB_LAPP_Status_FL 3;
BA_ "GenSigSendType" SG_ 2527679653 MXB_LAPP_Statuscode 3;
BA_ "GenSigStartValue" SG_ 2527679653 MXB_LAPP_Statuscode 1023;
BA_ "GenSigSendType" SG_ 2527679653 MXB_LAPP_ZR_Sondermodus_Anf 3;
BA_ "GenSigSendType" SG_ 810 EPS_01_BZ 0;
BA_ "GenSigFuncType" SG_ 810 EPS_01_BZ 1;
BA_ "GenSigSwitchedByIgnition" SG_ 810 EPS_01_BZ 0;
BA_ "GenSigSendType" SG_ 810 EPS_01_CRC 0;
BA_ "GenSigFuncType" SG_ 810 EPS_01_CRC 2;
BA_ "GenSigSwitchedByIgnition" SG_ 810 EPS_01_CRC 0;
BA_ "GenSigSendType" SG_ 810 EPS_Anf_KL 0;
BA_ "GenSigSwitchedByIgnition" SG_ 810 EPS_Anf_KL 0;
BA_ "GenSigSendType" SG_ 810 EPS_ARA_Status 0;
BA_ "GenSigSwitchedByIgnition" SG_ 810 EPS_ARA_Status 0;
BA_ "GenSigSendType" SG_ 810 EPS_Charisma_FahrPr 0;
BA_ "GenSigSwitchedByIgnition" SG_ 810 EPS_Charisma_FahrPr 0;
BA_ "GenSigSendType" SG_ 810 EPS_Charisma_Status 0;
BA_ "GenSigSwitchedByIgnition" SG_ 810 EPS_Charisma_Status 0;
BA_ "GenSigSendType" SG_ 810 EPS_Endanschlag 0;
BA_ "Fehlerwert" SG_ 810 EPS_Endanschlag 3;
BA_ "GenSigSendType" SG_ 810 EPS_Fehlerlampe 0;
BA_ "GenSigSwitchedByIgnition" SG_ 810 EPS_Fehlerlampe 0;
BA_ "GenSigSendType" SG_ 810 EPS_Lenkerposition 0;
BA_ "GenSigFuncType" SG_ 810 EPS_Lenkerposition 8;
BA_ "GenSigSwitchedByIgnition" SG_ 810 EPS_Lenkerposition 0;
BA_ "GenSigSendType" SG_ 810 EPS_PLA_Status 0;
BA_ "GenSigSwitchedByIgnition" SG_ 810 EPS_PLA_Status 0;
BA_ "GenSigSendType" SG_ 810 EPS_PWR_Abbruch 0;
BA_ "GenSigSwitchedByIgnition" SG_ 810 EPS_PWR_Abbruch 0;
BA_ "GenSigSendType" SG_ 810 EPS_PWR_Fehler 0;
BA_ "GenSigSwitchedByIgnition" SG_ 810 EPS_PWR_Fehler 0;
BA_ "GenSigSendType" SG_ 810 EPS_SpannungsAnf 0;
BA_ "GenSigSwitchedByIgnition" SG_ 810 EPS_SpannungsAnf 0;
BA_ "GenSigSendType" SG_ 810 EPS_Warnungen 0;
BA_ "GenSigSwitchedByIgnition" SG_ 810 EPS_Warnungen 0;
BA_ "GenSigSendType" SG_ 159 EPS_03_BZ 0;
BA_ "GenSigFuncType" SG_ 159 EPS_03_BZ 1;
BA_ "GenSigSwitchedByIgnition" SG_ 159 EPS_03_BZ 0;
BA_ "GenSigSendType" SG_ 159 EPS_03_CRC 0;
BA_ "GenSigFuncType" SG_ 159 EPS_03_CRC 2;
BA_ "GenSigSwitchedByIgnition" SG_ 159 EPS_03_CRC 0;
BA_ "GenSigSendType" SG_ 159 EPS_Berechneter_LW 0;
BA_ "GenSigStartValue" SG_ 159 EPS_Berechneter_LW 4094;
BA_ "GenSigSwitchedByIgnition" SG_ 159 EPS_Berechneter_LW 0;
BA_ "Fehlerwert" SG_ 159 EPS_Berechneter_LW 4095;
BA_ "GenSigSendType" SG_ 159 EPS_BLW_QBit 0;
BA_ "GenSigSwitchedByIgnition" SG_ 159 EPS_BLW_QBit 0;
BA_ "GenSigSendType" SG_ 159 EPS_DSR_Status_02 0;
BA_ "GenSigStartValue" SG_ 159 EPS_DSR_Status_02 14;
BA_ "GenSigSwitchedByIgnition" SG_ 159 EPS_DSR_Status_02 0;
BA_ "GenSigSendType" SG_ 159 EPS_HCA_Status_02 0;
BA_ "GenSigStartValue" SG_ 159 EPS_HCA_Status_02 14;
BA_ "GenSigSwitchedByIgnition" SG_ 159 EPS_HCA_Status_02 0;
BA_ "GenSigSendType" SG_ 159 EPS_Lenkmoment 0;
BA_ "GenSigStartValue" SG_ 159 EPS_Lenkmoment 1022;
BA_ "GenSigSwitchedByIgnition" SG_ 159 EPS_Lenkmoment 0;
BA_ "Fehlerwert" SG_ 159 EPS_Lenkmoment 1023;
BA_ "GenSigSendType" SG_ 159 EPS_Lenkmoment_QBit 0;
BA_ "GenSigSwitchedByIgnition" SG_ 159 EPS_Lenkmoment_QBit 0;
BA_ "GenSigSendType" SG_ 159 EPS_Lenkungstyp 0;
BA_ "GenSigStartValue" SG_ 159 EPS_Lenkungstyp 15;
BA_ "GenSigSwitchedByIgnition" SG_ 159 EPS_Lenkungstyp 0;
BA_ "GenSigSendType" SG_ 159 EPS_VZ_BLW 0;
BA_ "GenSigSwitchedByIgnition" SG_ 159 EPS_VZ_BLW 0;
BA_ "GenSigSendType" SG_ 159 EPS_VZ_Lenkmoment 0;
BA_ "GenSigSwitchedByIgnition" SG_ 159 EPS_VZ_Lenkmoment 0;
BA_ "GenSigSendType" SG_ 2331595840 LHW_eventABSactivated 3;
BA_ "GenSigSwitchedByIgnition" SG_ 2331595840 LHW_eventABSactivated 0;
BA_ "GenSigSendType" SG_ 2331595840 LHW_eventAirBagDeployment 3;
BA_ "GenSigSwitchedByIgnition" SG_ 2331595840 LHW_eventAirBagDeployment 0;
BA_ "GenSigSendType" SG_ 2331595840 LHW_eventDisabledVehicle 3;
BA_ "GenSigSwitchedByIgnition" SG_ 2331595840 LHW_eventDisabledVehicle 0;
BA_ "GenSigSendType" SG_ 2331595840 LHW_eventFlatTire 3;
BA_ "GenSigSwitchedByIgnition" SG_ 2331595840 LHW_eventFlatTire 0;
BA_ "GenSigSendType" SG_ 2331595840 LHW_eventHardBraking 3;
BA_ "GenSigSwitchedByIgnition" SG_ 2331595840 LHW_eventHardBraking 0;
BA_ "GenSigSendType" SG_ 2331595840 LHW_eventHazardLights 3;
BA_ "GenSigSwitchedByIgnition" SG_ 2331595840 LHW_eventHazardLights 0;
BA_ "GenSigSendType" SG_ 2331595840 LHW_eventStabilityControlActive 3;
BA_ "GenSigSwitchedByIgnition" SG_ 2331595840 LHW_eventStabilityControlActive 0;
BA_ "GenSigSendType" SG_ 2331595840 LHW_eventTractionControlLoss 3;
BA_ "GenSigSwitchedByIgnition" SG_ 2331595840 LHW_eventTractionControlLoss 0;
BA_ "GenSigSendType" SG_ 981 BCM1_Abblendlicht_Anf 0;
BA_ "GenSigSwitchedByIgnition" SG_ 981 BCM1_Abblendlicht_Anf 0;
BA_ "GenSigSendType" SG_ 981 BCM1_Adaptive_Lichtvert_Anf 0;
BA_ "GenSigSwitchedByIgnition" SG_ 981 BCM1_Adaptive_Lichtvert_Anf 0;
BA_ "GenSigSendType" SG_ 981 BCM1_Allwetterlicht_Anf 0;
BA_ "GenSigSwitchedByIgnition" SG_ 981 BCM1_Allwetterlicht_Anf 0;
BA_ "GenSigSendType" SG_ 981 BCM1_Animationssperrung 3;
BA_ "GenSigStartValue" SG_ 981 BCM1_Animationssperrung 1;
BA_ "GenSigSwitchedByIgnition" SG_ 981 BCM1_Animationssperrung 0;
BA_ "GenSigSendType" SG_ 981 BCM1_Autobahnlicht_Anf 0;
BA_ "GenSigSwitchedByIgnition" SG_ 981 BCM1_Autobahnlicht_Anf 0;
BA_ "GenSigSendType" SG_ 981 BCM1_CH_aktiv 0;
BA_ "NWM-WakeupAllowed" SG_ 981 BCM1_CH_aktiv 1;
BA_ "GenSigSwitchedByIgnition" SG_ 981 BCM1_CH_aktiv 0;
BA_ "GenSigSendType" SG_ 981 BCM1_CH_LH_aktiv 0;
BA_ "GenSigSwitchedByIgnition" SG_ 981 BCM1_CH_LH_aktiv 0;
BA_ "GenSigSendType" SG_ 981 BCM1_Fernlicht_Anf 0;
BA_ "GenSigSwitchedByIgnition" SG_ 981 BCM1_Fernlicht_Anf 0;
BA_ "GenSigSendType" SG_ 981 BCM1_FOD_Sperrung_Animationen_HL 3;
BA_ "GenSigStartValue" SG_ 981 BCM1_FOD_Sperrung_Animationen_HL 2;
BA_ "GenSigSendType" SG_ 981 BCM1_FoD_Sperrung_WiBli 3;
BA_ "GenSigStartValue" SG_ 981 BCM1_FoD_Sperrung_WiBli 2;
BA_ "GenSigSendType" SG_ 981 BCM1_Gleitende_Leuchtw_Anf 3;
BA_ "GenSigSwitchedByIgnition" SG_ 981 BCM1_Gleitende_Leuchtw_Anf 0;
BA_ "GenSigSendType" SG_ 981 BCM1_GLW_Fernlicht_Anf 3;
BA_ "GenSigSwitchedByIgnition" SG_ 981 BCM1_GLW_Fernlicht_Anf 0;
BA_ "GenSigSendType" SG_ 981 BCM1_Kurvenlicht_links_Anf 0;
BA_ "GenSigSwitchedByIgnition" SG_ 981 BCM1_Kurvenlicht_links_Anf 0;
BA_ "GenSigSendType" SG_ 981 BCM1_Kurvenlicht_rechts_Anf 0;
BA_ "GenSigSwitchedByIgnition" SG_ 981 BCM1_Kurvenlicht_rechts_Anf 0;
BA_ "GenSigSendType" SG_ 981 BCM1_LH_aktiv 0;
BA_ "NWM-WakeupAllowed" SG_ 981 BCM1_LH_aktiv 1;
BA_ "GenSigSwitchedByIgnition" SG_ 981 BCM1_LH_aktiv 0;
BA_ "GenSigSendType" SG_ 981 BCM1_Nebellicht_Anf 0;
BA_ "GenSigSwitchedByIgnition" SG_ 981 BCM1_Nebellicht_Anf 0;
BA_ "GenSigSendType" SG_ 981 BCM1_Nebelschluss_Ahg_Anf 0;
BA_ "GenSigSwitchedByIgnition" SG_ 981 BCM1_Nebelschluss_Ahg_Anf 0;
BA_ "GenSigSendType" SG_ 981 BCM1_Nebelschluss_Fzg_Anf 0;
BA_ "GenSigSwitchedByIgnition" SG_ 981 BCM1_Nebelschluss_Fzg_Anf 0;
BA_ "GenSigSendType" SG_ 981 BCM1_Parklicht_li_Anf 0;
BA_ "GenSigSwitchedByIgnition" SG_ 981 BCM1_Parklicht_li_Anf 0;
BA_ "GenSigSendType" SG_ 981 BCM1_Parklicht_re_Anf 0;
BA_ "GenSigSwitchedByIgnition" SG_ 981 BCM1_Parklicht_re_Anf 0;
BA_ "GenSigSendType" SG_ 981 BCM1_Regenlicht_Anf 0;
BA_ "GenSigSwitchedByIgnition" SG_ 981 BCM1_Regenlicht_Anf 0;
BA_ "GenSigSendType" SG_ 981 BCM1_Schlusslicht_Anf 0;
BA_ "GenSigSwitchedByIgnition" SG_ 981 BCM1_Schlusslicht_Anf 0;
BA_ "GenSigSendType" SG_ 981 BCM1_Schlusslicht_Signatur 0;
BA_ "GenSigSwitchedByIgnition" SG_ 981 BCM1_Schlusslicht_Signatur 0;
BA_ "GenSigSendType" SG_ 981 BCM1_Signaturlicht_Anf 0;
BA_ "GenSigSwitchedByIgnition" SG_ 981 BCM1_Signaturlicht_Anf 0;
BA_ "GenSigSendType" SG_ 981 BCM1_Standlicht_Anf 0;
BA_ "GenSigSwitchedByIgnition" SG_ 981 BCM1_Standlicht_Anf 0;
BA_ "GenSigSendType" SG_ 981 BCM1_Tagfahrlicht_Anf 0;
BA_ "GenSigSwitchedByIgnition" SG_ 981 BCM1_Tagfahrlicht_Anf 0;
BA_ "GenSigSendType" SG_ 981 BCM1_Touristen_Licht_Anf 0;
BA_ "GenSigSwitchedByIgnition" SG_ 981 BCM1_Touristen_Licht_Anf 0;
BA_ "GenSigSendType" SG_ 981 BCM1_Umfeldleuchten_Anf 0;
BA_ "GenSigSwitchedByIgnition" SG_ 981 BCM1_Umfeldleuchten_Anf 0;
BA_ "GenSigSendType" SG_ 981 BCM_Rueckfahrlicht_Anf 0;
BA_ "GenSigSwitchedByIgnition" SG_ 981 BCM_Rueckfahrlicht_Anf 0;
BA_ "GenSigSendType" SG_ 981 Licht_Anf_01_BZ 0;
BA_ "GenSigFuncType" SG_ 981 Licht_Anf_01_BZ 1;
BA_ "GenSigSwitchedByIgnition" SG_ 981 Licht_Anf_01_BZ 0;
BA_ "GenSigSendType" SG_ 981 Licht_Anf_01_CRC 0;
BA_ "GenSigFuncType" SG_ 981 Licht_Anf_01_CRC 2;
BA_ "GenSigSwitchedByIgnition" SG_ 981 Licht_Anf_01_CRC 0;
BA_ "GenSigSendType" SG_ 1624 BCM1_Licht_Dunkelheit_aktiv 3;
BA_ "GenSigSwitchedByIgnition" SG_ 1624 BCM1_Licht_Dunkelheit_aktiv 0;
BA_ "GenSigSendType" SG_ 1624 BCM1_Linksverkehr 0;
BA_ "GenSigSwitchedByIgnition" SG_ 1624 BCM1_Linksverkehr 0;
BA_ "GenSigSendType" SG_ 1624 Licht_Vorne_01_BZ 0;
BA_ "GenSigFuncType" SG_ 1624 Licht_Vorne_01_BZ 1;
BA_ "GenSigSendType" SG_ 1624 Licht_Vorne_01_CRC 0;
BA_ "GenSigFuncType" SG_ 1624 Licht_Vorne_01_CRC 2;
BA_ "GenSigSendType" SG_ 1624 LV_Abbiegelicht_li_def 0;
BA_ "GenSigSwitchedByIgnition" SG_ 1624 LV_Abbiegelicht_li_def 0;
BA_ "GenSigSendType" SG_ 1624 LV_Abbiegelicht_re_def 0;
BA_ "GenSigSwitchedByIgnition" SG_ 1624 LV_Abbiegelicht_re_def 0;
BA_ "GenSigSendType" SG_ 1624 LV_Abblend_Fernlicht_li_def 0;
BA_ "GenSigSwitchedByIgnition" SG_ 1624 LV_Abblend_Fernlicht_li_def 0;
BA_ "GenSigSendType" SG_ 1624 LV_Abblend_Fernlicht_re_def 0;
BA_ "GenSigSwitchedByIgnition" SG_ 1624 LV_Abblend_Fernlicht_re_def 0;
BA_ "GenSigSendType" SG_ 1624 LV_Abblendlicht_Anzeige 3;
BA_ "GenSigSwitchedByIgnition" SG_ 1624 LV_Abblendlicht_Anzeige 0;
BA_ "GenSigSendType" SG_ 1624 LV_Abblendlicht_li_def 0;
BA_ "GenSigSwitchedByIgnition" SG_ 1624 LV_Abblendlicht_li_def 0;
BA_ "GenSigSendType" SG_ 1624 LV_Abblendlicht_re_def 0;
BA_ "GenSigSwitchedByIgnition" SG_ 1624 LV_Abblendlicht_re_def 0;
BA_ "GenSigSendType" SG_ 1624 LV_Abblendlicht_TFL_li_def 0;
BA_ "GenSigSwitchedByIgnition" SG_ 1624 LV_Abblendlicht_TFL_li_def 0;
BA_ "GenSigSendType" SG_ 1624 LV_Abblendlicht_TFL_re_def 0;
BA_ "GenSigSwitchedByIgnition" SG_ 1624 LV_Abblendlicht_TFL_re_def 0;
BA_ "GenSigSendType" SG_ 1624 LV_AFL_aktiv_Anzeige 3;
BA_ "GenSigSwitchedByIgnition" SG_ 1624 LV_AFL_aktiv_Anzeige 0;
BA_ "GenSigSendType" SG_ 1624 LV_AFL_defekt 3;
BA_ "GenSigSwitchedByIgnition" SG_ 1624 LV_AFL_defekt 0;
BA_ "GenSigSendType" SG_ 1624 LV_Aussenlicht_def 3;
BA_ "GenSigSwitchedByIgnition" SG_ 1624 LV_Aussenlicht_def 0;
BA_ "GenSigSendType" SG_ 1624 LV_Blinker_li_def 3;
BA_ "GenSigSwitchedByIgnition" SG_ 1624 LV_Blinker_li_def 0;
BA_ "GenSigSendType" SG_ 1624 LV_Blinker_re_def 3;
BA_ "GenSigSwitchedByIgnition" SG_ 1624 LV_Blinker_re_def 0;
BA_ "GenSigSendType" SG_ 1624 LV_Blinker_VL_aktiv 3;
BA_ "GenSigSwitchedByIgnition" SG_ 1624 LV_Blinker_VL_aktiv 0;
BA_ "GenSigSendType" SG_ 1624 LV_Blinker_VR_aktiv 3;
BA_ "GenSigSwitchedByIgnition" SG_ 1624 LV_Blinker_VR_aktiv 0;
BA_ "GenSigSendType" SG_ 1624 LV_Blk_li_Seite_def 0;
BA_ "GenSigSwitchedByIgnition" SG_ 1624 LV_Blk_li_Seite_def 0;
BA_ "GenSigSendType" SG_ 1624 LV_Blk_re_Seite_def 0;
BA_ "GenSigSwitchedByIgnition" SG_ 1624 LV_Blk_re_Seite_def 0;
BA_ "GenSigSendType" SG_ 1624 LV_Fernlicht_Anzeige 3;
BA_ "GenSigSwitchedByIgnition" SG_ 1624 LV_Fernlicht_Anzeige 0;
BA_ "GenSigSendType" SG_ 1624 LV_Fernlicht_li_def 0;
BA_ "GenSigSwitchedByIgnition" SG_ 1624 LV_Fernlicht_li_def 0;
BA_ "GenSigSendType" SG_ 1624 LV_Fernlicht_re_def 0;
BA_ "GenSigSwitchedByIgnition" SG_ 1624 LV_Fernlicht_re_def 0;
BA_ "GenSigSendType" SG_ 1624 LV_FLA_aktiv_Anzeige 3;
BA_ "GenSigSwitchedByIgnition" SG_ 1624 LV_FLA_aktiv_Anzeige 0;
BA_ "GenSigSendType" SG_ 1624 LV_FLA_defekt 0;
BA_ "GenSigSwitchedByIgnition" SG_ 1624 LV_FLA_defekt 0;
BA_ "GenSigSendType" SG_ 1624 LV_FLA_Sensor_blockiert 0;
BA_ "GenSigSwitchedByIgnition" SG_ 1624 LV_FLA_Sensor_blockiert 0;
BA_ "GenSigSendType" SG_ 1624 LV_LED_Scheinwerfer_li_def 0;
BA_ "GenSigSwitchedByIgnition" SG_ 1624 LV_LED_Scheinwerfer_li_def 0;
BA_ "GenSigSendType" SG_ 1624 LV_LED_Scheinwerfer_re_def 0;
BA_ "GenSigSwitchedByIgnition" SG_ 1624 LV_LED_Scheinwerfer_re_def 0;
BA_ "GenSigSendType" SG_ 1624 LV_MXB_Status_Anzeige 3;
BA_ "GenSigSwitchedByIgnition" SG_ 1624 LV_MXB_Status_Anzeige 0;
BA_ "GenSigSendType" SG_ 1624 LV_Nebellicht_Anzeige 3;
BA_ "GenSigSwitchedByIgnition" SG_ 1624 LV_Nebellicht_Anzeige 0;
BA_ "GenSigSendType" SG_ 1624 LV_Nebellicht_li_def 0;
BA_ "GenSigSwitchedByIgnition" SG_ 1624 LV_Nebellicht_li_def 0;
BA_ "GenSigSendType" SG_ 1624 LV_Nebellicht_re_def 0;
BA_ "GenSigSwitchedByIgnition" SG_ 1624 LV_Nebellicht_re_def 0;
BA_ "GenSigSendType" SG_ 1624 LV_Nebellicht_TFL_li_def 0;
BA_ "GenSigSwitchedByIgnition" SG_ 1624 LV_Nebellicht_TFL_li_def 0;
BA_ "GenSigSendType" SG_ 1624 LV_Nebellicht_TFL_re_def 0;
BA_ "GenSigSwitchedByIgnition" SG_ 1624 LV_Nebellicht_TFL_re_def 0;
BA_ "GenSigSendType" SG_ 1624 LV_Nebelschlusslicht_Anzeige 3;
BA_ "GenSigSwitchedByIgnition" SG_ 1624 LV_Nebelschlusslicht_Anzeige 0;
BA_ "GenSigSendType" SG_ 1624 LV_Standlicht_Anzeige 3;
BA_ "GenSigSwitchedByIgnition" SG_ 1624 LV_Standlicht_Anzeige 0;
BA_ "GenSigSendType" SG_ 1624 LV_Standlicht_li_def 0;
BA_ "GenSigSwitchedByIgnition" SG_ 1624 LV_Standlicht_li_def 0;
BA_ "GenSigSendType" SG_ 1624 LV_Standlicht_re_def 0;
BA_ "GenSigSwitchedByIgnition" SG_ 1624 LV_Standlicht_re_def 0;
BA_ "GenSigSendType" SG_ 1624 LV_Standlicht_TFL_li_def 0;
BA_ "GenSigSwitchedByIgnition" SG_ 1624 LV_Standlicht_TFL_li_def 0;
BA_ "GenSigSendType" SG_ 1624 LV_Standlicht_TFL_re_def 0;
BA_ "GenSigSwitchedByIgnition" SG_ 1624 LV_Standlicht_TFL_re_def 0;
BA_ "GenSigSendType" SG_ 1624 LV_Tagfahrlicht_Anzeige 3;
BA_ "GenSigSwitchedByIgnition" SG_ 1624 LV_Tagfahrlicht_Anzeige 0;
BA_ "GenSigSendType" SG_ 1624 LV_Tagfahrlicht_li_def 0;
BA_ "GenSigSwitchedByIgnition" SG_ 1624 LV_Tagfahrlicht_li_def 0;
BA_ "GenSigSendType" SG_ 1624 LV_Tagfahrlicht_re_def 0;
BA_ "GenSigSwitchedByIgnition" SG_ 1624 LV_Tagfahrlicht_re_def 0;
BA_ "GenSigSendType" SG_ 134 LWI_01_BZ 0;
BA_ "GenSigFuncType" SG_ 134 LWI_01_BZ 1;
BA_ "GenSigSendType" SG_ 134 LWI_01_CRC 0;
BA_ "GenSigFuncType" SG_ 134 LWI_01_CRC 2;
BA_ "GenSigSwitchedByIgnition" SG_ 134 LWI_01_CRC 0;
BA_ "GenSigSendType" SG_ 134 LWI_Lenkradw_Geschw 0;
BA_ "GenSigStartValue" SG_ 134 LWI_Lenkradw_Geschw 510;
BA_ "Fehlerwert" SG_ 134 LWI_Lenkradw_Geschw 511;
BA_ "GenSigSendType" SG_ 134 LWI_Lenkradwinkel 0;
BA_ "GenSigStartValue" SG_ 134 LWI_Lenkradwinkel 8190;
BA_ "Fehlerwert" SG_ 134 LWI_Lenkradwinkel 8191;
BA_ "GenSigSendType" SG_ 134 LWI_MFL_Abschaltung 0;
BA_ "GenSigSwitchedByIgnition" SG_ 134 LWI_MFL_Abschaltung 0;
BA_ "GenSigSendType" SG_ 134 LWI_QBit_Lenkradwinkel 0;
BA_ "GenSigStartValue" SG_ 134 LWI_QBit_Lenkradwinkel 1;
BA_ "GenSigSendType" SG_ 134 LWI_QBit_Sub_Daten 0;
BA_ "GenSigSendType" SG_ 134 LWI_Sensorstatus 0;
BA_ "GenSigSendType" SG_ 134 LWI_Sub_Daten 0;
BA_ "GenSigSendType" SG_ 134 LWI_VZ_Lenkradw_Geschw 0;
BA_ "GenSigSendType" SG_ 134 LWI_VZ_Lenkradwinkel 0;
BA_ "GenSigSendType" SG_ 168 MO_Drehzahl_01 0;
BA_ "GenSigSwitchedByIgnition" SG_ 168 MO_Drehzahl_01 0;
BA_ "GenSigSendType" SG_ 168 MO_Mom_Begr_dyn 0;
BA_ "GenSigStartValue" SG_ 168 MO_Mom_Begr_dyn 1022;
BA_ "GenSigSwitchedByIgnition" SG_ 168 MO_Mom_Begr_dyn 0;
BA_ "GenSigSendType" SG_ 168 MO_Mom_Begr_stat 0;
BA_ "GenSigStartValue" SG_ 168 MO_Mom_Begr_stat 510;
BA_ "GenSigSwitchedByIgnition" SG_ 168 MO_Mom_Begr_stat 0;
BA_ "GenSigSendType" SG_ 168 MO_Mom_neg_verfuegbar 0;
BA_ "GenSigStartValue" SG_ 168 MO_Mom_neg_verfuegbar 510;
BA_ "GenSigSwitchedByIgnition" SG_ 168 MO_Mom_neg_verfuegbar 0;
BA_ "Fehlerwert" SG_ 168 MO_Mom_neg_verfuegbar 511;
BA_ "GenSigSendType" SG_ 168 MO_Momentenintegral_02 0;
BA_ "GenSigSwitchedByIgnition" SG_ 168 MO_Momentenintegral_02 0;
BA_ "GenSigSendType" SG_ 168 MO_QBit_Drehzahl_01 0;
BA_ "GenSigStartValue" SG_ 168 MO_QBit_Drehzahl_01 1;
BA_ "GenSigSwitchedByIgnition" SG_ 168 MO_QBit_Drehzahl_01 0;
BA_ "GenSigSendType" SG_ 168 Motor_12_BZ 0;
BA_ "GenSigFuncType" SG_ 168 Motor_12_BZ 1;
BA_ "GenSigSwitchedByIgnition" SG_ 168 Motor_12_BZ 0;
BA_ "GenSigSendType" SG_ 168 Motor_12_CRC 0;
BA_ "GenSigFuncType" SG_ 168 Motor_12_CRC 2;
BA_ "GenSigSwitchedByIgnition" SG_ 168 Motor_12_CRC 0;
BA_ "GenSigSendType" SG_ 958 MO_Aussp_Anlass 3;
BA_ "GenSigSwitchedByIgnition" SG_ 958 MO_Aussp_Anlass 0;
BA_ "GenSigSendType" SG_ 958 MO_BKV_Unterdruckwarnung 0;
BA_ "GenSigSwitchedByIgnition" SG_ 958 MO_BKV_Unterdruckwarnung 0;
BA_ "GenSigSendType" SG_ 958 MO_BLS 3;
BA_ "GenSigSwitchedByIgnition" SG_ 958 MO_BLS 0;
BA_ "GenSigSendType" SG_ 958 MO_BMS_NV_Anf_stuetzen 3;
BA_ "GenSigSwitchedByIgnition" SG_ 958 MO_BMS_NV_Anf_stuetzen 0;
BA_ "GenSigSendType" SG_ 958 MO_EKlKomLeiRed 0;
BA_ "GenSigSwitchedByIgnition" SG_ 958 MO_EKlKomLeiRed 0;
BA_ "GenSigSendType" SG_ 958 MO_Ext_E_Fahrt_aktiv 3;
BA_ "NWM-WakeupAllowed" SG_ 958 MO_Ext_E_Fahrt_aktiv 1;
BA_ "GenSigSwitchedByIgnition" SG_ 958 MO_Ext_E_Fahrt_aktiv 0;
BA_ "GenSigSendType" SG_ 958 MO_Fahrer_bremst 3;
BA_ "GenSigSwitchedByIgnition" SG_ 958 MO_Fahrer_bremst 0;
BA_ "GenSigSendType" SG_ 958 MO_FMAus_aktiv 3;
BA_ "GenSigSwitchedByIgnition" SG_ 958 MO_FMAus_aktiv 0;
BA_ "GenSigSendType" SG_ 958 MO_FMAus_Startvariante 3;
BA_ "GenSigSwitchedByIgnition" SG_ 958 MO_FMAus_Startvariante 0;
BA_ "GenSigSendType" SG_ 958 MO_Freig_Anlass 3;
BA_ "GenSigSwitchedByIgnition" SG_ 958 MO_Freig_Anlass 0;
BA_ "GenSigSendType" SG_ 958 MO_Freig_Reku 0;
BA_ "GenSigSwitchedByIgnition" SG_ 958 MO_Freig_Reku 0;
BA_ "GenSigSendType" SG_ 958 MO_Freigabe_Segeln 0;
BA_ "GenSigSwitchedByIgnition" SG_ 958 MO_Freigabe_Segeln 0;
BA_ "GenSigSendType" SG_ 958 MO_Gangposition 3;
BA_ "GenSigStartValue" SG_ 958 MO_Gangposition 14;
BA_ "GenSigSwitchedByIgnition" SG_ 958 MO_Gangposition 0;
BA_ "Fehlerwert" SG_ 958 MO_Gangposition 15;
BA_ "GenSigSendType" SG_ 958 MO_Handshake_STH 0;
BA_ "GenSigSwitchedByIgnition" SG_ 958 MO_Handshake_STH 0;
BA_ "GenSigSendType" SG_ 958 MO_HYB_Fahrbereitschaft 0;
BA_ "GenSigSwitchedByIgnition" SG_ 958 MO_HYB_Fahrbereitschaft 0;
BA_ "GenSigSendType" SG_ 958 MO_HYB_VM_aktiv 3;
BA_ "GenSigSwitchedByIgnition" SG_ 958 MO_HYB_VM_aktiv 0;
BA_ "GenSigSendType" SG_ 958 MO_Interlock 3;
BA_ "GenSigSwitchedByIgnition" SG_ 958 MO_Interlock 0;
BA_ "GenSigSendType" SG_ 958 MO_Kickdown 3;
BA_ "GenSigSwitchedByIgnition" SG_ 958 MO_Kickdown 0;
BA_ "GenSigSendType" SG_ 958 MO_Kl_50 3;
BA_ "GenSigSwitchedByIgnition" SG_ 958 MO_Kl_50 0;
BA_ "GenSigSendType" SG_ 958 MO_Kl_75 3;
BA_ "GenSigSwitchedByIgnition" SG_ 958 MO_Kl_75 0;
BA_ "GenSigSendType" SG_ 958 MO_Klima_Eingr 0;
BA_ "GenSigSwitchedByIgnition" SG_ 958 MO_Klima_Eingr 0;
BA_ "GenSigSendType" SG_ 958 MO_KomFehler_ESP 3;
BA_ "GenSigSwitchedByIgnition" SG_ 958 MO_KomFehler_ESP 0;
BA_ "Fehlerwert" SG_ 958 MO_KomFehler_ESP 1;
BA_ "GenSigSendType" SG_ 958 MO_Konsistenz_Bremsped 3;
BA_ "GenSigSwitchedByIgnition" SG_ 958 MO_Konsistenz_Bremsped 0;
BA_ "GenSigSendType" SG_ 958 MO_Kuppl_schalter 3;
BA_ "GenSigSwitchedByIgnition" SG_ 958 MO_Kuppl_schalter 0;
BA_ "GenSigSendType" SG_ 958 MO_Motor_laeuft 3;
BA_ "GenSigSwitchedByIgnition" SG_ 958 MO_Motor_laeuft 0;
BA_ "GenSigSendType" SG_ 958 MO_PTC_Status 0;
BA_ "GenSigSwitchedByIgnition" SG_ 958 MO_PTC_Status 0;
BA_ "GenSigSendType" SG_ 958 MO_QBit_Fahrer_bremst 3;
BA_ "GenSigStartValue" SG_ 958 MO_QBit_Fahrer_bremst 1;
BA_ "GenSigSwitchedByIgnition" SG_ 958 MO_QBit_Fahrer_bremst 0;
BA_ "GenSigSendType" SG_ 958 MO_QBit_Gangposition 3;
BA_ "GenSigStartValue" SG_ 958 MO_QBit_Gangposition 1;
BA_ "GenSigSwitchedByIgnition" SG_ 958 MO_QBit_Gangposition 0;
BA_ "GenSigSendType" SG_ 958 MO_QBit_KL_75 3;
BA_ "GenSigStartValue" SG_ 958 MO_QBit_KL_75 1;
BA_ "GenSigSwitchedByIgnition" SG_ 958 MO_QBit_KL_75 0;
BA_ "GenSigSendType" SG_ 958 MO_Remotestart_Betrieb 3;
BA_ "GenSigSwitchedByIgnition" SG_ 958 MO_Remotestart_Betrieb 0;
BA_ "GenSigSendType" SG_ 958 MO_Remotestart_moeglich 0;
BA_ "GenSigSwitchedByIgnition" SG_ 958 MO_Remotestart_moeglich 0;
BA_ "GenSigSendType" SG_ 958 MO_Signalquelle_Gangposition 0;
BA_ "GenSigSwitchedByIgnition" SG_ 958 MO_Signalquelle_Gangposition 0;
BA_ "GenSigSendType" SG_ 958 MO_StartStopp_Fahrerwunsch 0;
BA_ "GenSigSwitchedByIgnition" SG_ 958 MO_StartStopp_Fahrerwunsch 0;
BA_ "GenSigSendType" SG_ 958 MO_StartStopp_Motorstopp 3;
BA_ "GenSigSwitchedByIgnition" SG_ 958 MO_StartStopp_Motorstopp 0;
BA_ "GenSigSendType" SG_ 958 MO_StartStopp_Status 3;
BA_ "GenSigSwitchedByIgnition" SG_ 958 MO_StartStopp_Status 0;
BA_ "GenSigSendType" SG_ 958 MO_StartStopp_Wiederstart 3;
BA_ "GenSigSwitchedByIgnition" SG_ 958 MO_StartStopp_Wiederstart 0;
BA_ "GenSigSendType" SG_ 958 MO_StartVorauss_erfuellt 3;
BA_ "GenSigStartValue" SG_ 958 MO_StartVorauss_erfuellt 1;
BA_ "GenSigSwitchedByIgnition" SG_ 958 MO_StartVorauss_erfuellt 0;
BA_ "GenSigSendType" SG_ 958 MO_Text_Geschw_red 0;
BA_ "GenSigSwitchedByIgnition" SG_ 958 MO_Text_Geschw_red 0;
BA_ "GenSigSendType" SG_ 958 MO_Zylinderabschaltung 3;
BA_ "GenSigSwitchedByIgnition" SG_ 958 MO_Zylinderabschaltung 0;
BA_ "GenSigSendType" SG_ 958 Motor_14_BZ 0;
BA_ "GenSigFuncType" SG_ 958 Motor_14_BZ 1;
BA_ "GenSigSwitchedByIgnition" SG_ 958 Motor_14_BZ 0;
BA_ "GenSigSendType" SG_ 958 Motor_14_CRC 0;
BA_ "GenSigFuncType" SG_ 958 Motor_14_CRC 2;
BA_ "GenSigSwitchedByIgnition" SG_ 958 Motor_14_CRC 0;
BA_ "GenSigSendType" SG_ 1648 MO1_Freigabe_Info_WFS 3;
BA_ "GenSigSwitchedByIgnition" SG_ 1648 MO1_Freigabe_Info_WFS 0;
BA_ "GenSigSendType" SG_ 1648 MO1_Freigabe_Verfallsinfo_WFS 3;
BA_ "GenSigSwitchedByIgnition" SG_ 1648 MO1_Freigabe_Verfallsinfo_WFS 0;
BA_ "GenSigSendType" SG_ 1648 MO1_Sperr_Info_WFS 3;
BA_ "GenSigSwitchedByIgnition" SG_ 1648 MO1_Sperr_Info_WFS 0;
BA_ "GenSigSendType" SG_ 1648 MO_Abstellzeit 0;
BA_ "GenSigStartValue" SG_ 1648 MO_Abstellzeit 254;
BA_ "GenSigSwitchedByIgnition" SG_ 1648 MO_Abstellzeit 0;
BA_ "GenSigSendType" SG_ 1648 MO_Abstellzeit_Status 0;
BA_ "GenSigSwitchedByIgnition" SG_ 1648 MO_Abstellzeit_Status 0;
BA_ "GenSigSendType" SG_ 1648 MO_ANC_Kennfeld_Anf 3;
BA_ "GenSigSwitchedByIgnition" SG_ 1648 MO_ANC_Kennfeld_Anf 0;
BA_ "GenSigSendType" SG_ 1648 MO_Anzahl_Abgesch_Zyl 3;
BA_ "GenSigSwitchedByIgnition" SG_ 1648 MO_Anzahl_Abgesch_Zyl 0;
BA_ "GenSigSendType" SG_ 1648 MO_Bremslicht_Reku 3;
BA_ "GenSigSwitchedByIgnition" SG_ 1648 MO_Bremslicht_Reku 0;
BA_ "GenSigSendType" SG_ 1648 MO_Drehzahl_Warnung 0;
BA_ "GenSigSwitchedByIgnition" SG_ 1648 MO_Drehzahl_Warnung 0;
BA_ "GenSigSendType" SG_ 1648 MO_EPCL 0;
BA_ "GenSigSwitchedByIgnition" SG_ 1648 MO_EPCL 0;
BA_ "GenSigSendType" SG_ 1648 MO_Ethanol_BS_Texte 0;
BA_ "GenSigSwitchedByIgnition" SG_ 1648 MO_Ethanol_BS_Texte 0;
BA_ "GenSigSendType" SG_ 1648 MO_Fahrzeugtyp 0;
BA_ "GenSigFuncType" SG_ 1648 MO_Fahrzeugtyp 8;
BA_ "GenSigSwitchedByIgnition" SG_ 1648 MO_Fahrzeugtyp 0;
BA_ "GenSigSendType" SG_ 1648 MO_Fehler_Zylabsch 0;
BA_ "GenSigSwitchedByIgnition" SG_ 1648 MO_Fehler_Zylabsch 0;
BA_ "GenSigSendType" SG_ 1648 MO_Hybrid_StartStopp_LED 3;
BA_ "GenSigSwitchedByIgnition" SG_ 1648 MO_Hybrid_StartStopp_LED 0;
BA_ "GenSigSendType" SG_ 1648 MO_max_Ladedruck 0;
BA_ "GenSigFuncType" SG_ 1648 MO_max_Ladedruck 8;
BA_ "GenSigSwitchedByIgnition" SG_ 1648 MO_max_Ladedruck 0;
BA_ "GenSigSendType" SG_ 1648 MO_NMAX_Schaltanzeige 3;
BA_ "GenSigSwitchedByIgnition" SG_ 1648 MO_NMAX_Schaltanzeige 0;
BA_ "GenSigSendType" SG_ 1648 MO_obere_Drehzahlgrenze 0;
BA_ "GenSigSwitchedByIgnition" SG_ 1648 MO_obere_Drehzahlgrenze 0;
BA_ "GenSigSendType" SG_ 1648 MO_StartStopp_PopUp 3;
BA_ "GenSigSwitchedByIgnition" SG_ 1648 MO_StartStopp_PopUp 0;
BA_ "GenSigSendType" SG_ 1648 MO_Zylabsch_Texte 0;
BA_ "GenSigSwitchedByIgnition" SG_ 1648 MO_Zylabsch_Texte 0;
BA_ "GenSigSendType" SG_ 1648 MO_Zylabsch_Texte_02 3;
BA_ "GenSigSwitchedByIgnition" SG_ 1648 MO_Zylabsch_Texte_02 0;
BA_REL_ "GenSigTimeoutTime" BU_SG_REL_ conBox SG_ 310 HAL_VZ_Radwinkel 500;
BA_REL_ "GenSigTimeoutTime" BU_SG_REL_ conBox SG_ 310 HAL_Radwinkel 500;
BA_REL_ "GenSigTimeoutTime" BU_SG_REL_ conBox SG_ 960 ZAS_Kl_S 1000;
BA_REL_ "GenSigTimeoutTime" BU_SG_REL_ conBox SG_ 960 ZAS_Kl_15 1000;
BA_REL_ "GenSigTimeoutTime" BU_SG_REL_ conBox SG_ 779 KBI_angez_Geschw 2000;
BA_REL_ "GenSigTimeoutTime" BU_SG_REL_ conBox SG_ 779 KBI_Einheit_Tacho 2000;
BA_REL_ "GenSigTimeoutTime" BU_SG_REL_ conBox SG_ 1719 KBI_Inhalt_Tank 5000;
BA_REL_ "GenSigTimeoutTime" BU_SG_REL_ conBox SG_ 1719 KBI_FStatus_Tank 5000;
BA_REL_ "GenSigTimeoutTime" BU_SG_REL_ conBox SG_ 1720 KBI_Tankfuellstand_Prozent 5000;
BA_REL_ "GenSigTimeoutTime" BU_SG_REL_ conBox SG_ 2527679653 MXB_LAPP_Freigabe 5000;
BA_REL_ "GenSigTimeoutTime" BU_SG_REL_ conBox SG_ 2527679653 MXB_LAPP_Status_FL 5000;
BA_REL_ "GenSigTimeoutTime" BU_SG_REL_ conBox SG_ 2527679653 MXB_LAPP_Statuscode 5000;
BA_REL_ "GenSigTimeoutTime" BU_SG_REL_ conBox SG_ 810 EPS_Lenkerposition 5000;
BA_REL_ "GenSigTimeoutTime" BU_SG_REL_ conBox SG_ 159 EPS_Berechneter_LW 500;
BA_REL_ "GenSigTimeoutTime" BU_SG_REL_ conBox SG_ 159 EPS_VZ_BLW 500;
BA_REL_ "GenSigTimeoutTime" BU_SG_REL_ conBox SG_ 2331595840 LHW_eventABSactivated 1000;
BA_REL_ "GenSigTimeoutTime" BU_SG_REL_ conBox SG_ 2331595840 LHW_eventAirBagDeployment 1000;
BA_REL_ "GenSigTimeoutTime" BU_SG_REL_ conBox SG_ 2331595840 LHW_eventDisabledVehicle 1000;
BA_REL_ "GenSigTimeoutTime" BU_SG_REL_ conBox SG_ 2331595840 LHW_eventFlatTire 1000;
BA_REL_ "GenSigTimeoutTime" BU_SG_REL_ conBox SG_ 2331595840 LHW_eventHardBraking 1000;
BA_REL_ "GenSigTimeoutTime" BU_SG_REL_ conBox SG_ 2331595840 LHW_eventHazardLights 1000;
BA_REL_ "GenSigTimeoutTime" BU_SG_REL_ conBox SG_ 2331595840 LHW_eventStabilityControlActive 1000;
BA_REL_ "GenSigTimeoutTime" BU_SG_REL_ conBox SG_ 2331595840 LHW_eventTractionControlLoss 1000;
BA_REL_ "GenSigTimeoutTime" BU_SG_REL_ conBox SG_ 981 BCM1_Standlicht_Anf 1000;
BA_REL_ "GenSigTimeoutTime" BU_SG_REL_ conBox SG_ 981 BCM1_Abblendlicht_Anf 1000;
BA_REL_ "GenSigTimeoutTime" BU_SG_REL_ conBox SG_ 981 BCM1_Nebellicht_Anf 1000;
BA_REL_ "GenSigTimeoutTime" BU_SG_REL_ conBox SG_ 981 BCM1_Parklicht_li_Anf 1000;
BA_REL_ "GenSigTimeoutTime" BU_SG_REL_ conBox SG_ 981 BCM1_Parklicht_re_Anf 1000;
BA_REL_ "GenSigTimeoutTime" BU_SG_REL_ conBox SG_ 981 BCM1_Nebelschluss_Ahg_Anf 1000;
BA_REL_ "GenSigTimeoutTime" BU_SG_REL_ conBox SG_ 981 BCM_Rueckfahrlicht_Anf 1000;
BA_REL_ "GenSigTimeoutTime" BU_SG_REL_ conBox SG_ 981 BCM1_Tagfahrlicht_Anf 1000;
BA_REL_ "GenSigTimeoutTime" BU_SG_REL_ conBox SG_ 1624 LV_Fernlicht_Anzeige 5000;
BA_REL_ "GenSigTimeoutTime" BU_SG_REL_ conBox SG_ 1624 LV_AFL_aktiv_Anzeige 5000;
BA_REL_ "GenSigTimeoutTime" BU_SG_REL_ conBox SG_ 134 LWI_Lenkradwinkel 500;
BA_REL_ "GenSigTimeoutTime" BU_SG_REL_ conBox SG_ 134 LWI_VZ_Lenkradwinkel 500;
BA_REL_ "GenSigTimeoutTime" BU_SG_REL_ conBox SG_ 168 MO_Drehzahl_01 500;
BA_REL_ "GenSigTimeoutTime" BU_SG_REL_ conBox SG_ 958 MO_Kl_75 1000;
BA_REL_ "GenSigTimeoutTime" BU_SG_REL_ conBox SG_ 958 MO_Kl_50 1000;
BA_REL_ "GenSigTimeoutTime" BU_SG_REL_ conBox SG_ 958 MO_Gangposition 1000;
BA_REL_ "GenSigTimeoutTime" BU_SG_REL_ conBox SG_ 958 MO_Motor_laeuft 1000;
BA_REL_ "GenSigTimeoutTime" BU_SG_REL_ conBox SG_ 1648 MO_Fahrzeugtyp 5000;
BA_REL_ "GenSigTimeoutTime" BU_SG_REL_ Gateway SG_ 2463978723 GNSS_DR_Nachrichtenpaket_ID2 1000;
BA_REL_ "GenSigTimeoutTime" BU_SG_REL_ Gateway SG_ 2463978723 GNSS_DR_Ortung_Ausrichtung 1000;
BA_REL_ "GenSigTimeoutTime" BU_SG_REL_ Gateway SG_ 2463978723 GNSS_DR_Ortung_2D_Geschw_u_Grund 1000;
BA_REL_ "GenSigTimeoutTime" BU_SG_REL_ Gateway SG_ 2463978724 GNSS_DR_Nachrichtenpaket_ID3 1000;
BA_REL_ "GenSigTimeoutTime" BU_SG_REL_ Gateway SG_ 2463978724 GNSS_DR_Ortung_Guete_Geschwindig 1000;
BA_REL_ "GenSigTimeoutTime" BU_SG_REL_ Gateway SG_ 2463978724 GNSS_DR_Ortung_Guete_Ausrichtung 1000;
BA_REL_ "GenSigTimeoutTime" BU_SG_REL_ Gateway SG_ 2463978724 GNSS_DR_Ortung_Guete_horizontal 1000;
BA_REL_ "GenSigTimeoutTime" BU_SG_REL_ Gateway SG_ 2463978724 GNSS_DR_Ortung_Guete_vertikal 1000;
BA_REL_ "GenSigTimeoutTime" BU_SG_REL_ Gateway SG_ 2463978725 GNSS_DR_Nachrichtenpaket_ID4 1000;
BA_REL_ "GenSigTimeoutTime" BU_SG_REL_ Gateway SG_ 2463978725 GNSS_DR_Ortung_Zeit_in_GPSWoche 1000;
BA_REL_ "GenSigTimeoutTime" BU_SG_REL_ Gateway SG_ 2463978725 GNSS_DR_Ortung_Hoehe 1000;
BA_REL_ "GenSigTimeoutTime" BU_SG_REL_ Gateway SG_ 2463978725 GNSS_DR_Odometer 1000;
BA_REL_ "GenSigTimeoutTime" BU_SG_REL_ Gateway SG_ 2463978725 GNSS_DR_Pitch 1000;
BA_REL_ "GenSigTimeoutTime" BU_SG_REL_ Gateway SG_ 2463978726 GNSS_DR_UTC_Zeit 1000;
BA_REL_ "GenSigTimeoutTime" BU_SG_REL_ Gateway SG_ 2463978726 GNSS_DR_Nachrichtenpaket_ID5 1000;
BA_REL_ "GenSigTimeoutTime" BU_SG_REL_ Gateway SG_ 2549088496 Sekundaer_F0_Nachlauftyp 5000;
BA_REL_ "GenSigTimeoutTime" BU_SG_REL_ Gateway SG_ 2549088496 Sekundaer_F0_SNI 5000;
BA_REL_ "GenSigTimeoutTime" BU_SG_REL_ Gateway SG_ 2549088496 KN_Sekundaer_F0_ECUKnockOutTimer 5000;
BA_REL_ "GenSigTimeoutTime" BU_SG_REL_ Gateway SG_ 2549088496 KN_Sekundaer_F0_BusKnockOut 5000;
BA_REL_ "GenSigTimeoutTime" BU_SG_REL_ Gateway SG_ 2549088496 KN_Sekundaer_F0_BusKnockOutTimer 5000;
BA_REL_ "GenSigTimeoutTime" BU_SG_REL_ Gateway SG_ 2549088496 NM_Sekundaer_F0_Wakeup 5000;
BA_REL_ "GenSigTimeoutTime" BU_SG_REL_ Gateway SG_ 2549088496 KN_Sekundaer_F0_ECUKnockOut 5000;
BA_REL_ "GenSigTimeoutTime" BU_SG_REL_ Gateway SG_ 2549088496 NM_Sekundaer_F0_Lokalaktiv 5000;
BA_REL_ "GenSigTimeoutTime" BU_SG_REL_ Gateway SG_ 2549088496 Sekundaer_F0_KD_Fehler 2500;
BA_REL_ "GenSigTimeoutTime" BU_SG_REL_ Gateway_PAG SG_ 2463978723 GNSS_DR_Nachrichtenpaket_ID2 1000;
BA_REL_ "GenSigTimeoutTime" BU_SG_REL_ Gateway_PAG SG_ 2463978723 GNSS_DR_Ortung_Ausrichtung 1000;
BA_REL_ "GenSigTimeoutTime" BU_SG_REL_ Gateway_PAG SG_ 2463978723 GNSS_DR_Ortung_2D_Geschw_u_Grund 1000;
BA_REL_ "GenSigTimeoutTime" BU_SG_REL_ Gateway_PAG SG_ 2463978724 GNSS_DR_Nachrichtenpaket_ID3 1000;
BA_REL_ "GenSigTimeoutTime" BU_SG_REL_ Gateway_PAG SG_ 2463978724 GNSS_DR_Ortung_Guete_Geschwindig 1000;
BA_REL_ "GenSigTimeoutTime" BU_SG_REL_ Gateway_PAG SG_ 2463978724 GNSS_DR_Ortung_Guete_Ausrichtung 1000;
BA_REL_ "GenSigTimeoutTime" BU_SG_REL_ Gateway_PAG SG_ 2463978724 GNSS_DR_Ortung_Guete_horizontal 1000;
BA_REL_ "GenSigTimeoutTime" BU_SG_REL_ Gateway_PAG SG_ 2463978724 GNSS_DR_Ortung_Guete_vertikal 1000;
BA_REL_ "GenSigTimeoutTime" BU_SG_REL_ Gateway_PAG SG_ 2463978725 GNSS_DR_Nachrichtenpaket_ID4 1000;
BA_REL_ "GenSigTimeoutTime" BU_SG_REL_ Gateway_PAG SG_ 2463978725 GNSS_DR_Ortung_Zeit_in_GPSWoche 1000;
BA_REL_ "GenSigTimeoutTime" BU_SG_REL_ Gateway_PAG SG_ 2463978725 GNSS_DR_Ortung_Hoehe 1000;
BA_REL_ "GenSigTimeoutTime" BU_SG_REL_ Gateway_PAG SG_ 2463978725 GNSS_DR_Odometer 1000;
BA_REL_ "GenSigTimeoutTime" BU_SG_REL_ Gateway_PAG SG_ 2463978725 GNSS_DR_Pitch 1000;
BA_REL_ "GenSigTimeoutTime" BU_SG_REL_ Gateway_PAG SG_ 2463978726 GNSS_DR_UTC_Zeit 1000;
BA_REL_ "GenSigTimeoutTime" BU_SG_REL_ Gateway_PAG SG_ 2463978726 GNSS_DR_Nachrichtenpaket_ID5 1000;
BA_REL_ "GenSigTimeoutTime" BU_SG_REL_ Gateway_PAG SG_ 2549088265 Sekundaer_09_Nachlauftyp 5000;
BA_REL_ "GenSigTimeoutTime" BU_SG_REL_ Gateway_PAG SG_ 2549088265 Sekundaer_09_SNI 5000;
BA_REL_ "GenSigTimeoutTime" BU_SG_REL_ Gateway_PAG SG_ 2549088265 KN_Sekundaer_09_ECUKnockOutTimer 5000;
BA_REL_ "GenSigTimeoutTime" BU_SG_REL_ Gateway_PAG SG_ 2549088265 KN_Sekundaer_09_BusKnockOut 5000;
BA_REL_ "GenSigTimeoutTime" BU_SG_REL_ Gateway_PAG SG_ 2549088265 KN_Sekundaer_09_BusKnockOutTimer 5000;
BA_REL_ "GenSigTimeoutTime" BU_SG_REL_ Gateway_PAG SG_ 2549088265 KN_Sekundaer_09_ECUKnockOut 5000;
BA_REL_ "GenSigTimeoutTime" BU_SG_REL_ Gateway_PAG SG_ 2549088265 NM_Sekundaer_09_Lokalaktiv 5000;
BA_REL_ "GenSigTimeoutTime" BU_SG_REL_ Gateway_PAG SG_ 2549088265 NM_Sekundaer_09_Subsystemaktiv 5000;
BA_REL_ "GenSigTimeoutTime" BU_SG_REL_ Gateway_PAG SG_ 2549088265 Sekundaer_09_KD_Fehler 2500;
BA_REL_ "GenSigTimeoutTime" BU_SG_REL_ Gateway_PAG SG_ 2549088496 Sekundaer_F0_Nachlauftyp 5000;
BA_REL_ "GenSigTimeoutTime" BU_SG_REL_ Gateway_PAG SG_ 2549088496 Sekundaer_F0_SNI 5000;
BA_REL_ "GenSigTimeoutTime" BU_SG_REL_ Gateway_PAG SG_ 2549088496 KN_Sekundaer_F0_ECUKnockOutTimer 5000;
BA_REL_ "GenSigTimeoutTime" BU_SG_REL_ Gateway_PAG SG_ 2549088496 KN_Sekundaer_F0_BusKnockOut 5000;
BA_REL_ "GenSigTimeoutTime" BU_SG_REL_ Gateway_PAG SG_ 2549088496 KN_Sekundaer_F0_BusKnockOutTimer 5000;
BA_REL_ "GenSigTimeoutTime" BU_SG_REL_ Gateway_PAG SG_ 2549088496 KN_Sekundaer_F0_ECUKnockOut 5000;
BA_REL_ "GenSigTimeoutTime" BU_SG_REL_ Gateway_PAG SG_ 2549088496 NM_Sekundaer_F0_Lokalaktiv 5000;
BA_REL_ "GenSigTimeoutTime" BU_SG_REL_ Gateway_PAG SG_ 2549088496 Sekundaer_F0_KD_Fehler 2500;
VAL_ 2463978723 GNSS_DR_Ortung_Ausrichtung 4094 "Init" 4095 "Fehler" ;
VAL_ 2463978723 GNSS_DR_Ortung_2D_Geschw_u_Grund 510 "Init" 511 "Fehler" ;
VAL_ 2463978724 GNSS_DR_Ortung_Guete_Geschwindig 62 "Init" 63 "Fehler" ;
VAL_ 2463978724 GNSS_DR_Ortung_Guete_Ausrichtung 62 "Init" 63 "Fehler" ;
VAL_ 2463978724 GNSS_DR_Ortung_Guete_horizontal 254 "Init" 255 "Fehler" ;
VAL_ 2463978724 GNSS_DR_Ortung_Guete_vertikal 62 "Init" 63 "Fehler" ;
VAL_ 2463978725 GNSS_DR_Ortung_Zeit_in_GPSWoche 1073741822 "Init" 1073741823 "Fehler" ;
VAL_ 2463978725 GNSS_DR_Ortung_Hoehe 4094 "Init" 4095 "Fehler" ;
VAL_ 2463978725 GNSS_DR_Odometer 510 "Init" 511 "Fehler" ;
VAL_ 2463978725 GNSS_DR_Pitch 2046 "Init" 2047 "Fehler" ;
VAL_ 2463978726 GNSS_DR_UTC_Zeit 0 "Init" ;
VAL_ 310 HAL_Status 0 "Normalbetrieb" 1 "Lenkungsausfall" 2 "Derating_aktiv" 3 "Lenkung_manuell_deaktiviert" ;
VAL_ 310 HAL_VZ_Radwinkel 0 "positiv_Lenkeinschlag_links" 1 "negativ_Lenkeinschlag_rechts" ;
VAL_ 310 HAL_QBit_Radwinkel 0 "gueltiger_Wert" 1 "Ersatz_Init_oder_Fehlerwert" ;
VAL_ 310 HAL_Radwinkel 1020 "Unterspannung" 1021 "nicht_kalibriert" 1022 "Init" 1023 "Fehler" ;
VAL_ 310 HAL_Warnungen 0 "keine_Warnung" 1 "Ausfall_rote_Warnung" 2 "Systemstoerung_gelbe_Warnung" 3 "HAL_deaktiviert" ;
VAL_ 310 HAL_Winkelbegrenzung 0 "nicht_aktiv" 1 "Lenkwinkelbegrenzung_aktiv" ;
VAL_ 310 HAL_VZ_Fahrerwunschwinkel_Soll 0 "positiv" 1 "negativ" ;
VAL_ 310 HAL_Fahrerwunschwinkel_Soll 1022 "Init" 1023 "Fehler" ;
VAL_ 310 HAL_max_Gradient 126 "Init" 127 "Fehler" ;
VAL_ 310 HAL_EFP_FahrPr 0 "keine_Funktion" 1 "Programm_1" 2 "Programm_2" 3 "Programm_3" 4 "Programm_4" 5 "Programm_5" 6 "Programm_6" 7 "Programm_7" 8 "Programm_8" 9 "Programm_9" 10 "Programm_10" 11 "Programm_11" 12 "Programm_12" 13 "Programm_13" 14 "Programm_14" 15 "Programm_15" ;
VAL_ 310 HAL_Status_2 0 "Init" 1 "Fahrbereit" 2 "Symmetriefahrt" 3 "Gelbe_Warnung" 4 "Rote_Warnung" 5 "Hinterachlenkung_deaktiviert" ;
VAL_ 310 HAL_Charisma_Status 0 "Init" 1 "verfuegbar" 2 "nicht_verfuegbar" 3 "asynchron_durch_Fahrerwunsch" ;
VAL_ 310 HAL_Charisma_FahrPr 0 "keine_Funktion" 1 "Programm_1" 2 "Programm_2" 3 "Programm_3" 4 "Programm_4" 5 "Programm_5" 6 "Programm_6" 7 "Programm_7" 8 "Programm_8" 9 "Programm_9" 10 "Programm_10" 11 "Programm_11" 12 "Programm_12" 13 "Programm_13" 14 "Programm_14" 15 "Programm_15" ;
VAL_ 29 IMMO_Auth_Master_Slave07_Sig1 0 "Initwert" ;
VAL_ 28 IMMO_Auth_Slave07_Master_Sig1 0 "Init" ;
VAL_ 960 RSt_Fahrerhinweise 0 "Init" 1 "Fahreruebernahme_Hinweis_ZAT_Automat_ohne_Gong" 2 "Fahreruebernahme_Hinweis_ZAT_Automat_mit_Gong" 3 "Fahreruebernahme_Hinweis_ZAT_Handschalter_ohne_Gong" 4 "Fahreruebernahme_Hinweis_ZAT_Handschalter_mit_Gong" 5 "Fahreruebernahme_Hinweis_ZAS_Automat_ohne_Gong" 6 "Fahreruebernahme_Hinweis_ZAS_Automat_mit_Gong" 7 "Fahreruebernahme_Hinweis_ZAS_Handschalter_ohne_Gong" 8 "Fahreruebernahme_Hinweis_ZAS_Handschalter_mit_Gong" 9 "RemoteStart_aktiv_ohne_Gong" 10 "RemoteStart_aktiv_mit_Gong" 11 "void" 12 "void" 13 "void" 14 "void" 15 "void" ;
VAL_ 960 ZAS_Kl_S 0 "aus" 1 "S_Kontakt_ein" ;
VAL_ 960 ZAS_Kl_15 0 "aus" 1 "ein" ;
VAL_ 960 ZAS_Kl_X 0 "aus" 1 "ein" ;
VAL_ 960 ZAS_Kl_50_Startanforderung 0 "aus" 1 "KL50_ein_Startwunsch_Fahrer" ;
VAL_ 960 BCM_Remotestart_Betrieb 0 "kein_RS_Betrieb" 1 "RS_Betrieb" ;
VAL_ 960 ZAS_Kl_Infotainment 0 "inaktiv" 1 "aktiv" ;
VAL_ 960 BCM_Remotestart_KL15_Anf 0 "inaktiv" 1 "aktiv" ;
VAL_ 960 BCM_Remotestart_MO_Start 0 "nicht_angefordert" 1 "angefordert" ;
VAL_ 960 KST_Warn_P1_ZST_def 0 "nicht_defekt" 1 "defekt" ;
VAL_ 960 KST_Warn_P2_ZST_def 0 "nicht_defekt" 1 "defekt" ;
VAL_ 960 KST_Fahrerhinweis_1 0 "inaktiv" 1 "aktiv" ;
VAL_ 960 KST_Fahrerhinweis_2 0 "inaktiv" 1 "aktiv" ;
VAL_ 960 BCM_Ausparken_Betrieb 0 "kein_Betrieb" 1 "Ausparkvorgang_aktiv" ;
VAL_ 960 KST_Fahrerhinweis_4 0 "inaktiv" 1 "aktiv" ;
VAL_ 960 KST_Fahrerhinweis_5 0 "inaktiv" 1 "aktiv" ;
VAL_ 960 KST_Fahrerhinweis_6 0 "inaktiv" 1 "aktiv" ;
VAL_ 2549088272 Gateway_KompSchutz 0 "inaktiv" 1 "aktiv" ;
VAL_ 2549088272 Gateway_Abschaltstufe 0 "keine_Einschraenkung" 1 "Funktionseinschraenkung" ;
VAL_ 2549088272 Gateway_Transport_Mode 0 "keine_Einschraenkung" 1 "Funktionseinschraenkung" ;
VAL_ 2549088272 Gateway_Nachlauftyp 0 "Komm_bei_KL15_EIN" 1 "Komm_nach_KL15_AUS" 2 "Komm_bei_KL15_AUS" ;
VAL_ 2549088272 Gateway_SNI 16 "Gateway" ;
VAL_ 2549088272 NM_Gateway_Wakeup 0 "Peripherie_Wakeup__Ursache_nicht_bekannt" 1 "Bus_Wakeup" 2 "KL15_HW" 3 "ACAN_Wakeup" 4 "FCAN_Wakeup" 5 "KCAN_Wakeup" 6 "ICAN_Wakeup" 7 "DiagCAN_Wakeup" 8 "ECAN_Wakeup" 9 "Energie_LIN_Wakeup" 10 "Bedien_LIN_Wakeup" 11 "HybridCAN_Wakeup" 12 "Flexray_Wakeup" 13 "MFL_WakeUp" 14 "Ethernet" 15 "DCAN_Wakeup" 16 "K2CAN_Wakeup" 17 "CCAN" 18 "AFSCAN_Wakeup" 19 "LIN1" 20 "LIN2" 21 "LIN3" 22 "LIN4" 23 "LIN5" 24 "LIN6" 25 "FASCAN" 26 "FAS2CAN" 27 "MDKCAN" 32 "FlexRay_Branch1_WakeUp" 33 "FlexRay_Branch2_WakeUp" 34 "FlexRay_Branch3_WakeUp" 35 "FlexRay_Branch4_WakeUp" 36 "FlexRay_Branch5_WakeUp" 37 "FlexRay_Branch6_WakeUp" 38 "FlexRay_Branch7_WakeUp" 39 "FlexRay_Branch8_WakeUp" 40 "FlexRay_Branch9_WakeUp" 41 "FlexRay_Branch10_WakeUp" 42 "FlexRay_Branch11_WakeUp" 43 "FlexRay_Branch12_WakeUp" 44 "FlexRay_Branch13_WakeUp" 45 "FlexRay_Branch14_WakeUp" 46 "FlexRay_Branch15_WakeUp" 47 "FlexRay_Branch16_WakeUp" 128 "Energiemanagement" 129 "Funktionswakeup_OBDC" 130 "Hochvoltenergiemanagement" 131 "CWU_empfangen" 132 "Fuer_Bus_relevanten_FC_empfangen" 133 "OnlineDienst_empfangen" 134 "HV_Aktivieren" 135 "HV_Deaktivieren" 136 "VTS_Suche_DriverCard" 137 "VTS_Hupen_Blinken" 138 "Remote_Vehicle_Status" 139 "Plug_and_Charge" 140 "VTS_Wakeup_Infotainment" 141 "EMHLR" 142 "NFcGW_fordert_OTA_FC_an" 143 "Komponentenschutz" 144 "UserStateServer" 145 "Dimmung" 146 "Kessy" 147 "StandardAussenlicht" 148 "ParkKoordinator" 149 "HVLMDynamicChargingPOI" 150 "HVLMChargingManagementServer" 151 "HVLMExtendedChargingMonitoring" 152 "Zentralverriegelung" 153 "FunctionOnDemand" 154 "IAA" 155 "StandKlimatisierung" 156 "RealTimeMonitor" 157 "Klemmensteuerung" 158 "Fremdladung_erkannt" ;
VAL_ 2549088272 NM_Gateway_Lokalaktiv 0 "war_nicht_lokal_aktiv" 1 "war_lokal_aktiv" ;
VAL_ 2549088272 NM_Gateway_Subsystemaktiv 0 "Subsystem_war_nicht_lokalaktiv" 1 "war_lokalaktiv" ;
VAL_ 2549088272 GW_KD_Fehler 0 "kein_KD_Fehler" 1 "KD_Fehler" ;
VAL_ 2549088265 Sekundaer_09_KompSchutz 0 "inaktiv" 1 "aktiv" ;
VAL_ 2549088265 Sekundaer_09_Abschaltstufe 0 "keine_Einschraenkung" 1 "Funktionseinschraenkung" ;
VAL_ 2549088265 Sekundaer_09_Transport_Mode 0 "keine_Einschraenkung" 1 "Funktionseinschraenkung" ;
VAL_ 2549088265 Sekundaer_09_Nachlauftyp 0 "Komm_bei_KL15_EIN" 1 "Komm_nach_KL15_AUS" 2 "Komm_bei_KL15_AUS" ;
VAL_ 2549088265 Sekundaer_09_SNI 9 "Sekundaer_09" ;
VAL_ 2549088265 KN_Sekundaer_09_ECUKnockOutTimer 63 "ECUKnockOut_deaktiviert" ;
VAL_ 2549088265 KN_Sekundaer_09_BusKnockOut 0 "Funktion_nicht_ausgeloest" 1 "Veto_aktiv" 2 "Funktion_ausgeloest" 3 "Funktion_deaktiviert" ;
VAL_ 2549088265 KN_Sekundaer_09_BusKnockOutTimer 255 "BusKnockOut_deaktiviert" ;
VAL_ 2549088265 NM_Sekundaer_09_OTA_FC_Wakeup 0 "Peripherie_Wakeup__Ursache_nicht_bekannt" 1 "Bus_Wakeup" 2 "KL15_HW" 3 "KCAN_Wakeup" 10 "RemoteFunction_1" 11 "RemoteFunction_2" 12 "RemoteFunction_3" 13 "RemoteFunction_4" 14 "RemoteFunction_5" 15 "RemoteFunction_6" 16 "RemoteFunction_7" 17 "RemoteFunction_8" 18 "RemoteFunction_9" 19 "RemoteFunction_10" 20 "RemoteFunction_11" 21 "RemoteFunction_12" 22 "RemoteFunction_13" 23 "RemoteFunction_14" 24 "RemoteFunction_15" 30 "RemoteUpdate_1" 40 "RemoteDiagnose_1" 50 "MOD_1" 51 "MOD_2" 52 "MOD_3" 53 "MOD_4" 54 "MOD_5" 100 "BackendCommunication" ;
VAL_ 2549088265 KN_Sekundaer_09_ECUKnockOut 0 "Funktion_nicht_ausgeloest" 1 "Veto_war_aktiv" 2 "Funktion_ausgeloest" 3 "Funktion_deaktiviert" ;
VAL_ 2549088265 KN_Sekundaer_09_DiagPfad 0 "aktiv" 1 "inaktiv" ;
VAL_ 2549088265 NM_Sekundaer_09_Lokalaktiv 0 "war_nicht_lokal_aktiv" 1 "war_lokal_aktiv" ;
VAL_ 2549088265 NM_Sekundaer_09_Subsystemaktiv 0 "Subsystem_war_nicht_lokalaktiv" 1 "war_lokalaktiv" ;
VAL_ 2549088265 Sekundaer_09_KD_Fehler 0 "kein_KD_Fehler" 1 "KD_Fehler" ;
VAL_ 2549088496 Sekundaer_F0_KompSchutz 0 "inaktiv" 1 "aktiv" ;
VAL_ 2549088496 Sekundaer_F0_Abschaltstufe 0 "keine_Einschraenkung" 1 "Funktionseinschraenkung" ;
VAL_ 2549088496 Sekundaer_F0_Transport_Mode 0 "keine_Einschraenkung" 1 "Funktionseinschraenkung" ;
VAL_ 2549088496 Sekundaer_F0_Nachlauftyp 0 "Komm_bei_KL15_EIN" 1 "Komm_nach_KL15_AUS" 2 "Komm_bei_KL15_AUS" ;
VAL_ 2549088496 Sekundaer_F0_SNI 240 "Sekundaer_F0" ;
VAL_ 2549088496 KN_Sekundaer_F0_ECUKnockOutTimer 63 "ECUKnockOut_deaktiviert" ;
VAL_ 2549088496 KN_Sekundaer_F0_BusKnockOut 0 "Funktion_nicht_ausgeloest" 1 "Veto_aktiv" 2 "Funktion_ausgeloest" 3 "Funktion_deaktiviert" ;
VAL_ 2549088496 KN_Sekundaer_F0_BusKnockOutTimer 255 "BusKnockOut_deaktiviert" ;
VAL_ 2549088496 NM_Sekundaer_F0_Wakeup 0 "Peripherie_Wakeup__Ursache_nicht_bekannt" 1 "Bus_Wakeup" 2 "KL15_HW" 3 "Anforderung_Backend" 4 "VTS" 5 "Timer_Wechsel" 6 "Schluessel_per_BT_erkannt" ;
VAL_ 2549088496 KN_Sekundaer_F0_ECUKnockOut 0 "Funktion_nicht_ausgeloest" 1 "Veto_war_aktiv" 2 "Funktion_ausgeloest" 3 "Funktion_deaktiviert" ;
VAL_ 2549088496 NM_Sekundaer_F0_Lokalaktiv 0 "war_nicht_lokal_aktiv" 1 "war_lokal_aktiv" ;
VAL_ 2549088496 Sekundaer_F0_KD_Fehler 0 "kein_KD_Fehler" 1 "KD_Fehler" ;
VAL_ 779 KBI_ABS_Lampe 0 "ABS Lampe aus" 1 "ABS Lampe ein" ;
VAL_ 779 KBI_ESP_Lampe 0 "ESP Lampe aus" 1 "ESP Lampe ein" ;
VAL_ 779 KBI_BKL_Lampe 0 "BKL aus" 1 "BKL ein" ;
VAL_ 779 KBI_Airbag_Lampe 0 "Airbag Lampe aus" 1 "Airbag Lampe ein" ;
VAL_ 779 KBI_SILA_gueltig 0 "ungueltig" 1 "gueltig" ;
VAL_ 779 KBI_Vorglueh_System_Lampe 0 "Lampe aus" 1 "Lampe ein" ;
VAL_ 779 KBI_NV_in_Anzeige 0 "NV_nicht_in_Anzeige" 1 "NV_in_Anzeige" ;
VAL_ 779 KBI_Anzeigestatus_ACC 0 "keine_ACC_Anzeige" 1 "ACC_Anzeige_aktiv" ;
VAL_ 779 KBI_Anzeigestatus_GRA 0 "nicht_vorhanden" 1 "Anzeigemoeglichkeit_vorhanden" 2 "reserviert" 3 "Fehler" ;
VAL_ 779 KBI_Tankwarnung 0 "Lampe aus" 1 "Lampe ein" ;
VAL_ 779 KBI_MFA_v_Einheit_01 0 "kmh" 1 "mph" ;
VAL_ 779 KBI_im_Stellgliedtest 0 "kein Stellgliedtest" 1 "Kombi im Stellgliedtest" ;
VAL_ 779 KBI_Anzeigefehler_LDW 0 "nicht vorhanden bzw. unterstützt" 1 "Anzeige iO" 2 "Anzeigefehler" 3 "nicht definiert" ;
VAL_ 779 KBI_Tankwarnung_ungueltig 0 "KBI_Tankwarnung_gueltig" 1 "KBI_Tankwarnung_ungueltig" ;
VAL_ 779 KBI_Handbremse 0 "nicht_angezogen" 1 "angezogen" ;
VAL_ 779 KBI_PLA_in_Anzeige 0 "PLA_nicht_in_Anzeige" 1 "PLA_in_Anzeige" ;
VAL_ 779 KBI_Anzeigefehler_NV 0 "kein_Anzeigefehler" 1 "Anzeigefehler" ;
VAL_ 779 KBI_Anzeigestatus_LIM 0 "nicht_vorhanden" 1 "Anzeigemoeglichkeit_vorhanden" 2 "reserviert" 3 "Fehler" ;
VAL_ 779 KBI_ARA_in_Anzeige 0 "ARA nicht in Anzeige" 1 "ARA in Anzeige" ;
VAL_ 779 KBI_Taster_Lift 0 "nicht_betaetigt" 1 "betaetigt" ;
VAL_ 779 KBI_Taster_Fahrwerk 0 "nicht_betaetigt" 1 "betaetigt" ;
VAL_ 779 KBI_GRA_Hauptschalter 0 "Init" 1 "Hauptschalter_aus" 2 "Hauptschalter_ein" 3 "Fehler" ;
VAL_ 779 KBI_Bestaetigung_ESP_Off 0 "ESP_off_nicht_quittiert" 1 "ESP_off_quittiert" 2 "Abbruch" ;
VAL_ 779 KBI_Einheit_Tacho 0 "km/h" 1 "mph" ;
VAL_ 779 KBI_Konsistenz_ACC 0 "ACC Botschaft konsistent" 1 "ACC Botschaft inkonsistent" ;
VAL_ 779 KBI_Fehler_Anzeige_ACC 0 " iO" 1 "Anzeigefehler ACC" ;
VAL_ 779 KBI_Anzeigefehler_SWA 0 "nicht vorhanden bzw. unterstützt" 1 "Anzeige iO" 2 "Anzeigefehler" 3 "nicht definiert" ;
VAL_ 779 KBI_Systemstatus 0 "KBI_IO" 1 "KBI_System_Failure" ;
VAL_ 1719 KBI_Kilometerstand 1048574 "Init" 1048575 "Fehler" ;
VAL_ 1719 KBI_Standzeit_02 131069 "nicht_verfuegbar" 131070 "Init" 131071 "Fehler" ;
VAL_ 1719 KBI_LVDS_Lock 0 "Init_LVDS_nicht_gelockt" 1 "LVDS_gelockt" ;
VAL_ 1719 KBI_Reserve_Warnung_Sek 0 "Keine_Warnung" 1 "Sekundaere_Reservewarnung" ;
VAL_ 1719 KBI_RDK_Kalibrier_Anf 0 "keine_Kalibrieranforderung" 1 "Kalibrieranforderung" ;
VAL_ 1719 KBI_Inhalt_Tank 126 "Init" 127 "Fehler" ;
VAL_ 1719 KBI_FStatus_Tank 0 "Tankfüllstand i.O." 1 "Tankfüllstand n.i.O" ;
VAL_ 1719 KBI_aktive_Laengsfunktion 0 "Init" 1 "Speedlimiter" 2 "GRA_oder_ACC" 3 "PACCh" 4 "HDC" 5 "p_GRA" 6 "p_Lim" 7 "Umschaltung_GRA_Limiter" ;
VAL_ 1719 KBI_TA_gewaehlt_Fahrer 0 "TA_nicht_gewaehlt_Kombi" 1 "TA_gewaehlt_Kombi" ;
VAL_ 1719 KBI_FoD_PopUP_Quittiert 0 "nicht_quittiert" 1 "Meldung_quittiert" ;
VAL_ 1719 KBI_GRA_im_ACC 0 "GRA_im_ACC_nicht_ausgewaehlt" 1 "GRA_im_ACC_ausgewaehlt" ;
VAL_ 1719 KBI_Oelwechsel_durchgefuehrt 0 "Oelwechsel_nicht_durchgefuehrt" 1 "Oelwechsel_durchgefuehrt" ;
VAL_ 1719 KBI_QBit_Aussen_Temp_gef 0 "gueltiger_Wert" 1 "Ersatz_Init_oder_Fehlerwert" ;
VAL_ 1719 KBI_Aussen_Temp_gef 253 "nicht verbaut" 254 "Init" 255 "Fehler" ;
VAL_ 1720 KBI_Variante_USA 0 "keine USA-Variante" 1 "USA-Variante" ;
VAL_ 1720 KBI_Variante 0 "Zeiger Kombiinstrument" 1 "Volldisplay Kombiinstrument" ;
VAL_ 1720 KBI_GAP_Warn_Zeit_abgelaufen 0 "Zaehler_nicht_abgelaufen" 1 "Zaehler_abgelaufen" ;
VAL_ 1720 KBI_Quittierung_Naesse 0 "nicht_quittiert" 1 "quittiert" ;
VAL_ 1720 KBI_BCmE_aktiv 0 "Anzeige_nicht_aktiv" 1 "Anzeige_aktiv" ;
VAL_ 1720 KBI_Sparhinweis_quittiert 0 "nicht_quittiert" 1 "quittiert" ;
VAL_ 1720 KBI_Tankfuellstand_Prozent 126 "Init" 127 "Fehler" ;
VAL_ 1720 KBI_Nachtanken_erkannt 0 "Geberbetrieb" 1 "Nachtankmodus" ;
VAL_ 1720 KBI_Tankinhalt_hochaufl 16382 "Init" 16383 "Fehler" ;
VAL_ 1720 KBI_Max_Tankinhalt 254 "Init" 255 "Fehler" ;
VAL_ 1720 KBI_Quittierung_cAQP 0 "nicht_quittiert" 1 "quittiert" ;
VAL_ 2527679653 MXB_LAPP_Freigabe 0 "keine_Freigabe" 1 "Freigabe" ;
VAL_ 2527679653 MXB_LAPP_ZR_Sondermodus_Anf 0 "nicht_angefordert" 1 "angefordert" ;
VAL_ 2527679653 MXB_LAPP_Status_FL 0 "MXB_aus" 1 "MXB_regelt" 2 "MXB_volles_Fernlicht" 3 "MXB_und_Laser_aktiv" ;
VAL_ 810 EPS_SpannungsAnf 0 "keine_Anforderung" 1 "Anforderung_Stufe1" 2 "Anforderung_Stufe2" 3 "Anforderung_Stufe3" ;
VAL_ 810 EPS_Endanschlag 0 "Init_bzw_Defaultlenkhub" 1 "Lenkhubaufweitung_1" 2 "EA_nicht_angelernt_bzw_Initialisierung_nicht_abgeschlossen" 3 "Fehler" ;
VAL_ 810 EPS_Fehlerlampe 0 "Lampe_aus" 1 "Lampe_ein" ;
VAL_ 810 EPS_Warnungen 0 "kein_Text" 1 "Text_1" 2 "Text_2" 3 "Text_3" 4 "Text_4" 5 "Text_5" ;
VAL_ 810 EPS_PWR_Abbruch 0 "Init/Invalid" 1 "PWR beendet durch EPS-SG wegen vFzg" 2 "PWR beendet durch EPS-SG wegen HM" 3 "Lenkwinkeldifferenz zu groß" 4 "Gradient der Zielanforderung zu groß" 5 "reserviert" 6 "reserviert" 7 "reserviert" 8 "Falscher PLA-Status" 9 "Falscher ARA-Status" 10 "reserviert" 11 "reserviert" 12 "reserviert" 13 "reserviert" 14 "reserviert" 15 "reserviert" ;
VAL_ 810 EPS_PWR_Fehler 0 "Init/Invalid" 1 "Unterstützungsleistung zu gering" 2 "reserviert" 3 "Rotorwinkel nicht initialisiert" 4 "BCM1/Rückfahrlicht veraltet" 5 "reserviert" 6 "reserviert" 7 "Fehler ESP(vFzg)" 8 "Fehler ESP(Raddrehzahlen)" 9 "reserviert" 10 "reserviert" 11 "reserviert" 12 "reserviert" 13 "reserviert" 14 "EPS_ARA_Satus == 6" 15 "EPS_PLA_Satus == 6" ;
VAL_ 810 EPS_PLA_Status 0 "EPS_PLA_Deaktiv" 1 "EPS_PLA_Init" 2 "EPS_PLA_Fehler_mit_Eintrag" 3 "reserviert" 4 "reserviert" 5 "reserviert" 6 "EPS_PLA_Lenkwinkel_aktiv" 7 "EPS_PLA_Abgewiesen" 8 "EPS_PLA_Funktionsbereit" 9 "reserviert" 10 "EPS_PLA_Abbruch" 11 "reserviert" 12 "reserviert" 13 "reserviert" 14 "reserviert" 15 "reserviert" ;
VAL_ 810 EPS_Charisma_FahrPr 0 "keine_Funktion" 1 "Programm_1" 2 "Programm_2" 3 "Programm_3" 4 "Programm_4" 5 "Programm_5" 6 "Programm_6" 7 "Programm_7" 8 "Programm_8" 9 "Programm_9" 10 "Programm_10" 11 "Programm_11" 12 "Programm_12" 13 "Programm_13" 14 "Programm_14" 15 "Programm_15" ;
VAL_ 810 EPS_Charisma_Status 0 "Init" 1 "verfuegbar" 2 "nicht_verfuegbar" 3 "asynchron_durch_Fahrerwunsch" ;
VAL_ 810 EPS_Lenkerposition 0 "unbekannt" 1 "Linkslenker" 2 "Rechtslenker" ;
VAL_ 810 EPS_Anf_KL 0 "keine_Anforderung" 1 "Anforderung_Kuehlung" ;
VAL_ 810 EPS_ARA_Status 0 "EPS_ARA_Deaktiv" 1 "EPS_ARA_Init" 2 "EPS_ARA_Fehler_mit_Eintrag" 3 "reserviert" 4 "reserviert" 5 "reserviert" 6 "EPS_ARA_Lenkwinkel_aktiv" 7 "EPS_ARA_Abgewiesen" 8 "EPS_ARA_Funktionsbereit" 9 "reserviert" 10 "EPS_ARA_Abbruch" 11 "reserviert" 12 "reserviert" 13 "reserviert" 14 "reserviert" 15 "reserviert" ;
VAL_ 159 EPS_DSR_Status_02 0 "DSR_deaktiviert" 1 "DSR_Anf_nicht_ausfuehrbar" 2 "Kom_ESP_gestoert" 3 "EPS_funktionsbereit" 4 "DSR_Anf_abgew" 5 "ext_Momeingriff_aktiv" 6 "ext_LWeingriff_aktiv" 7 "ext_MomLWeingriff_aktiv" 8 "DSR_abgewiesen_aufgrund_Momentenpriorisierung" 9 "Anf_abgewiesen_Bedienueblich" 14 "Init" ;
VAL_ 159 EPS_Berechneter_LW 4094 "Init" 4095 "Fehler" ;
VAL_ 159 EPS_BLW_QBit 0 "gueltiger_Wert" 1 "Ersatz_Init_oder_Fehlerwert" ;
VAL_ 159 EPS_VZ_BLW 0 "positiv" 1 "negativ" ;
VAL_ 159 EPS_HCA_Status_02 0 "nicht_aktiv" 1 "Anf_nicht_ausfuehrbar" 2 "KomFehler" 3 "bereit" 4 "Anf_abgewiesen_Fehler" 5 "LaneAssist_1_aktiv" 6 "ManoeverAssist_aktiv" 7 "LaneAssist_2_aktiv" 8 "Anf_abgewiesen_Prio" 9 "Anf_abgewiesen_bedienueblich" 10 "bereit_2" 14 "Init" ;
VAL_ 159 EPS_Lenkmoment 1022 "Init" 1023 "Fehler" ;
VAL_ 159 EPS_Lenkmoment_QBit 0 "gueltiger_Wert" 1 "Ersatz_Init_oder_Fehlerwert" ;
VAL_ 159 EPS_VZ_Lenkmoment 0 "positiv" 1 "negativ" ;
VAL_ 159 EPS_Lenkungstyp 0 "RCEPS_Serie" 1 "RCEPS_Dynamiklenkung" 2 "MQB_DP" 3 "MQB_APA" 4 "MQB_Direktlenkung" 15 "unbekannt" ;
VAL_ 2331595840 LHW_eventABSactivated 0 "ABSactivated_off" 1 "ABSactivated_on" ;
VAL_ 2331595840 LHW_eventAirBagDeployment 0 "AirBagDeployment_off" 1 "AirBagDeployment_on" ;
VAL_ 2331595840 LHW_eventDisabledVehicle 0 "DisabledVehicle_off" 1 "DisabledVehicle_on" ;
VAL_ 2331595840 LHW_eventFlatTire 0 "FlatTire_off" 1 "FlatTire_on" ;
VAL_ 2331595840 LHW_eventHardBraking 0 "HardBraking_off" 1 "HardBraking_on" ;
VAL_ 2331595840 LHW_eventHazardLights 0 "HazardLights_off" 1 "HazardLights_on" ;
VAL_ 2331595840 LHW_eventStabilityControlActive 0 "StabilityControlActivated_off" 1 "StabilityControlActivated_on" ;
VAL_ 2331595840 LHW_eventTractionControlLoss 0 "TractionControlLoss_off" 1 "TractionControlLoss_on" ;
VAL_ 981 BCM1_Kurvenlicht_links_Anf 0 "linkes_Kurvenlicht/Abbiegelicht_durch_BCM1_nicht_angesteuert" 1 "linkes_Kurven/Abbiegelicht_durch_BCM1_angesteuert" ;
VAL_ 981 BCM1_Kurvenlicht_rechts_Anf 0 "rechtes_Kurvenlicht/Abbiegelicht_durch_BCM1_nicht_angesteuert" 1 "rechtes_Kurvenlicht/Abbiegelicht_durch_BCM1_angesteuert" ;
VAL_ 981 BCM1_Standlicht_Anf 0 "Licht_nicht_angefordert" 1 "Licht ist einzuschalten" ;
VAL_ 981 BCM1_Abblendlicht_Anf 0 "Licht_nicht_angefordert" 1 "Licht ist einzuschalten" ;
VAL_ 981 BCM1_Fernlicht_Anf 0 "Licht_nicht_angefordert" 1 "Licht ist einzuschalten" ;
VAL_ 981 BCM1_Nebellicht_Anf 0 "Licht_nicht_angefordert" 1 "Licht ist einzuschalten" ;
VAL_ 981 BCM1_Parklicht_li_Anf 0 "Licht_nicht_angefordert" 1 "Licht ist einzuschalten" ;
VAL_ 981 BCM1_Parklicht_re_Anf 0 "Licht_nicht_angefordert" 1 "Licht ist einzuschalten" ;
VAL_ 981 BCM1_Nebelschluss_Ahg_Anf 0 "Licht_nicht_angefordert" 1 "Licht ist einzuschalten" ;
VAL_ 981 BCM1_Nebelschluss_Fzg_Anf 0 "Licht_nicht_angefordert" 1 "Licht_ist_einzuschalten" ;
VAL_ 981 BCM1_Schlusslicht_Anf 0 "Licht_nicht_angefordert" 1 "Licht ist einzuschalten" ;
VAL_ 981 BCM_Rueckfahrlicht_Anf 0 "Licht_nicht_angefordert" 1 "Licht_angefordert" ;
VAL_ 981 BCM1_Signaturlicht_Anf 0 "Licht_nicht_angefordert" 1 "Licht_ist_einzuschalten" ;
VAL_ 981 BCM1_Umfeldleuchten_Anf 0 "Licht_nicht_angefordert" 1 "Licht_ist_einzuschalten" ;
VAL_ 981 BCM1_Tagfahrlicht_Anf 0 "Licht_nicht_angefordert" 1 "Licht ist einzuschalten" ;
VAL_ 981 BCM1_Regenlicht_Anf 0 "Licht_nicht_angefordert" 1 "Licht ist einzuschalten" ;
VAL_ 981 BCM1_Autobahnlicht_Anf 0 "Licht_nicht_angefordert" 1 "Licht ist einzuschalten" ;
VAL_ 981 BCM1_Touristen_Licht_Anf 0 "Licht_nicht_angefordert" 1 "Anforderung von Touristenlicht" ;
VAL_ 981 BCM1_CH_aktiv 0 "Inaktiv" 1 "Aktiv" ;
VAL_ 981 BCM1_LH_aktiv 0 "Inaktiv" 1 "Aktiv" ;
VAL_ 981 BCM1_Gleitende_Leuchtw_Anf 0 "Aus" 1 "Ein" ;
VAL_ 981 BCM1_GLW_Fernlicht_Anf 0 "Aus" 1 "Ein" ;
VAL_ 981 BCM1_Adaptive_Lichtvert_Anf 0 "Aus" 1 "Ein" ;
VAL_ 981 BCM1_FoD_Sperrung_WiBli 0 "Freigabe_WiBli" 1 "Sperrung_WiBli" 2 "Init" ;
VAL_ 981 BCM1_FOD_Sperrung_Animationen_HL 0 "Freigabe_Animationen" 1 "Sperrung_Animationen" 2 "Init" ;
VAL_ 981 BCM1_Animationssperrung 0 "keine_Sperrung" 1 "Sperrung" ;
VAL_ 981 BCM1_CH_LH_aktiv 0 "Comming_Home_Bzw._Leaving_Home_nicht_aktiv" 1 "Comming Home bzw. Leaving Home aktiv" ;
VAL_ 981 BCM1_Allwetterlicht_Anf 0 "Licht_nicht_angefordert" 1 "Licht_ist_einzuschalten" ;
VAL_ 981 BCM1_Schlusslicht_Signatur 0 "keine_Signatur" 1 "Signatur_1" 2 "Signatur_2" 3 "Signatur_3" 4 "Signatur_4" 5 "Signatur_5" 6 "Signatur_6" 7 "Signatur_7" 8 "Signatur_8" 9 "Signatur_9" 10 "Signatur_10" 11 "Signatur_11" 12 "Signatur_12" 13 "Signatur_13" 14 "Signatur_14" 15 "Signatur_15" ;
VAL_ 1624 LV_Standlicht_Anzeige 0 "nicht aktiv" 1 "aktiv" ;
VAL_ 1624 LV_Abblendlicht_Anzeige 0 "inaktiv" 1 "aktiv" ;
VAL_ 1624 LV_Fernlicht_Anzeige 0 "nicht aktiv" 1 "aktiv" ;
VAL_ 1624 LV_Nebellicht_Anzeige 0 "nicht aktiv" 1 "aktiv" ;
VAL_ 1624 LV_Nebelschlusslicht_Anzeige 0 "nicht aktiv" 1 "aktiv" ;
VAL_ 1624 LV_Tagfahrlicht_Anzeige 0 "nicht aktiv" 1 "aktiv" ;
VAL_ 1624 LV_AFL_aktiv_Anzeige 0 "nicht aktiv" 1 "aktiv" ;
VAL_ 1624 LV_AFL_defekt 0 "OK" 1 "defekt" ;
VAL_ 1624 LV_Blinker_li_def 0 "OK" 1 "defekt" ;
VAL_ 1624 LV_Standlicht_li_def 0 "OK" 1 "defekt" ;
VAL_ 1624 LV_Abblendlicht_li_def 0 "OK" 1 "defekt" ;
VAL_ 1624 LV_Fernlicht_li_def 0 "OK" 1 "defekt" ;
VAL_ 1624 LV_Nebellicht_li_def 0 "OK" 1 "defekt" ;
VAL_ 1624 LV_Blk_li_Seite_def 0 "OK" 1 "defekt" ;
VAL_ 1624 LV_Tagfahrlicht_li_def 0 "OK" 1 "defekt" ;
VAL_ 1624 LV_FLA_aktiv_Anzeige 0 "aus" 1 "ein" ;
VAL_ 1624 LV_FLA_defekt 0 "i.O." 1 "FLA defekt" ;
VAL_ 1624 LV_FLA_Sensor_blockiert 0 "i.O." 1 "FLA-Sensor blockiert" ;
VAL_ 1624 LV_Blinker_re_def 0 "OK" 1 "defekt" ;
VAL_ 1624 LV_Standlicht_re_def 0 "OK" 1 "defekt" ;
VAL_ 1624 LV_Abblendlicht_re_def 0 "OK" 1 "defekt" ;
VAL_ 1624 LV_Fernlicht_re_def 0 "OK" 1 "defekt" ;
VAL_ 1624 LV_Nebellicht_re_def 0 "OK" 1 "defekt" ;
VAL_ 1624 LV_Blk_re_Seite_def 0 "OK" 1 "defekt" ;
VAL_ 1624 LV_Tagfahrlicht_re_def 0 "OK" 1 "defekt" ;
VAL_ 1624 LV_Aussenlicht_def 0 "OK" 1 "defekt" ;
VAL_ 1624 LV_Abblendlicht_TFL_li_def 0 "OK" 1 "defekt" ;
VAL_ 1624 LV_Nebellicht_TFL_li_def 0 "OK" 1 "defekt" ;
VAL_ 1624 LV_Standlicht_TFL_li_def 0 "OK" 1 "defekt" ;
VAL_ 1624 LV_Abblend_Fernlicht_li_def 0 "OK" 1 "defekt" ;
VAL_ 1624 LV_Abblendlicht_TFL_re_def 0 "OK" 1 "defekt" ;
VAL_ 1624 LV_Nebellicht_TFL_re_def 0 "OK" 1 "defekt" ;
VAL_ 1624 LV_Standlicht_TFL_re_def 0 "OK" 1 "defekt" ;
VAL_ 1624 LV_Abblend_Fernlicht_re_def 0 "OK" 1 "defekt" ;
VAL_ 1624 LV_Abbiegelicht_li_def 0 "OK" 1 "defekt" ;
VAL_ 1624 LV_Abbiegelicht_re_def 0 "OK" 1 "defekt" ;
VAL_ 1624 BCM1_Linksverkehr 0 "Rechtsverkehr" 1 "Linksverkehr" ;
VAL_ 1624 BCM1_Licht_Dunkelheit_aktiv 0 "inaktiv" 1 "aktiv" ;
VAL_ 1624 LV_LED_Scheinwerfer_li_def 0 "OK" 1 "defekt" ;
VAL_ 1624 LV_LED_Scheinwerfer_re_def 0 "OK" 1 "defekt" ;
VAL_ 1624 LV_Blinker_VL_aktiv 0 "inaktiv" 1 "aktiv" ;
VAL_ 1624 LV_Blinker_VR_aktiv 0 "inaktiv" 1 "aktiv" ;
VAL_ 1624 LV_MXB_Status_Anzeige 0 "MXB_aus" 1 "MXB_regelt" 2 "MXB_volles_Fernlicht" 3 "MXB_und_Laser_aktiv" ;
VAL_ 134 LWI_Sensorstatus 0 "iO" 1 "nicht kalibriert" ;
VAL_ 134 LWI_QBit_Sub_Daten 0 "LWS-Subinfo real (Lenkradwinkelinformation ADS-tauglich) " 1 "LWS-Subinfo simuliert (Lenkradwinkelinformation nicht ADS-tauglich )" ;
VAL_ 134 LWI_MFL_Abschaltung 0 "inaktiv" 1 "aktiv" ;
VAL_ 134 LWI_QBit_Lenkradwinkel 0 "gültiger Wert" 1 "ausserhalb der Spezifikation" ;
VAL_ 134 LWI_Lenkradwinkel 8190 "Init" 8191 "Fehler" ;
VAL_ 134 LWI_VZ_Lenkradwinkel 0 "positiv_links_von_der_Nullstellung" 1 "negativ" ;
VAL_ 134 LWI_VZ_Lenkradw_Geschw 0 "positiv_links_von_der_Nullstellung" 1 "negativ" ;
VAL_ 134 LWI_Lenkradw_Geschw 510 "Init" 511 "Fehler" ;
VAL_ 168 MO_Mom_neg_verfuegbar 510 "Init" 511 "Fehler" ;
VAL_ 168 MO_Mom_Begr_stat 510 "Init" ;
VAL_ 168 MO_Mom_Begr_dyn 1022 "Init" ;
VAL_ 168 MO_QBit_Drehzahl_01 0 "gueltiger_Wert" 1 "Ersatz_Init_oder_Fehlerwert" ;
VAL_ 958 MO_StartStopp_Status 0 "System_in_diesem_KL15_Zyklus_nicht_verfuegbar" 1 "System_aktiv_keine_Freigabe_durch_StartStop_Koordinator" 2 "System_aktiv_alle_Freigaben_liegen_vor" 3 "System_aktiv_mindestens_eine_Freigabe_fehlt" ;
VAL_ 958 MO_StartStopp_Wiederstart 0 "Wiederstart_inaktiv" 1 "Wiederstart_aktiv" ;
VAL_ 958 MO_StartStopp_Motorstopp 0 "Motor_Stop_inaktiv" 1 "Motor_Stop_aktiv" ;
VAL_ 958 MO_Freig_Reku 0 "Rekuperations-Modus aus" 1 "Empfehlung Spannungsanhebung" 2 "Empfehlung Spannungsabsenkung" 3 "Rekuperationsmodus aktiv, Spannungsvariation nicht notwendig" ;
VAL_ 958 MO_Kl_75 0 "Aus" 1 "Ein" ;
VAL_ 958 MO_Kl_50 0 "aus" 1 "KL50_ein_Startausfuehrung_Fahrer" ;
VAL_ 958 MO_Gangposition 0 "Gang_N" 1 "Gang_1" 2 "Gang_2" 3 "Gang_3" 4 "Gang_4" 5 "Gang_5" 6 "Gang_6" 7 "Gang_7" 8 "Gang_8" 9 "Automat_P" 10 "Automat_Vorwaerts_S" 11 "Automat_Vorwaerts_D/E" 12 "Zwischenstellung" 13 "Gang_R" 14 "Istgang_nicht_definiert" 15 "Fehler" ;
VAL_ 958 MO_StartStopp_Fahrerwunsch 0 "Init" 1 "Stoppverbot_durch_Fahrer" 2 "Stoppfreigabe_durch_Fahrer" 3 "Stoppanforderung_durch_Fahrer" ;
VAL_ 958 MO_HYB_Fahrbereitschaft 0 "keine_Fahrbereitschaft" 1 "Fahrbereitschaft" ;
VAL_ 958 MO_Ext_E_Fahrt_aktiv 0 "Rueckmeldung_E_Taster_aus" 1 "Rueckmeldung_E_Taster_ein" ;
VAL_ 958 MO_Fahrer_bremst 0 "kein_Bremsen" 1 "Bremse_betaetigt" ;
VAL_ 958 MO_QBit_Fahrer_bremst 0 "gueltiger_Wert" 1 "Ersatz_Init_oder_Fehlerwert" ;
VAL_ 958 MO_BLS 0 "kein_Bremsen" 1 "Bremse_betaetigt" ;
VAL_ 958 MO_Konsistenz_Bremsped 0 "Bremspedalinformation_plausibel" 1 "Bremspedalinformation_unplausibel" ;
VAL_ 958 MO_KomFehler_ESP 0 "kein_Fehler" 1 "Fehler" ;
VAL_ 958 MO_Klima_Eingr 0 "kein Eingriff" 1 "Klimakompressor ausschalten" 2 "Klimakompressor Leistungsreduzierung" 3 "Klimakompressor aufgrund der Heissleuchtenvorwarnung ausschalten" ;
VAL_ 958 MO_Aussp_Anlass 0 "Anlasser_darf_angesteuert_werden" 1 "Anlasser_ausspuren__Ansteuerung_nicht_moeglich" ;
VAL_ 958 MO_Freig_Anlass 0 "Start_nicht_zulaessig" 1 "Startfreigabe" ;
VAL_ 958 MO_Kuppl_schalter 0 "Schalter_sagt_ausgekuppelt" 1 "Schalter_sagt_eingekuppelt" ;
VAL_ 958 MO_Interlock 0 "Interlockschalter_nicht_betaetigt" 1 "Interlockschalter_betaetigt" ;
VAL_ 958 MO_Motor_laeuft 0 "Motor_laeuft_nicht" 1 "Motor_laeuft_autark_und_stabil_und_darf_mechanisch_belastet_werden" ;
VAL_ 958 MO_Kickdown 0 "kein_Kickdown" 1 "Kickdown" ;
VAL_ 958 MO_QBit_KL_75 0 "gueltiger_Wert" 1 "Ersatz_Init_oder_Fehlerwert" ;
VAL_ 958 MO_EKlKomLeiRed 0 "keine_Leistungsbegr" 1 "Leistungsbegr_75" 2 "Leistungsbegr_50" 3 "Leistungsbegr_25" ;
VAL_ 958 MO_Handshake_STH 0 "keine EKP-Ansteuerung durch STH-Anforderung" 1 "EKP-Ansteuerung durch STH-Anforderung" ;
VAL_ 958 MO_BKV_Unterdruckwarnung 0 "Unterdruckhaushalt_iO" 1 "Unterdruckhaushalt_niO" ;
VAL_ 958 MO_Freigabe_Segeln 0 "Segelbetrieb_nicht_freigegeben" 1 "Segelbetrieb_freigegeben" ;
VAL_ 958 MO_PTC_Status 0 "nicht_unterstuetzt" 1 "Stufe_0" 2 "Stufe_1" 3 "Stufe_2" 4 "Stufe_3" 7 "PTC_am_BCM" ;
VAL_ 958 MO_QBit_Gangposition 0 "gueltiger_Wert" 1 "Ersatz_Init_oder_Fehlerwert" ;
VAL_ 958 MO_Signalquelle_Gangposition 0 "Sensorsignal" 1 "Modellsignal" ;
VAL_ 958 MO_Remotestart_Betrieb 0 "MSG_nicht_bereit_fuer_RS_Betrieb" 1 "MSG_bereit_fuer_oder_im_RS_Betrieb" ;
VAL_ 958 MO_Remotestart_moeglich 0 "Remotestart_nicht_moeglich" 1 "Remotestart_moeglich" ;
VAL_ 958 MO_Text_Geschw_red 0 "keine_Anzeige" 1 "Anzeige_Geschwindigkeitsred" ;
VAL_ 958 MO_FMAus_aktiv 0 "inaktiv" 1 "Segeln_mit_Motor_aus_aktiv" ;
VAL_ 958 MO_FMAus_Startvariante 0 "kein_Motorstart" 1 "Motorstart_elektrischer_Starter" 2 "GetriebeAnschleppstart" 3 "GetriebeNotAnschleppstart" ;
VAL_ 958 MO_BMS_NV_Anf_stuetzen 0 "nicht_notwendig" 1 "notwendig" ;
VAL_ 958 MO_Zylinderabschaltung 0 "Vollmotorbetrieb_VMB" 1 "Uebergang_HMB_in_VMB" 2 "Uebergang_VMB_in_HMB" 3 "Halbmotorbetrieb_HMB" ;
VAL_ 958 MO_HYB_VM_aktiv 0 "VM_nicht_aktiv" 1 "VM_aktiv" ;
VAL_ 958 MO_StartVorauss_erfuellt 0 "Signal_nicht_bedient" 1 "StartVorauss_nicht_ueberpruefbar" 2 "StartVorauss_nicht_erfuellt" 3 "StartVorauss_erfuellt" ;
VAL_ 1648 MO_ANC_Kennfeld_Anf 0 "Kennfeld_1" 1 "Uebergang_Kennfeld_2_nach_1" 2 "Uebergang_Kennfeld_1_nach_2" 3 "Kennfeld_2" ;
VAL_ 1648 MO_Bremslicht_Reku 0 "Aus" 1 "Ein" ;
VAL_ 1648 MO_StartStopp_PopUp 0 "Statuswechsel_ohne_Taster (Init)" 1 "StSt_per_Taster_deaktiviert" 2 "StSt_per_Taster_aktiviert" 3 "nicht verwendet" ;
VAL_ 1648 MO1_Sperr_Info_WFS 0 "nicht_gesperrt" 1 "gesperrt" ;
VAL_ 1648 MO1_Freigabe_Info_WFS 0 "ungueltig" 1 "gueltig" ;
VAL_ 1648 MO_EPCL 0 "EPCL_aus_kein_Text" 1 "EPCL_gelb_Stoerung" 2 "EPCL_gelb_Leistungsbeschraenkung" 3 "EPCL_rot_Fzg_sicher_abstellen" ;
VAL_ 1648 MO_Zylabsch_Texte_02 0 "ein_ZAS_generell_keine_ZAS_Anzeigen" 1 "ZAS_im_VMB" 2 "ZAS_im_ASB_1_Zyl_aktiv" 3 "ZAS_im_ASB_2_Zyl_aktiv" 4 "ZAS_im_ASB_3_Zyl_aktiv" 5 "ZAS_im_ASB_4_Zyl_aktiv" 6 "ZAS_im_ASB_5_Zyl_aktiv" 7 "ZAS_im_ASB_6_Zyl_aktiv" 8 "ZAS_im_ASB_8_Zyl_aktiv" 9 "ZAS_im_ASB_12_Zyl_aktiv" 13 "Uebergangsbetrieb" 14 "keine_ZAS_Anzeige_ggf_Stopp_Schub_Betrieb" 15 "ZAS_Stoerungs_Anzeige" ;
VAL_ 1648 MO_Fahrzeugtyp 0 "Verbrenner_Fahrzeug" 1 "Hybrid" 2 "E_Fahrzeug" 3 "E_Fahrzeug_mit_Range_Extender" 4 "Brennstoffzellenfahrzeug" 5 "tbd" 6 "tbd" 7 "tbd" ;
VAL_ 1648 MO_Abstellzeit 254 "Init" 255 "reserviert" ;
VAL_ 1648 MO_Abstellzeit_Status 0 "Abstellzeit_nicht_berechnet" 1 "Abstellzeit_berechnet" 2 "Abstellzeit_Minimalwert" 3 "Abstellzeit_ungueltig" ;
VAL_ 1648 MO1_Freigabe_Verfallsinfo_WFS 0 "verfaellt_nicht" 1 "verfaellt" ;
VAL_ 1648 MO_Hybrid_StartStopp_LED 0 "LED_aus_und_Blinken_aus" 1 "LED_ein_und_Blinken_aus" 2 "LED_ein_und_Blinken_ein_50_percent" 3 "reserviert" ;
VAL_ 1648 MO_Fehler_Zylabsch 0 "kein_Fehler" 1 "Notlauf_Vollmotorbetrieb" 2 "Notlauf_mindestens_einem_abgesch_Zylinder" ;
VAL_ 1648 MO_Anzahl_Abgesch_Zyl 0 "Vollmotorbetrieb" 1 "1_Zylinder_abgeschaltet" 2 "2_Zylinder_abgeschaltet" 3 "3_Zylinder_abgeschaltet" 4 "4_Zylinder_abgeschaltet" 5 "5_Zylinder_abgeschaltet" 6 "6_Zylinder_abgeschaltet" 7 "8_Zylinder_abgeschaltet" ;
VAL_ 1648 MO_Zylabsch_Texte 0 "keine_Texte" 1 "Zylinderabschaltung_deaktivieren" 2 "Zylinderabschaltung_aktivieren" 3 "Zylinderabschaltung_unruhig" ;
VAL_ 1648 MO_Ethanol_BS_Texte 0 "kein_Text" 1 "E85_Warm_Up" 2 "FlexFuel_Warnung_Stufe_3" 3 "Warmfahrempfehlung_MQB__FlexFuel_Warnung_Stufe_1" 4 "FlexFuel_Warnung_Stufe_2" 5 "FlexFuel_Warnung_Stufe_4" 6 "E25_Warm_Up" ;
VAL_ 1648 MO_Drehzahl_Warnung 0 "keinen_Warnhinweis_anzeigen" 1 "Warnhinweis_anzeigen" ;
VAL_ 1648 MO_obere_Drehzahlgrenze 0 "Init" ;
